VERSION ""

NS_ :

BS_:

BU_: RS01 SODFR SODFL SODRL SODRR SODRC
VAL_TABLE_ RS01_VEHICLE_PLATFORM 14 "RR12" 13 "RR11" 12 "G38_MSP" 11 "G38" 10 "G32_MSP" 9 "G32" 8 "G31_MSP" 7 "G31" 6 "G30_MSP" 5 "G30" 4 "G12_MSP" 3 "G12" 2 "G11_MSP" 1 "G11" 0 "G01" ;
VAL_TABLE_ CAN_TX_SW_VERSION_DSP 71426 "2.23.1" 71170 "2.22.1" 5890 "2.23" ;
VAL_TABLE_ CAN_TX_SW_VERSION_ARM 66827 "1.5.11" 66826 "1.5.10" ;
VAL_TABLE_ AUTO_ALIGN_QUALITY_FACTOR 3 "ALIGN_QUALITY_FACTOR_INACCURATE" 2 "ALIGN_QUALITY_FACTOR_FAULTY" 1 "ALIGN_QUALITY_FACTOR_ACCURATE" 0 "ALIGN_QUALITY_FACTOR_UNKNOWN " ;
VAL_TABLE_ AUTO_ALIGN_MODE 7 "ALIGN_MODE_OVERWRITE" 6 "ALIGN_MODE_STATIONARY_ALIGNMENT" 5 "ALIGN_MODE_RESUME_SPC" 4 "ALIGN_MODE_SERVICE" 3 "ALIGN_MODE_SHORT_TRACK" 2 "ALIGN_MODE_AUTO" 1 "ALIGN_MODE_INIT" 0 "ALIGN_MODE_OFF" ;
VAL_TABLE_ LANE_CALC_METHOD 6 "LANE_CALC_CAMERA_FALLBACK_DEF" 5 "LANE_CALC_CAMERA_FALLBACK_EXT" 4 "LANE_CALC_CAMERA_FALLBACK_BASIC" 3 "LANE_CALC_CAMERA" 2 "LANE_CALC_EXTENDED" 1 "LANE_CALC_BASIC" 0 "LANE_CALC_METHOD_DEFAULT" ;
VAL_TABLE_ Radiation_Control 2 "Radiation Automatic" 1 "Radiation ON" 0 "Radiation OFF" ;
VAL_TABLE_ DRIVING_ENVIRONMENT 2 "RURAL" 1 "CITY" 0 "Unknown" ;
VAL_TABLE_ RS01_FUNCTION_STATUS 3 "ERROR" 2 "DEGRADED" 1 "NORMAL_OPERATION" 0 "STANDBY" ;
VAL_TABLE_ RS01_SYSTEM_STATUS 3 "POWERDOWN" 2 "SYSTEMUP" 1 "STARTUP/ INIT" 0 "OFF" ;
VAL_TABLE_ Quality_Factor_T 3 "Accurate" 2 "Not Accurate" 1 "Temp Undefined" 0 "Undefined" ;
VAL_TABLE_ System_Status_T 6 "Hot" 5 "ShutDown" 4 "Faulty" 3 "Blocked" 2 "Running" 1 "StartUp" 0 "Configuration" ;
VAL_TABLE_ ARM_diagnostic_byte7 7 "Num errors" 6 "Always true" 5 "cal DSP obsolete=62 error" ;
VAL_TABLE_ ARM_diagnostic_byte5 2 "Interrupt enable error" 1 "HIL format error" 0 "MMAP memroy error" ;
VAL_TABLE_ ARM_diagnostic_byte4 7 "Socket write error" 6 "Socket rear error" 5 "Socket init error" 4 "ISR attach error" 3 "DSP load address error" 2 "DSP load read error" 1 "DSP load open error" 0 "DSP init error" ;
VAL_TABLE_ ARM_diagnostic_byte3 7 "IPC DRV trigger error" 6 "IPC DRV sync error" 5 "IPC DRV write error" 4 "IPC DRV read error" 3 "IPC DRV init error" 2 "DSP DRV start error" 1 "DSP DRV load error" 0 "DSP DRV init2 error" ;
VAL_TABLE_ ARM_diagnostic_byte2 7 "DSP DRV init1 error" 6 "DSP DRV init error" 5 "Shared memory write error" 4 "Shared memory read error" 3 "Shared memory config error" 2 "Shared memory init error" 1 "DSP IPC write error" 0 "DSP IPC read error" ;
VAL_TABLE_ ARM_diagnostic_byte1 7 "DSP IPC Init" 6 "SPI FEE error" 5 "SPI comm error" 4 "CAN hardware error" 3 "CAN rcv error" 2 "CAN XMT error" 1 "ARM calibration error" 0 "DSP calibration error" ;
VAL_TABLE_ ARM_diagnostic_byte0 7 "flash filesystem error" 6 "timer create error" 5 "signal send error" 4 "signal wait error" 3 "signal create error" 2 "thread create error" 1 "ram test error" 0 "error none" ;
VAL_TABLE_ DSP_Diagnostics_byte2 7 "Video Port data capture error" 6 "TX temperature fault" 5 "DSP unit cal block fault" 4 "DSP unit cal checksum error" 3 "Vertical misalignment error" 2 "RTN SPI transfer error" 1 "RRN SPI transfer error" 0 "Linearizer SPI transfer error" ;
VAL_TABLE_ DSP_Diagnostics_byte1 7 "ADC SPI transfer error" 6 "transmitter ID error" 5 "DSP loop overrun error" 4 "saturated tuning frquency error" 3 "radar data sync error" 2 "DSP Tuning Sensitivity error" 1 "radar LO power error" 0 "Radar_tx_power_error" ;
VAL_TABLE_ GroupingChanged 1 "GroupingChanged" 0 "GroupingUnchanged" ;
VAL_TABLE_ Oncoming 1 "Oncoming" 0 "NotOncoming" ;
VAL_TABLE_ UPDATED 1 "Updated" 0 "Not_Updated" ;
VAL_TABLE_ FOUND_TARGET 1 "Found" 0 "Not_Found" ;
VAL_TABLE_ FACTORY_ALIGN_STATUS 5 "FAIL_VAR_TOO_LARGE" 4 "FAIL_DEV_TOO_LARGE" 3 "FAIL_NO_TARGET" 2 "SUCCESS" 1 "BUSY" 0 "OFF" ;
VAL_TABLE_ RECOMMEND 1 "Recommend" 0 "Not_Recommend" ;
VAL_TABLE_ SA_TYPE 1 "VOLVO_SHORT_TRACK" 0 "AUTO_OR_DEALER" ;
VAL_TABLE_ ENABLE 1 "Enabled" 0 "Disabled" ;
VAL_TABLE_ CONVERGED 1 "Converged" 0 "Not_Converged" ;
VAL_TABLE_ TURN_SIGNAL_STATUS 3 "Invalid_3" 2 "Right" 1 "Left" 0 "Off" ;
VAL_TABLE_ DISABLE 1 "Disabled" 0 "Enabled" ;
VAL_TABLE_ SYSTEM_POWER_MODE 7 "7invalid" 6 "TEST" 5 "HOST_SHUTDOWN" 4 "DSP_OFF" 3 "DSP_SHUTDOWN" 2 "RADIATE_ON" 1 "RADIATE_OFF" 0 "DSP_INIT" ;
VAL_TABLE_ Water_Spray_Detected 1 "Spray" 0 "No_Spray" ;
VAL_TABLE_ Bridge 1 "Bridge" 0 "Not_Bridge" ;
VAL_TABLE_ MED_RANGE_MODE 3 "Both_MR_LR_Update" 2 "LR_Update_Only" 1 "MR_Update_Only" 0 "No_MR_LR_Update" ;
VAL_TABLE_ Interface_Version 15 "zInvalid0F" 14 "zInvalid0E" 13 "zInvalid0D" 12 "zInvalid0C" 11 "zInvalid0B" 10 "zInvalid0A" 9 "zInvalid09" 8 "zInvalid08" 7 "zInvalid07" 6 "zInvalid06" 5 "zInvalid05" 4 "zInvalid04" 3 "zInvalid03" 2 "zInvalid02" 1 "ADP_DV1" 0 "TDP" ;
VAL_TABLE_ SIM_STATUS 3 "Coasted" 2 "Updated" 1 "New" 0 "Invalid" ;
VAL_TABLE_ SIM_TRACK_ID 2 "Target_2" 1 "Target_1" 0 "No_Target" ;
VAL_TABLE_ SIM_FUNCTION 7 "All_Stat_RI_FCW_CMbB" 6 "All_Moving_ACC_FCW_CMbB" 5 "CMbB_Stat" 4 "CMbB_Move" 3 "FCW_Stat" 2 "FCW_Move" 1 "RI" 0 "ACC" ;
VAL_TABLE_ UPSIDE_DOWN 1 "Upside_Down" 0 "Right_Side_Up" ;
VAL_TABLE_ MR_LR_MODE 3 "Output MR and LR tracks" 2 "Output only LR-range tracks" 1 "Output only MR-range tracks" 0 "Reserved" ;
VAL_TABLE_ GROUP 3 "Group4" 2 "Group3" 1 "Group2" 0 "Group1" ;
VAL_TABLE_ NODETECT_DETECT 1 "Detect" 0 "No_Detect" ;
VAL_TABLE_ TRACK_STATUS 7 "New_Coasted_Target" 6 "Invalid_Coasted_Target" 5 "Merged_Target" 4 "Coasted_Target" 3 "Updated_Target" 2 "New_Updated_Target" 1 "New_Target" 0 "No_Target" ;
VAL_TABLE_ NOTCROSSING_CROSSING 1 "Crossing" 0 "Not_Crossing" ;
VAL_TABLE_ NOTMOVABLE_MOVABLE 1 "Movable" 0 "Not_Movable" ;
VAL_TABLE_ STATIONARY_MOVING 1 "Moving" 0 "Stationary" ;
VAL_TABLE_ NOTOVERTEMP_OVERTEMP 1 "OverTemp" 0 "Not OverTemp" ;
VAL_TABLE_ NOTBLOCKED_BLOCKED 1 "Blocked" 0 "Not Blocked" ;
VAL_TABLE_ NOTFAIL_FAIL 1 "Failed" 0 "Not Failed" ;
VAL_TABLE_ UNGROUPED_GROUPED 3 "Group_Moving_Stationary" 2 "Group_Stationary_Only" 1 "Group_Moving_Only" 0 "No_Grouping" ;
VAL_TABLE_ FILTERED_RAW 1 "Raw" 0 "Filtered" ;
VAL_TABLE_ OFF_ON 1 "On" 0 "Off" ;
VAL_TABLE_ SW_SIGN 1 "Clockwise" 0 "Counterclockwise" ;
VAL_TABLE_ VALIDITY 1 "Valid" 0 "Invalid" ;
VAL_TABLE_ VEHICLE_SPEED_DIRECTION 1 "Reverse" 0 "Forward" ;
VAL_TABLE_ STATUS_PRECRASH_TABLE 4 "Collision unavoidable" 2 "Collision probable" 1 "Collision avoidable" 0 "no relevant Object" ;
VAL_TABLE_ STATUS_RECW_TABLE 1 "Warning active" 0 "No Warning" ;
VAL_TABLE_ TRIGGER_SENSOR 0 "INVALID_TRIGGER" 1 "TRIGGERED_BY_REAR_LEFT" 2 "TRIGGERED_BY_REAR_RIGHT" 3 "TRIGGERED_BY_FRONT_RIGHT" 4 "TRIGGERED_BY_FRONT_LEFT" 5 "TRIGGERED_BY_REAR_CENTER" 6 "TRIGGERED_BY_DSP" ;

BO_ 3221225472 VECTOR__INDEPENDENT_SIG_MSG: 0 Vector__XXX
 SG_ CAN_TX_LOOK_TYPE : 0|1@0+ (1,0) [0|0] "" Vector__XXX
 SG_ CAN_TX_SYSTEM_SYNC_TIME : 0|32@0+ (1,0) [0|0] "" Vector__XXX
 SG_ ITS_DAQ1_data : 0|64@0+ (1,0) [0|0] "" Vector__XXX
 SG_ CAN_RX_MR_LR_MODE : 0|2@0+ (1,0) [0|3] "" Vector__XXX
 SG_ CAN_TX_DELTA_TIME_STAMP : 0|7@0- (1,0) [-64|63] "ms" Vector__XXX
 SG_ CAN_RX_MASTER_CLOCK : 0|16@0+ (1,0) [0|65535] "ms" Vector__XXX
 SG_ CAN_TX_WATER_SPRAY_TARGET_ID : 0|8@0+ (1,0) [0|0] "" Vector__XXX
 SG_ CAN_TX_TRACK_LAT_RATE : 0|6@0- (0.25,0) [-8|7.75] "" Vector__XXX
 SG_ CAN_TX_TRACK_BRIDGE_OBJECT : 0|1@0+ (1,0) [0|0] "" Vector__XXX
 SG_ CAN_TX_TRACK_WIDTH : 0|4@0+ (0.5,0) [0|7.5] "m" Vector__XXX
 SG_ CAN_TX_TRACK_STATUS : 0|3@0+ (1,0) [0|7] "" Vector__XXX
 SG_ CAN_TX_TRACK_RANGE_RATE : 0|14@0- (0.01,0) [-81.92|81.91] "m/s" Vector__XXX
 SG_ CAN_TX_TRACK_RANGE : 0|11@0+ (0.1,0) [0|204.7] "m" Vector__XXX
 SG_ CAN_TX_TRACK_MED_RANGE_MODE : 0|2@0+ (1,0) [0|3] "" Vector__XXX
 SG_ CAN_TX_TRACK_GROUPING_CHANGED : 0|1@0+ (1,0) [0|0] "" Vector__XXX
 SG_ CAN_TX_TRACK_ONCOMING : 0|1@0+ (1,0) [0|0] "" Vector__XXX
 SG_ CTA_Aware : 0|2@0+ (1,0) [0|0] "binary" Vector__XXX
 SG_ CAN_TX_TRACK_ROLLING_COUNT : 0|1@0+ (1,0) [0|1] "" Vector__XXX
 SG_ CAN_TX_TRACK_RANGE_ACCEL : 0|10@0- (0.05,0) [-25.6|25.55] "m/s/s" Vector__XXX
 SG_ CAN_TX_ROLLING_COUNT_3 : 0|2@0+ (1,0) [0|0] "" Vector__XXX
 SG_ CAN_TX_ROLLING_COUNT_3 : 0|2@0+ (1,0) [0|0] "" Vector__XXX
 SG_ CAN_TX_ROLLING_COUNT_1 : 0|2@0+ (1,0) [0|0] "" Vector__XXX
 SG_ DSP_diagnostic_byte2 : 0|8@0+ (1,0) [0|0] "" Vector__XXX
 SG_ DSP_diagnostic_byte1 : 0|8@0+ (1,0) [0|0] "" Vector__XXX
 SG_ DSP_diagnostic_byte2 : 0|8@0+ (1,0) [0|0] "" Vector__XXX
 SG_ DSP_diagnostic_byte1 : 0|8@0+ (1,0) [0|0] "" Vector__XXX
 SG_ New_Signal_1125 : 0|8@1+ (1,0) [0|0] "" Vector__XXX
 SG_ New_Signal_1124 : 0|8@1+ (1,0) [0|0] "" Vector__XXX
 SG_ New_Signal_1123 : 0|8@1+ (1,0) [0|0] "" Vector__XXX
 SG_ CAN_TX_DSP_TIMESTAMP : 0|16@0+ (2,0) [0|131070] "ms" Vector__XXX
 SG_ CAN_TX_DSP_TIMESTAMP : 0|16@0+ (2,0) [0|131070] "ms" Vector__XXX
 SG_ Timer_Create_Error : 0|1@0+ (1,0) [0|0] "" Vector__XXX
 SG_ Thread_Create_Error : 0|1@0+ (1,0) [0|0] "" Vector__XXX
 SG_ ARM_Calibration_Error : 0|1@0+ (1,0) [0|0] "" Vector__XXX
 SG_ SPI_FEE_Error : 0|1@0+ (1,0) [0|0] "" Vector__XXX
 SG_ SPI_Comm_Error : 0|1@0+ (1,0) [0|0] "" Vector__XXX
 SG_ Socket_Write_Error : 0|1@0+ (1,0) [0|0] "" Vector__XXX
 SG_ DSP_Cal_Obsolete_62_Error : 0|1@0+ (1,0) [0|0] "" Vector__XXX
 SG_ Socket_Read_error : 0|1@0+ (1,0) [0|0] "" Vector__XXX
 SG_ Socket_Init_Error : 0|1@0+ (1,0) [0|0] "" Vector__XXX
 SG_ Signal_Wait_Error : 0|1@0+ (1,0) [0|0] "" Vector__XXX
 SG_ Signal_Send_Error : 0|1@0+ (1,0) [0|0] "" Vector__XXX
 SG_ Signal_Create_Error : 0|1@0+ (1,0) [0|0] "" Vector__XXX
 SG_ Shared_Mem_Write_Error : 0|1@0+ (1,0) [0|0] "" Vector__XXX
 SG_ Shared_Mem_Read_Error : 0|1@0+ (1,0) [0|0] "" Vector__XXX
 SG_ Shared_Mem_Config_Error : 0|1@0+ (1,0) [0|0] "" Vector__XXX
 SG_ Share_Mem_Init_Error : 0|1@0+ (1,0) [0|0] "" Vector__XXX
 SG_ RAM_Test_Error : 0|1@0+ (1,0) [0|0] "" Vector__XXX
 SG_ Num_Errors : 0|1@0+ (1,0) [0|0] "" Vector__XXX
 SG_ MMAP_Memory_Error : 0|1@0+ (1,0) [0|0] "" Vector__XXX
 SG_ ISR_Attach_Error : 0|1@0+ (1,0) [0|0] "" Vector__XXX
 SG_ IPC_DRV_Write_Error : 0|1@0+ (1,0) [0|0] "" Vector__XXX
 SG_ IPC_DRV_Trigger_Error : 0|1@0+ (1,0) [0|0] "" Vector__XXX
 SG_ IPC_DRV_Sync_Error : 0|1@0+ (1,0) [0|0] "" Vector__XXX
 SG_ IPC_DRV_Read_Error : 0|1@0+ (1,0) [0|0] "" Vector__XXX
 SG_ IPC_DRV_Init_Error : 0|1@0+ (1,0) [0|0] "" Vector__XXX
 SG_ Interrupt_Enable_Error : 0|1@0+ (1,0) [0|0] "" Vector__XXX
 SG_ HIL_Format_Error : 0|1@0+ (1,0) [0|0] "" Vector__XXX
 SG_ Flash_Filesystem_Error : 0|1@0+ (1,0) [0|0] "" Vector__XXX
 SG_ Error_none : 0|1@0+ (1,0) [0|0] "" Vector__XXX
 SG_ DSP_Load_Read_Error : 0|1@0+ (1,0) [0|0] "" Vector__XXX
 SG_ DSP_Load_Open_Error : 0|1@0+ (1,0) [0|0] "" Vector__XXX
 SG_ DSP_Load_Address_Error : 0|1@0+ (1,0) [0|0] "" Vector__XXX
 SG_ DSP_ISP_Write_Error : 0|1@0+ (1,0) [0|0] "" Vector__XXX
 SG_ DSP_IPC_Read_Error : 0|1@0+ (1,0) [0|0] "" Vector__XXX
 SG_ DSP_IPC_Init : 0|1@0+ (1,0) [0|0] "" Vector__XXX
 SG_ DSP_Init_Error : 0|1@0+ (1,0) [0|0] "" Vector__XXX
 SG_ DSP_DRV_Start_Error : 0|1@0+ (1,0) [0|0] "" Vector__XXX
 SG_ DSP_DRV_Load_Error : 0|1@0+ (1,0) [0|0] "" Vector__XXX
 SG_ DSP_DRV_Init_Error : 0|1@0+ (1,0) [0|0] "" Vector__XXX
 SG_ DSP_DRV_Init2_error : 0|1@0+ (1,0) [0|0] "" Vector__XXX
 SG_ DSP_DRV_Init1_error : 0|1@0+ (1,0) [0|0] "" Vector__XXX
 SG_ DSP_Calibration_Error : 0|1@0+ (1,0) [0|0] "" Vector__XXX
 SG_ CAN_XMT_Error : 0|1@0+ (1,0) [0|0] "" Vector__XXX
 SG_ CAN_RCV_Error : 0|1@0+ (1,0) [0|0] "" Vector__XXX
 SG_ CAN_Hardware_Error : 0|1@0+ (1,0) [0|0] "" Vector__XXX
 SG_ Always_True : 0|1@0+ (1,0) [0|0] "" Vector__XXX
 SG_ Timer_Create_Error : 0|1@0+ (1,0) [0|0] "" Vector__XXX
 SG_ Thread_Create_Error : 0|1@0+ (1,0) [0|0] "" Vector__XXX
 SG_ ARM_Calibration_Error : 0|1@0+ (1,0) [0|0] "" Vector__XXX
 SG_ SPI_FEE_Error : 0|1@0+ (1,0) [0|0] "" Vector__XXX
 SG_ SPI_Comm_Error : 0|1@0+ (1,0) [0|0] "" Vector__XXX
 SG_ Socket_Write_Error : 0|1@0+ (1,0) [0|0] "" Vector__XXX
 SG_ DSP_Cal_Obsolete_62_Error : 0|1@0+ (1,0) [0|0] "" Vector__XXX
 SG_ Socket_Read_error : 0|1@0+ (1,0) [0|0] "" Vector__XXX
 SG_ Socket_Init_Error : 0|1@0+ (1,0) [0|0] "" Vector__XXX
 SG_ Signal_Wait_Error : 0|1@0+ (1,0) [0|0] "" Vector__XXX
 SG_ Signal_Send_Error : 0|1@0+ (1,0) [0|0] "" Vector__XXX
 SG_ Signal_Create_Error : 0|1@0+ (1,0) [0|0] "" Vector__XXX
 SG_ Shared_Mem_Write_Error : 0|1@0+ (1,0) [0|0] "" Vector__XXX
 SG_ Shared_Mem_Read_Error : 0|1@0+ (1,0) [0|0] "" Vector__XXX
 SG_ Shared_Mem_Config_Error : 0|1@0+ (1,0) [0|0] "" Vector__XXX
 SG_ Share_Mem_Init_Error : 0|1@0+ (1,0) [0|0] "" Vector__XXX
 SG_ RAM_Test_Error : 0|1@0+ (1,0) [0|0] "" Vector__XXX
 SG_ Num_Errors : 0|1@0+ (1,0) [0|0] "" Vector__XXX
 SG_ MMAP_Memory_Error : 0|1@0+ (1,0) [0|0] "" Vector__XXX
 SG_ ISR_Attach_Error : 0|1@0+ (1,0) [0|0] "" Vector__XXX
 SG_ IPC_DRV_Write_Error : 0|1@0+ (1,0) [0|0] "" Vector__XXX
 SG_ IPC_DRV_Trigger_Error : 0|1@0+ (1,0) [0|0] "" Vector__XXX
 SG_ IPC_DRV_Sync_Error : 0|1@0+ (1,0) [0|0] "" Vector__XXX
 SG_ IPC_DRV_Read_Error : 0|1@0+ (1,0) [0|0] "" Vector__XXX
 SG_ IPC_DRV_Init_Error : 0|1@0+ (1,0) [0|0] "" Vector__XXX
 SG_ Interrupt_Enable_Error : 0|1@0+ (1,0) [0|0] "" Vector__XXX
 SG_ HIL_Format_Error : 0|1@0+ (1,0) [0|0] "" Vector__XXX
 SG_ Flash_Filesystem_Error : 0|1@0+ (1,0) [0|0] "" Vector__XXX
 SG_ Error_none : 0|1@0+ (1,0) [0|0] "" Vector__XXX
 SG_ DSP_Load_Read_Error : 0|1@0+ (1,0) [0|0] "" Vector__XXX
 SG_ DSP_Load_Open_Error : 0|1@0+ (1,0) [0|0] "" Vector__XXX
 SG_ DSP_Load_Address_Error : 0|1@0+ (1,0) [0|0] "" Vector__XXX
 SG_ DSP_ISP_Write_Error : 0|1@0+ (1,0) [0|0] "" Vector__XXX
 SG_ DSP_IPC_Read_Error : 0|1@0+ (1,0) [0|0] "" Vector__XXX
 SG_ DSP_IPC_Init : 0|1@0+ (1,0) [0|0] "" Vector__XXX
 SG_ DSP_Init_Error : 0|1@0+ (1,0) [0|0] "" Vector__XXX
 SG_ DSP_DRV_Start_Error : 0|1@0+ (1,0) [0|0] "" Vector__XXX
 SG_ DSP_DRV_Load_Error : 0|1@0+ (1,0) [0|0] "" Vector__XXX
 SG_ DSP_DRV_Init_Error : 0|1@0+ (1,0) [0|0] "" Vector__XXX
 SG_ DSP_DRV_Init2_error : 0|1@0+ (1,0) [0|0] "" Vector__XXX
 SG_ DSP_DRV_Init1_error : 0|1@0+ (1,0) [0|0] "" Vector__XXX
 SG_ DSP_Calibration_Error : 0|1@0+ (1,0) [0|0] "" Vector__XXX
 SG_ CAN_XMT_Error : 0|1@0+ (1,0) [0|0] "" Vector__XXX
 SG_ CAN_RCV_Error : 0|1@0+ (1,0) [0|0] "" Vector__XXX
 SG_ CAN_Hardware_Error : 0|1@0+ (1,0) [0|0] "" Vector__XXX
 SG_ Always_True : 0|1@0+ (1,0) [0|0] "" Vector__XXX
 SG_ Timer_Create_Error : 0|1@0+ (1,0) [0|0] "" Vector__XXX
 SG_ Thread_Create_Error : 0|1@0+ (1,0) [0|0] "" Vector__XXX
 SG_ ARM_Calibration_Error : 0|1@0+ (1,0) [0|0] "" Vector__XXX
 SG_ SPI_FEE_Error : 0|1@0+ (1,0) [0|0] "" Vector__XXX
 SG_ SPI_Comm_Error : 0|1@0+ (1,0) [0|0] "" Vector__XXX
 SG_ Socket_Write_Error : 0|1@0+ (1,0) [0|0] "" Vector__XXX
 SG_ DSP_Cal_Obsolete_62_Error : 0|1@0+ (1,0) [0|0] "" Vector__XXX
 SG_ Socket_Read_error : 0|1@0+ (1,0) [0|0] "" Vector__XXX
 SG_ Socket_Init_Error : 0|1@0+ (1,0) [0|0] "" Vector__XXX
 SG_ Signal_Wait_Error : 0|1@0+ (1,0) [0|0] "" Vector__XXX
 SG_ Signal_Send_Error : 0|1@0+ (1,0) [0|0] "" Vector__XXX
 SG_ Signal_Create_Error : 0|1@0+ (1,0) [0|0] "" Vector__XXX
 SG_ Shared_Mem_Write_Error : 0|1@0+ (1,0) [0|0] "" Vector__XXX
 SG_ Shared_Mem_Read_Error : 0|1@0+ (1,0) [0|0] "" Vector__XXX
 SG_ Shared_Mem_Config_Error : 0|1@0+ (1,0) [0|0] "" Vector__XXX
 SG_ Share_Mem_Init_Error : 0|1@0+ (1,0) [0|0] "" Vector__XXX
 SG_ RAM_Test_Error : 0|1@0+ (1,0) [0|0] "" Vector__XXX
 SG_ Num_Errors : 0|1@0+ (1,0) [0|0] "" Vector__XXX
 SG_ MMAP_Memory_Error : 0|1@0+ (1,0) [0|0] "" Vector__XXX
 SG_ ISR_Attach_Error : 0|1@0+ (1,0) [0|0] "" Vector__XXX
 SG_ IPC_DRV_Write_Error : 0|1@0+ (1,0) [0|0] "" Vector__XXX
 SG_ IPC_DRV_Trigger_Error : 0|1@0+ (1,0) [0|0] "" Vector__XXX
 SG_ IPC_DRV_Sync_Error : 0|1@0+ (1,0) [0|0] "" Vector__XXX
 SG_ IPC_DRV_Read_Error : 0|1@0+ (1,0) [0|0] "" Vector__XXX
 SG_ IPC_DRV_Init_Error : 0|1@0+ (1,0) [0|0] "" Vector__XXX
 SG_ Interrupt_Enable_Error : 0|1@0+ (1,0) [0|0] "" Vector__XXX
 SG_ HIL_Format_Error : 0|1@0+ (1,0) [0|0] "" Vector__XXX
 SG_ Flash_Filesystem_Error : 0|1@0+ (1,0) [0|0] "" Vector__XXX
 SG_ Error_none : 0|1@0+ (1,0) [0|0] "" Vector__XXX
 SG_ DSP_Load_Read_Error : 0|1@0+ (1,0) [0|0] "" Vector__XXX
 SG_ DSP_Load_Open_Error : 0|1@0+ (1,0) [0|0] "" Vector__XXX
 SG_ DSP_Load_Address_Error : 0|1@0+ (1,0) [0|0] "" Vector__XXX
 SG_ DSP_ISP_Write_Error : 0|1@0+ (1,0) [0|0] "" Vector__XXX
 SG_ DSP_IPC_Read_Error : 0|1@0+ (1,0) [0|0] "" Vector__XXX
 SG_ DSP_IPC_Init : 0|1@0+ (1,0) [0|0] "" Vector__XXX
 SG_ DSP_Init_Error : 0|1@0+ (1,0) [0|0] "" Vector__XXX
 SG_ DSP_DRV_Start_Error : 0|1@0+ (1,0) [0|0] "" Vector__XXX
 SG_ DSP_DRV_Load_Error : 0|1@0+ (1,0) [0|0] "" Vector__XXX
 SG_ DSP_DRV_Init_Error : 0|1@0+ (1,0) [0|0] "" Vector__XXX
 SG_ DSP_DRV_Init2_error : 0|1@0+ (1,0) [0|0] "" Vector__XXX
 SG_ DSP_DRV_Init1_error : 0|1@0+ (1,0) [0|0] "" Vector__XXX
 SG_ DSP_Calibration_Error : 0|1@0+ (1,0) [0|0] "" Vector__XXX
 SG_ CAN_XMT_Error : 0|1@0+ (1,0) [0|0] "" Vector__XXX
 SG_ CAN_RCV_Error : 0|1@0+ (1,0) [0|0] "" Vector__XXX
 SG_ CAN_Hardware_Error : 0|1@0+ (1,0) [0|0] "" Vector__XXX
 SG_ Always_True : 0|1@0+ (1,0) [0|0] "" Vector__XXX
 SG_ CAN_TX_ALIGN_UPDATES : 0|16@0+ (1,0) [0|0] "" Vector__XXX
 SG_ CAN_TX_ALIGN_UPDATES : 0|16@0+ (1,0) [0|0] "" Vector__XXX
 SG_ Timer_Create_Error : 0|1@0+ (1,0) [0|0] "" Vector__XXX
 SG_ Thread_Create_Error : 0|1@0+ (1,0) [0|0] "" Vector__XXX
 SG_ ARM_Calibration_Error : 0|1@0+ (1,0) [0|0] "" Vector__XXX
 SG_ SPI_FEE_Error : 0|1@0+ (1,0) [0|0] "" Vector__XXX
 SG_ SPI_Comm_Error : 0|1@0+ (1,0) [0|0] "" Vector__XXX
 SG_ Socket_Write_Error : 0|1@0+ (1,0) [0|0] "" Vector__XXX
 SG_ DSP_Cal_Obsolete_62_Error : 0|1@0+ (1,0) [0|0] "" Vector__XXX
 SG_ Socket_Read_error : 0|1@0+ (1,0) [0|0] "" Vector__XXX
 SG_ Socket_Init_Error : 0|1@0+ (1,0) [0|0] "" Vector__XXX
 SG_ Signal_Wait_Error : 0|1@0+ (1,0) [0|0] "" Vector__XXX
 SG_ Signal_Send_Error : 0|1@0+ (1,0) [0|0] "" Vector__XXX
 SG_ Signal_Create_Error : 0|1@0+ (1,0) [0|0] "" Vector__XXX
 SG_ Shared_Mem_Write_Error : 0|1@0+ (1,0) [0|0] "" Vector__XXX
 SG_ Shared_Mem_Read_Error : 0|1@0+ (1,0) [0|0] "" Vector__XXX
 SG_ Shared_Mem_Config_Error : 0|1@0+ (1,0) [0|0] "" Vector__XXX
 SG_ Share_Mem_Init_Error : 0|1@0+ (1,0) [0|0] "" Vector__XXX
 SG_ RAM_Test_Error : 0|1@0+ (1,0) [0|0] "" Vector__XXX
 SG_ Num_Errors : 0|1@0+ (1,0) [0|0] "" Vector__XXX
 SG_ MMAP_Memory_Error : 0|1@0+ (1,0) [0|0] "" Vector__XXX
 SG_ ISR_Attach_Error : 0|1@0+ (1,0) [0|0] "" Vector__XXX
 SG_ IPC_DRV_Write_Error : 0|1@0+ (1,0) [0|0] "" Vector__XXX
 SG_ IPC_DRV_Trigger_Error : 0|1@0+ (1,0) [0|0] "" Vector__XXX
 SG_ IPC_DRV_Sync_Error : 0|1@0+ (1,0) [0|0] "" Vector__XXX
 SG_ IPC_DRV_Read_Error : 0|1@0+ (1,0) [0|0] "" Vector__XXX
 SG_ IPC_DRV_Init_Error : 0|1@0+ (1,0) [0|0] "" Vector__XXX
 SG_ Interrupt_Enable_Error : 0|1@0+ (1,0) [0|0] "" Vector__XXX
 SG_ HIL_Format_Error : 0|1@0+ (1,0) [0|0] "" Vector__XXX
 SG_ Flash_Filesystem_Error : 0|1@0+ (1,0) [0|0] "" Vector__XXX
 SG_ Error_none : 0|1@0+ (1,0) [0|0] "" Vector__XXX
 SG_ DSP_Load_Read_Error : 0|1@0+ (1,0) [0|0] "" Vector__XXX
 SG_ DSP_Load_Open_Error : 0|1@0+ (1,0) [0|0] "" Vector__XXX
 SG_ DSP_Load_Address_Error : 0|1@0+ (1,0) [0|0] "" Vector__XXX
 SG_ DSP_ISP_Write_Error : 0|1@0+ (1,0) [0|0] "" Vector__XXX
 SG_ DSP_IPC_Read_Error : 0|1@0+ (1,0) [0|0] "" Vector__XXX
 SG_ DSP_IPC_Init : 0|1@0+ (1,0) [0|0] "" Vector__XXX
 SG_ DSP_Init_Error : 0|1@0+ (1,0) [0|0] "" Vector__XXX
 SG_ DSP_DRV_Start_Error : 0|1@0+ (1,0) [0|0] "" Vector__XXX
 SG_ DSP_DRV_Load_Error : 0|1@0+ (1,0) [0|0] "" Vector__XXX
 SG_ DSP_DRV_Init_Error : 0|1@0+ (1,0) [0|0] "" Vector__XXX
 SG_ DSP_DRV_Init2_error : 0|1@0+ (1,0) [0|0] "" Vector__XXX
 SG_ DSP_DRV_Init1_error : 0|1@0+ (1,0) [0|0] "" Vector__XXX
 SG_ DSP_Calibration_Error : 0|1@0+ (1,0) [0|0] "" Vector__XXX
 SG_ CAN_XMT_Error : 0|1@0+ (1,0) [0|0] "" Vector__XXX
 SG_ CAN_RCV_Error : 0|1@0+ (1,0) [0|0] "" Vector__XXX
 SG_ CAN_Hardware_Error : 0|1@0+ (1,0) [0|0] "" Vector__XXX
 SG_ Always_True : 0|1@0+ (1,0) [0|0] "" Vector__XXX
 SG_ CAN_TX_YAW_RATE_REF_QF : 0|2@0+ (1,0) [0|0] "" Vector__XXX
 SG_ CAN_TX_YAW_RATE_RAW_QF : 0|2@0+ (1,0) [0|0] "" Vector__XXX
 SG_ CAN_TX_YAW_RATE_REFERENCE : 0|12@0- (0.0625,0) [-128|127.9375] "deg/s" Vector__XXX
 SG_ CAN_TX_YAW_RATE_RAW : 0|12@0- (0.0625,0) [-128|127.9375] "deg/s" Vector__XXX
 SG_ CAN_TX_SYSTEM_STATUS : 0|3@0+ (1,0) [0|0] "" Vector__XXX
 SG_ CAN_TX_OUTSIDE_TEMPERATURE : 0|8@0+ (1,-40) [-40|215] "degC" Vector__XXX
 SG_ CAN_BLOCKAGE_MNR_BLOCKED : 0|1@0+ (1,0) [0|0] "" Vector__XXX
 SG_ CAN_BLOCKAGE_BB_BLOCKED : 0|1@0+ (1,0) [0|0] "" Vector__XXX
 SG_ CAN_BLOCKAGE_RADAR_BLOCKED : 0|1@0+ (1,0) [0|0] "" Vector__XXX
 SG_ CAN_TD_BLOCKED : 0|1@0+ (1,0) [0|0] "" Vector__XXX
 SG_ Radar_TX_Power_Error : 0|1@0+ (1,0) [0|0] "" Vector__XXX
 SG_ Radar_LO_Power_Error : 0|1@0+ (1,0) [0|0] "" Vector__XXX
 SG_ Radar_Data_sync_error : 0|1@0+ (1,0) [0|0] "" Vector__XXX
 SG_ Linearizer_SPI_Transfer_Error : 0|1@0+ (1,0) [0|0] "" Vector__XXX
 SG_ Saturated_Tuning_Freq_Error : 0|1@0+ (1,0) [0|0] "" Vector__XXX
 SG_ RTN_SPI_Transfer_Error : 0|1@0+ (1,0) [0|0] "" Vector__XXX
 SG_ RRN_SPI_Transfer_Error : 0|1@0+ (1,0) [0|0] "" Vector__XXX
 SG_ Video_Port_Capture_Error : 0|1@0+ (1,0) [0|0] "" Vector__XXX
 SG_ Vertical_Misalignment_error : 0|1@0+ (1,0) [0|0] "" Vector__XXX
 SG_ TX_Temperature_Fault : 0|1@0+ (1,0) [0|0] "" Vector__XXX
 SG_ Transmitter_ID_Error : 0|1@0+ (1,0) [0|0] "" Vector__XXX
 SG_ DSP_Unit_Cal_Checksum_Error : 0|1@0+ (1,0) [0|0] "" Vector__XXX
 SG_ DSP_Unit_Cal_Block_Chcksm_Error : 0|1@0+ (1,0) [0|0] "" Vector__XXX
 SG_ DSP_Tuning_Sensitivity_Error : 0|1@0+ (1,0) [0|0] "" Vector__XXX
 SG_ ADC_SPI_Transfer_Error : 0|1@0+ (1,0) [0|0] "" Vector__XXX
 SG_ CAN_TX_YAW_RATE_REF_QF : 0|2@0+ (1,0) [0|0] "" Vector__XXX
 SG_ CAN_TX_YAW_RATE_RAW_QF : 0|2@0+ (1,0) [0|0] "" Vector__XXX
 SG_ CAN_TX_YAW_RATE_REFERENCE : 0|12@0- (0.0625,0) [-128|127.9375] "deg/s" Vector__XXX
 SG_ CAN_TX_YAW_RATE_RAW : 0|12@0- (0.0625,0) [-128|127.9375] "deg/s" Vector__XXX
 SG_ CAN_TX_SYSTEM_STATUS : 0|3@0+ (1,0) [0|0] "" Vector__XXX
 SG_ CAN_TX_OUTSIDE_TEMPERATURE : 0|8@0+ (1,-40) [-40|215] "degC" Vector__XXX
 SG_ CAN_BLOCKAGE_MNR_BLOCKED : 0|1@0+ (1,0) [0|0] "" Vector__XXX
 SG_ CAN_BLOCKAGE_BB_BLOCKED : 0|1@0+ (1,0) [0|0] "" Vector__XXX
 SG_ CAN_BLOCKAGE_RADAR_BLOCKED : 0|1@0+ (1,0) [0|0] "" Vector__XXX
 SG_ CAN_TD_BLOCKED : 0|1@0+ (1,0) [0|0] "" Vector__XXX
 SG_ Video_Port_Capture_Error : 0|1@0+ (1,0) [0|0] "" Vector__XXX
 SG_ DSP_Loop_Overrun_Error : 0|1@0+ (1,0) [0|0] "" Vector__XXX
 SG_ CAN_TX_SW_VERSION_HOST : 0|16@0+ (1,0) [0|0] "" Vector__XXX
 SG_ CAN_TX_PATH_ID_BLIS_IGNORE : 0|8@0+ (1,0) [0|0] "" Vector__XXX
 SG_ CAN_TX_PATH_ID_BLIS : 0|8@0+ (1,0) [0|0] "" Vector__XXX
 SG_ CAN_TX_ANGLE_MISALIGNMENT : 0|16@0- (0.0009765625,0) [-10|10] "" Vector__XXX
 SG_ CAN_TX_AUTO_ALIGN_ANGLE : 0|16@0- (0.0009765625,0) [-7.68|7.62] "" Vector__XXX
 SG_ CAN_TX_ALIGNMENT_STATE : 0|4@0+ (1,0) [0|0] "" Vector__XXX
 SG_ CAN_TX_INTERFACE_VER_MINOR : 0|4@0+ (1,0) [0|0] "" Vector__XXX
 SG_ CAN_TX_SW_VERSION_ARM : 0|24@0+ (1,0) [0|0] "" Vector__XXX
 SG_ CAN_TX_HW_VERSION : 0|4@0+ (1,0) [0|0] "" Vector__XXX
 SG_ CAN_TX_INTERFACE_VERSION : 0|4@0+ (1,0) [0|0] "" Vector__XXX
 SG_ CAN_TX_SERIAL_NUM : 0|24@0+ (1,0) [0|0] "" Vector__XXX
 SG_ CAN_TX_ALIGNMENT_STATUS : 0|2@0+ (1,0) [0|0] "" Vector__XXX
 SG_ CAN_TX_COMM_ERROR : 0|1@0+ (1,0) [0|0] "" Vector__XXX
 SG_ CAN_TX_STEERING_ANGLE_SIGN : 0|1@0+ (1,0) [0|1] "" Vector__XXX
 SG_ CAN_TX_YAW_RATE_BIAS : 0|8@0- (0.125,0) [-16|15.875] "" Vector__XXX
 SG_ CAN_TX_VEH_SPD_COMP_FACTOR : 0|6@0- (0.001953125,1) [0.9375|1.060546875] "" Vector__XXX
 SG_ CAN_TX_SW_VERSION_DSP : 0|16@0+ (1,0) [0|0] "" Vector__XXX
 SG_ CAN_TX_TEMPERATURE : 0|8@0+ (1,-50) [-50|205] "degC" Vector__XXX
 SG_ CAN_TX_RANGE_PERF_ERROR : 0|1@0+ (1,0) [0|0] "" Vector__XXX
 SG_ CAN_TX_OVERHEAT_ERROR : 0|1@0+ (1,0) [0|0] "" Vector__XXX
 SG_ CAN_TX_INTERNAL_ERROR : 0|1@0+ (1,0) [0|0] "" Vector__XXX
 SG_ CAN_TX_XCVR_OPERATIONAL : 0|1@0+ (1,0) [0|0] "" Vector__XXX
 SG_ CAN_TX_STEERING_ANGLE : 0|15@0+ (1,0) [0|32767] "deg" Vector__XXX
 SG_ CAN_TX_ROLLING_COUNT_2 : 0|2@0+ (1,0) [0|0] "" Vector__XXX
 SG_ CAN_TX_LOOK_TYPE : 0|1@0+ (1,0) [0|0] "" Vector__XXX
 SG_ CAN_TX_DSP_TIMESTAMP : 0|16@0+ (2,0) [0|131070] "ms" Vector__XXX
 SG_ CAN_TX_YAW_RATE_CALC : 0|12@0- (0.0625,0) [-128|127.9375] "deg/s" Vector__XXX
 SG_ CAN_TX_VEHICLE_SPEED_CALC : 0|11@0+ (0.0625,0) [0|127.9375] "m/s" Vector__XXX
 SG_ CAN_TX_SCAN_INDEX : 0|16@0+ (1,0) [0|65535] "" Vector__XXX
 SG_ CAN_TX_RADIUS_CURVATURE : 0|8@0- (25,0) [-3200|3200] "m" Vector__XXX
 SG_ CAN_TX_SW_VERSION_HOST : 0|16@0+ (1,0) [0|0] "" Vector__XXX
 SG_ CAN_TX_PATH_ID_BLIS_IGNORE : 0|8@0+ (1,0) [0|0] "" Vector__XXX
 SG_ CAN_TX_PATH_ID_BLIS : 0|8@0+ (1,0) [0|0] "" Vector__XXX
 SG_ CAN_TX_ANGLE_MISALIGNMENT : 0|16@0- (0.0009765625,0) [-10|10] "" Vector__XXX
 SG_ CAN_TX_AUTO_ALIGN_ANGLE : 0|16@0- (0.0009765625,0) [-10|10] "" Vector__XXX
 SG_ CAN_TX_ALIGNMENT_STATE : 0|4@0+ (1,0) [0|0] "" Vector__XXX
 SG_ CAN_TX_INTERFACE_VER_MINOR : 0|4@0+ (1,0) [0|0] "" Vector__XXX
 SG_ CAN_TX_SW_VERSION_ARM : 0|24@0+ (1,0) [0|0] "" Vector__XXX
 SG_ CAN_TX_HW_VERSION : 0|4@0+ (1,0) [0|0] "" Vector__XXX
 SG_ CAN_TX_INTERFACE_VERSION : 0|4@0+ (1,0) [0|0] "" Vector__XXX
 SG_ CAN_TX_SERIAL_NUM : 0|24@0+ (1,0) [0|0] "" Vector__XXX
 SG_ CAN_TX_ALIGNMENT_STATUS : 0|2@0+ (1,0) [0|0] "" Vector__XXX
 SG_ CAN_TX_COMM_ERROR : 0|1@0+ (1,0) [0|0] "" Vector__XXX
 SG_ CAN_TX_STEERING_ANGLE_SIGN : 0|1@0+ (1,0) [0|1] "" Vector__XXX
 SG_ CAN_TX_YAW_RATE_BIAS : 0|8@0- (0.125,0) [-16|15.875] "" Vector__XXX
 SG_ CAN_TX_VEH_SPD_COMP_FACTOR : 0|6@0- (0.001953125,1) [0.9375|1.060546875] "" Vector__XXX
 SG_ CAN_TX_SW_VERSION_DSP : 0|16@0+ (1,0) [0|0] "" Vector__XXX
 SG_ CAN_TX_TEMPERATURE : 0|8@0+ (1,-50) [-50|205] "degC" Vector__XXX
 SG_ CAN_TX_RANGE_PERF_ERROR : 0|1@0+ (1,0) [0|0] "" Vector__XXX
 SG_ CAN_TX_OVERHEAT_ERROR : 0|1@0+ (1,0) [0|0] "" Vector__XXX
 SG_ CAN_TX_INTERNAL_ERROR : 0|1@0+ (1,0) [0|0] "" Vector__XXX
 SG_ CAN_TX_XCVR_OPERATIONAL : 0|1@0+ (1,0) [0|0] "" Vector__XXX
 SG_ CAN_TX_STEERING_ANGLE : 0|15@0+ (1,0) [0|32767] "deg" Vector__XXX
 SG_ CAN_TX_ROLLING_COUNT_2 : 0|2@0+ (1,0) [0|0] "" Vector__XXX
 SG_ CAN_TX_LOOK_TYPE : 0|1@0+ (1,0) [0|0] "" Vector__XXX
 SG_ CAN_TX_DSP_TIMESTAMP : 0|16@0+ (2,0) [0|131070] "ms" Vector__XXX
 SG_ CAN_TX_YAW_RATE_CALC : 0|12@0- (0.0625,0) [-128|127.9375] "deg/s" Vector__XXX
 SG_ CAN_TX_VEHICLE_SPEED_CALC : 0|11@0+ (0.0625,0) [0|127.9375] "m/s" Vector__XXX
 SG_ CAN_TX_SCAN_INDEX : 0|16@0+ (1,0) [0|65535] "" Vector__XXX
 SG_ CAN_TX_RADIUS_CURVATURE : 0|8@0- (25,0) [-3200|3200] "m" Vector__XXX
 SG_ CAN_TX_SCAN_INDEX : 0|16@0+ (1,0) [0|65535] "" Vector__XXX
 SG_ CAN_TX_SCAN_INDEX : 0|16@0+ (1,0) [0|65535] "" Vector__XXX
 SG_ CAN_TX_SCAN_INDEX : 0|16@0+ (1,0) [0|65535] "" Vector__XXX
 SG_ CAN_TX_SCAN_INDEX : 0|16@0+ (1,0) [0|65535] "" Vector__XXX
 SG_ LCMA_sw_version : 0|8@0+ (1,0) [0|0] "" Vector__XXX
 SG_ CTA_sw_version : 0|8@0+ (1,0) [0|0] "" Vector__XXX
 SG_ LCMA_sw_version : 0|8@0+ (1,0) [0|0] "" Vector__XXX
 SG_ CTA_sw_version : 0|8@0+ (1,0) [0|0] "" Vector__XXX
 SG_ CAN_TX_CONVERGED_SENSOR_POSITION : 0|2@0+ (1,0) [0|0] "" Vector__XXX
 SG_ CAN_TX_CONVERGED_SENSOR_POSITION : 0|2@0+ (1,0) [0|0] "" Vector__XXX
 SG_ CAN_TX_CONVERGED_SENSOR_POSITION : 0|2@0+ (1,0) [0|0] "" Vector__XXX
 SG_ CAN_TX_CONVERGED_SENSOR_POSITION : 0|2@0+ (1,0) [0|0] "" Vector__XXX
 SG_ DSP_Cal_Obsolete_62_Error : 0|1@0+ (1,0) [0|0] "" Vector__XXX
 SG_ DSP_Calibration_Error : 0|1@0+ (1,0) [0|0] "" Vector__XXX
 SG_ CAN_TX_LOOK_INDEX : 0|16@0+ (1,0) [0|0] "" Vector__XXX
 SG_ USC_Load_Error : 0|1@0+ (1,0) [0|0] "" Vector__XXX
 SG_ SMC_Load_Error : 0|1@0+ (1,0) [0|0] "" Vector__XXX
 SG_ TX_Temperature_Fault : 0|1@0+ (1,0) [0|0] "" Vector__XXX
 SG_ DSP_Unit_Cal_Block_Chcksm_Error : 0|1@0+ (1,0) [0|0] "" Vector__XXX
 SG_ DSP_Unit_Cal_Checksum_Error : 0|1@0+ (1,0) [0|0] "" Vector__XXX
 SG_ Vertical_Misalignment_error : 0|1@0+ (1,0) [0|0] "" Vector__XXX
 SG_ RTN_SPI_Transfer_Error : 0|1@0+ (1,0) [0|0] "" Vector__XXX
 SG_ RRN_SPI_Transfer_Error : 0|1@0+ (1,0) [0|0] "" Vector__XXX
 SG_ Linearizer_SPI_Transfer_Error : 0|1@0+ (1,0) [0|0] "" Vector__XXX
 SG_ ADC_SPI_Transfer_Error : 0|1@0+ (1,0) [0|0] "" Vector__XXX
 SG_ Transmitter_ID_Error : 0|1@0+ (1,0) [0|0] "" Vector__XXX
 SG_ DSP_Loop_Overrun_Error : 0|1@0+ (1,0) [0|0] "" Vector__XXX
 SG_ Saturated_Tuning_Freq_Error : 0|1@0+ (1,0) [0|0] "" Vector__XXX
 SG_ Radar_Data_sync_error : 0|1@0+ (1,0) [0|0] "" Vector__XXX
 SG_ DSP_Tuning_Sensitivity_Error : 0|1@0+ (1,0) [0|0] "" Vector__XXX
 SG_ Radar_LO_Power_Error : 0|1@0+ (1,0) [0|0] "" Vector__XXX
 SG_ Radar_TX_Power_Error : 0|1@0+ (1,0) [0|0] "" Vector__XXX
 SG_ Timer_Create_Error : 0|1@0+ (1,0) [0|0] "" Vector__XXX
 SG_ Thread_Create_Error : 0|1@0+ (1,0) [0|0] "" Vector__XXX
 SG_ ARM_Calibration_Error : 0|1@0+ (1,0) [0|0] "" Vector__XXX
 SG_ SPI_FEE_Error : 0|1@0+ (1,0) [0|0] "" Vector__XXX
 SG_ SPI_Comm_Error : 0|1@0+ (1,0) [0|0] "" Vector__XXX
 SG_ Socket_Write_Error : 0|1@0+ (1,0) [0|0] "" Vector__XXX
 SG_ Socket_Read_error : 0|1@0+ (1,0) [0|0] "" Vector__XXX
 SG_ Socket_Init_Error : 0|1@0+ (1,0) [0|0] "" Vector__XXX
 SG_ Signal_Wait_Error : 0|1@0+ (1,0) [0|0] "" Vector__XXX
 SG_ Signal_Send_Error : 0|1@0+ (1,0) [0|0] "" Vector__XXX
 SG_ Signal_Create_Error : 0|1@0+ (1,0) [0|0] "" Vector__XXX
 SG_ Shared_Mem_Write_Error : 0|1@0+ (1,0) [0|0] "" Vector__XXX
 SG_ Shared_Mem_Read_Error : 0|1@0+ (1,0) [0|0] "" Vector__XXX
 SG_ Shared_Mem_Config_Error : 0|1@0+ (1,0) [0|0] "" Vector__XXX
 SG_ Share_Mem_Init_Error : 0|1@0+ (1,0) [0|0] "" Vector__XXX
 SG_ RAM_Test_Error : 0|1@0+ (1,0) [0|0] "" Vector__XXX
 SG_ Num_Errors : 0|1@0+ (1,0) [0|0] "" Vector__XXX
 SG_ MMAP_Memory_Error : 0|1@0+ (1,0) [0|0] "" Vector__XXX
 SG_ ISR_Attach_Error : 0|1@0+ (1,0) [0|0] "" Vector__XXX
 SG_ IPC_DRV_Write_Error : 0|1@0+ (1,0) [0|0] "" Vector__XXX
 SG_ IPC_DRV_Trigger_Error : 0|1@0+ (1,0) [0|0] "" Vector__XXX
 SG_ IPC_DRV_Sync_Error : 0|1@0+ (1,0) [0|0] "" Vector__XXX
 SG_ IPC_DRV_Read_Error : 0|1@0+ (1,0) [0|0] "" Vector__XXX
 SG_ IPC_DRV_Init_Error : 0|1@0+ (1,0) [0|0] "" Vector__XXX
 SG_ Interrupt_Enable_Error : 0|1@0+ (1,0) [0|0] "" Vector__XXX
 SG_ HIL_Format_Error : 0|1@0+ (1,0) [0|0] "" Vector__XXX
 SG_ Flash_Filesystem_Error : 0|1@0+ (1,0) [0|0] "" Vector__XXX
 SG_ Error_none : 0|1@0+ (1,0) [0|0] "" Vector__XXX
 SG_ DSP_Load_Read_Error : 0|1@0+ (1,0) [0|0] "" Vector__XXX
 SG_ DSP_Load_Open_Error : 0|1@0+ (1,0) [0|0] "" Vector__XXX
 SG_ DSP_Load_Address_Error : 0|1@0+ (1,0) [0|0] "" Vector__XXX
 SG_ DSP_ISP_Write_Error : 0|1@0+ (1,0) [0|0] "" Vector__XXX
 SG_ DSP_IPC_Read_Error : 0|1@0+ (1,0) [0|0] "" Vector__XXX
 SG_ DSP_IPC_Init : 0|1@0+ (1,0) [0|0] "" Vector__XXX
 SG_ DSP_Init_Error : 0|1@0+ (1,0) [0|0] "" Vector__XXX
 SG_ DSP_DRV_Start_Error : 0|1@0+ (1,0) [0|0] "" Vector__XXX
 SG_ DSP_DRV_Load_Error : 0|1@0+ (1,0) [0|0] "" Vector__XXX
 SG_ DSP_DRV_Init_Error : 0|1@0+ (1,0) [0|0] "" Vector__XXX
 SG_ DSP_DRV_Init2_error : 0|1@0+ (1,0) [0|0] "" Vector__XXX
 SG_ DSP_DRV_Init1_error : 0|1@0+ (1,0) [0|0] "" Vector__XXX
 SG_ CAN_XMT_Error : 0|1@0+ (1,0) [0|0] "" Vector__XXX
 SG_ CAN_RCV_Error : 0|1@0+ (1,0) [0|0] "" Vector__XXX
 SG_ CAN_Hardware_Error : 0|1@0+ (1,0) [0|0] "" Vector__XXX
 SG_ Always_True : 0|1@0+ (1,0) [0|0] "" Vector__XXX
 SG_ USC_Load_Error : 0|1@0+ (1,0) [0|0] "" Vector__XXX
 SG_ SMC_Load_Error : 0|1@0+ (1,0) [0|0] "" Vector__XXX
 SG_ TX_Temperature_Fault : 0|1@0+ (1,0) [0|0] "" Vector__XXX
 SG_ DSP_Unit_Cal_Block_Chcksm_Error : 0|1@0+ (1,0) [0|0] "" Vector__XXX
 SG_ DSP_Unit_Cal_Checksum_Error : 0|1@0+ (1,0) [0|0] "" Vector__XXX
 SG_ Vertical_Misalignment_error : 0|1@0+ (1,0) [0|0] "" Vector__XXX
 SG_ RTN_SPI_Transfer_Error : 0|1@0+ (1,0) [0|0] "" Vector__XXX
 SG_ RRN_SPI_Transfer_Error : 0|1@0+ (1,0) [0|0] "" Vector__XXX
 SG_ Linearizer_SPI_Transfer_Error : 0|1@0+ (1,0) [0|0] "" Vector__XXX
 SG_ ADC_SPI_Transfer_Error : 0|1@0+ (1,0) [0|0] "" Vector__XXX
 SG_ Transmitter_ID_Error : 0|1@0+ (1,0) [0|0] "" Vector__XXX
 SG_ DSP_Loop_Overrun_Error : 0|1@0+ (1,0) [0|0] "" Vector__XXX
 SG_ Saturated_Tuning_Freq_Error : 0|1@0+ (1,0) [0|0] "" Vector__XXX
 SG_ Radar_Data_sync_error : 0|1@0+ (1,0) [0|0] "" Vector__XXX
 SG_ DSP_Tuning_Sensitivity_Error : 0|1@0+ (1,0) [0|0] "" Vector__XXX
 SG_ Radar_LO_Power_Error : 0|1@0+ (1,0) [0|0] "" Vector__XXX
 SG_ Radar_TX_Power_Error : 0|1@0+ (1,0) [0|0] "" Vector__XXX
 SG_ Timer_Create_Error : 0|1@0+ (1,0) [0|0] "" Vector__XXX
 SG_ Thread_Create_Error : 0|1@0+ (1,0) [0|0] "" Vector__XXX
 SG_ ARM_Calibration_Error : 0|1@0+ (1,0) [0|0] "" Vector__XXX
 SG_ SPI_FEE_Error : 0|1@0+ (1,0) [0|0] "" Vector__XXX
 SG_ SPI_Comm_Error : 0|1@0+ (1,0) [0|0] "" Vector__XXX
 SG_ Socket_Write_Error : 0|1@0+ (1,0) [0|0] "" Vector__XXX
 SG_ Socket_Read_error : 0|1@0+ (1,0) [0|0] "" Vector__XXX
 SG_ Socket_Init_Error : 0|1@0+ (1,0) [0|0] "" Vector__XXX
 SG_ Signal_Wait_Error : 0|1@0+ (1,0) [0|0] "" Vector__XXX
 SG_ Signal_Send_Error : 0|1@0+ (1,0) [0|0] "" Vector__XXX
 SG_ Signal_Create_Error : 0|1@0+ (1,0) [0|0] "" Vector__XXX
 SG_ Shared_Mem_Write_Error : 0|1@0+ (1,0) [0|0] "" Vector__XXX
 SG_ Shared_Mem_Read_Error : 0|1@0+ (1,0) [0|0] "" Vector__XXX
 SG_ Shared_Mem_Config_Error : 0|1@0+ (1,0) [0|0] "" Vector__XXX
 SG_ Share_Mem_Init_Error : 0|1@0+ (1,0) [0|0] "" Vector__XXX
 SG_ RAM_Test_Error : 0|1@0+ (1,0) [0|0] "" Vector__XXX
 SG_ Num_Errors : 0|1@0+ (1,0) [0|0] "" Vector__XXX
 SG_ MMAP_Memory_Error : 0|1@0+ (1,0) [0|0] "" Vector__XXX
 SG_ ISR_Attach_Error : 0|1@0+ (1,0) [0|0] "" Vector__XXX
 SG_ IPC_DRV_Write_Error : 0|1@0+ (1,0) [0|0] "" Vector__XXX
 SG_ IPC_DRV_Trigger_Error : 0|1@0+ (1,0) [0|0] "" Vector__XXX
 SG_ IPC_DRV_Sync_Error : 0|1@0+ (1,0) [0|0] "" Vector__XXX
 SG_ IPC_DRV_Read_Error : 0|1@0+ (1,0) [0|0] "" Vector__XXX
 SG_ IPC_DRV_Init_Error : 0|1@0+ (1,0) [0|0] "" Vector__XXX
 SG_ Interrupt_Enable_Error : 0|1@0+ (1,0) [0|0] "" Vector__XXX
 SG_ HIL_Format_Error : 0|1@0+ (1,0) [0|0] "" Vector__XXX
 SG_ Flash_Filesystem_Error : 0|1@0+ (1,0) [0|0] "" Vector__XXX
 SG_ Error_none : 0|1@0+ (1,0) [0|0] "" Vector__XXX
 SG_ DSP_Load_Read_Error : 0|1@0+ (1,0) [0|0] "" Vector__XXX
 SG_ DSP_Load_Open_Error : 0|1@0+ (1,0) [0|0] "" Vector__XXX
 SG_ DSP_Load_Address_Error : 0|1@0+ (1,0) [0|0] "" Vector__XXX
 SG_ DSP_ISP_Write_Error : 0|1@0+ (1,0) [0|0] "" Vector__XXX
 SG_ DSP_IPC_Read_Error : 0|1@0+ (1,0) [0|0] "" Vector__XXX
 SG_ DSP_IPC_Init : 0|1@0+ (1,0) [0|0] "" Vector__XXX
 SG_ DSP_Init_Error : 0|1@0+ (1,0) [0|0] "" Vector__XXX
 SG_ DSP_DRV_Start_Error : 0|1@0+ (1,0) [0|0] "" Vector__XXX
 SG_ DSP_DRV_Load_Error : 0|1@0+ (1,0) [0|0] "" Vector__XXX
 SG_ DSP_DRV_Init_Error : 0|1@0+ (1,0) [0|0] "" Vector__XXX
 SG_ DSP_DRV_Init2_error : 0|1@0+ (1,0) [0|0] "" Vector__XXX
 SG_ DSP_DRV_Init1_error : 0|1@0+ (1,0) [0|0] "" Vector__XXX
 SG_ CAN_XMT_Error : 0|1@0+ (1,0) [0|0] "" Vector__XXX
 SG_ CAN_RCV_Error : 0|1@0+ (1,0) [0|0] "" Vector__XXX
 SG_ CAN_Hardware_Error : 0|1@0+ (1,0) [0|0] "" Vector__XXX
 SG_ Always_True : 0|1@0+ (1,0) [0|0] "" Vector__XXX
 SG_ USC_Load_Error : 0|1@0+ (1,0) [0|0] "" Vector__XXX
 SG_ SMC_Load_Error : 0|1@0+ (1,0) [0|0] "" Vector__XXX
 SG_ TX_Temperature_Fault : 0|1@0+ (1,0) [0|0] "" Vector__XXX
 SG_ DSP_Unit_Cal_Block_Chcksm_Error : 0|1@0+ (1,0) [0|0] "" Vector__XXX
 SG_ DSP_Unit_Cal_Checksum_Error : 0|1@0+ (1,0) [0|0] "" Vector__XXX
 SG_ Vertical_Misalignment_error : 0|1@0+ (1,0) [0|0] "" Vector__XXX
 SG_ RTN_SPI_Transfer_Error : 0|1@0+ (1,0) [0|0] "" Vector__XXX
 SG_ RRN_SPI_Transfer_Error : 0|1@0+ (1,0) [0|0] "" Vector__XXX
 SG_ Linearizer_SPI_Transfer_Error : 0|1@0+ (1,0) [0|0] "" Vector__XXX
 SG_ ADC_SPI_Transfer_Error : 0|1@0+ (1,0) [0|0] "" Vector__XXX
 SG_ Transmitter_ID_Error : 0|1@0+ (1,0) [0|0] "" Vector__XXX
 SG_ DSP_Loop_Overrun_Error : 0|1@0+ (1,0) [0|0] "" Vector__XXX
 SG_ Saturated_Tuning_Freq_Error : 0|1@0+ (1,0) [0|0] "" Vector__XXX
 SG_ Radar_Data_sync_error : 0|1@0+ (1,0) [0|0] "" Vector__XXX
 SG_ DSP_Tuning_Sensitivity_Error : 0|1@0+ (1,0) [0|0] "" Vector__XXX
 SG_ Radar_LO_Power_Error : 0|1@0+ (1,0) [0|0] "" Vector__XXX
 SG_ Radar_TX_Power_Error : 0|1@0+ (1,0) [0|0] "" Vector__XXX
 SG_ Timer_Create_Error : 0|1@0+ (1,0) [0|0] "" Vector__XXX
 SG_ Thread_Create_Error : 0|1@0+ (1,0) [0|0] "" Vector__XXX
 SG_ ARM_Calibration_Error : 0|1@0+ (1,0) [0|0] "" Vector__XXX
 SG_ SPI_FEE_Error : 0|1@0+ (1,0) [0|0] "" Vector__XXX
 SG_ SPI_Comm_Error : 0|1@0+ (1,0) [0|0] "" Vector__XXX
 SG_ Socket_Write_Error : 0|1@0+ (1,0) [0|0] "" Vector__XXX
 SG_ Socket_Read_error : 0|1@0+ (1,0) [0|0] "" Vector__XXX
 SG_ Socket_Init_Error : 0|1@0+ (1,0) [0|0] "" Vector__XXX
 SG_ Signal_Wait_Error : 0|1@0+ (1,0) [0|0] "" Vector__XXX
 SG_ Signal_Send_Error : 0|1@0+ (1,0) [0|0] "" Vector__XXX
 SG_ Signal_Create_Error : 0|1@0+ (1,0) [0|0] "" Vector__XXX
 SG_ Shared_Mem_Write_Error : 0|1@0+ (1,0) [0|0] "" Vector__XXX
 SG_ Shared_Mem_Read_Error : 0|1@0+ (1,0) [0|0] "" Vector__XXX
 SG_ Shared_Mem_Config_Error : 0|1@0+ (1,0) [0|0] "" Vector__XXX
 SG_ Share_Mem_Init_Error : 0|1@0+ (1,0) [0|0] "" Vector__XXX
 SG_ RAM_Test_Error : 0|1@0+ (1,0) [0|0] "" Vector__XXX
 SG_ Num_Errors : 0|1@0+ (1,0) [0|0] "" Vector__XXX
 SG_ MMAP_Memory_Error : 0|1@0+ (1,0) [0|0] "" Vector__XXX
 SG_ ISR_Attach_Error : 0|1@0+ (1,0) [0|0] "" Vector__XXX
 SG_ IPC_DRV_Write_Error : 0|1@0+ (1,0) [0|0] "" Vector__XXX
 SG_ IPC_DRV_Trigger_Error : 0|1@0+ (1,0) [0|0] "" Vector__XXX
 SG_ IPC_DRV_Sync_Error : 0|1@0+ (1,0) [0|0] "" Vector__XXX
 SG_ IPC_DRV_Read_Error : 0|1@0+ (1,0) [0|0] "" Vector__XXX
 SG_ IPC_DRV_Init_Error : 0|1@0+ (1,0) [0|0] "" Vector__XXX
 SG_ Interrupt_Enable_Error : 0|1@0+ (1,0) [0|0] "" Vector__XXX
 SG_ HIL_Format_Error : 0|1@0+ (1,0) [0|0] "" Vector__XXX
 SG_ Flash_Filesystem_Error : 0|1@0+ (1,0) [0|0] "" Vector__XXX
 SG_ Error_none : 0|1@0+ (1,0) [0|0] "" Vector__XXX
 SG_ DSP_Load_Read_Error : 0|1@0+ (1,0) [0|0] "" Vector__XXX
 SG_ DSP_Load_Open_Error : 0|1@0+ (1,0) [0|0] "" Vector__XXX
 SG_ DSP_Load_Address_Error : 0|1@0+ (1,0) [0|0] "" Vector__XXX
 SG_ DSP_ISP_Write_Error : 0|1@0+ (1,0) [0|0] "" Vector__XXX
 SG_ DSP_IPC_Read_Error : 0|1@0+ (1,0) [0|0] "" Vector__XXX
 SG_ DSP_IPC_Init : 0|1@0+ (1,0) [0|0] "" Vector__XXX
 SG_ DSP_Init_Error : 0|1@0+ (1,0) [0|0] "" Vector__XXX
 SG_ DSP_DRV_Start_Error : 0|1@0+ (1,0) [0|0] "" Vector__XXX
 SG_ DSP_DRV_Load_Error : 0|1@0+ (1,0) [0|0] "" Vector__XXX
 SG_ DSP_DRV_Init_Error : 0|1@0+ (1,0) [0|0] "" Vector__XXX
 SG_ DSP_DRV_Init2_error : 0|1@0+ (1,0) [0|0] "" Vector__XXX
 SG_ DSP_DRV_Init1_error : 0|1@0+ (1,0) [0|0] "" Vector__XXX
 SG_ CAN_XMT_Error : 0|1@0+ (1,0) [0|0] "" Vector__XXX
 SG_ CAN_RCV_Error : 0|1@0+ (1,0) [0|0] "" Vector__XXX
 SG_ CAN_Hardware_Error : 0|1@0+ (1,0) [0|0] "" Vector__XXX
 SG_ Always_True : 0|1@0+ (1,0) [0|0] "" Vector__XXX
 SG_ USC_Load_Error : 0|1@0+ (1,0) [0|0] "" Vector__XXX
 SG_ SMC_Load_Error : 0|1@0+ (1,0) [0|0] "" Vector__XXX
 SG_ TX_Temperature_Fault : 0|1@0+ (1,0) [0|0] "" Vector__XXX
 SG_ DSP_Unit_Cal_Block_Chcksm_Error : 0|1@0+ (1,0) [0|0] "" Vector__XXX
 SG_ DSP_Unit_Cal_Checksum_Error : 0|1@0+ (1,0) [0|0] "" Vector__XXX
 SG_ Vertical_Misalignment_error : 0|1@0+ (1,0) [0|0] "" Vector__XXX
 SG_ RTN_SPI_Transfer_Error : 0|1@0+ (1,0) [0|0] "" Vector__XXX
 SG_ RRN_SPI_Transfer_Error : 0|1@0+ (1,0) [0|0] "" Vector__XXX
 SG_ Linearizer_SPI_Transfer_Error : 0|1@0+ (1,0) [0|0] "" Vector__XXX
 SG_ ADC_SPI_Transfer_Error : 0|1@0+ (1,0) [0|0] "" Vector__XXX
 SG_ Transmitter_ID_Error : 0|1@0+ (1,0) [0|0] "" Vector__XXX
 SG_ DSP_Loop_Overrun_Error : 0|1@0+ (1,0) [0|0] "" Vector__XXX
 SG_ Saturated_Tuning_Freq_Error : 0|1@0+ (1,0) [0|0] "" Vector__XXX
 SG_ Radar_Data_sync_error : 0|1@0+ (1,0) [0|0] "" Vector__XXX
 SG_ DSP_Tuning_Sensitivity_Error : 0|1@0+ (1,0) [0|0] "" Vector__XXX
 SG_ Radar_LO_Power_Error : 0|1@0+ (1,0) [0|0] "" Vector__XXX
 SG_ Radar_TX_Power_Error : 0|1@0+ (1,0) [0|0] "" Vector__XXX
 SG_ Timer_Create_Error : 0|1@0+ (1,0) [0|0] "" Vector__XXX
 SG_ Thread_Create_Error : 0|1@0+ (1,0) [0|0] "" Vector__XXX
 SG_ ARM_Calibration_Error : 0|1@0+ (1,0) [0|0] "" Vector__XXX
 SG_ SPI_FEE_Error : 0|1@0+ (1,0) [0|0] "" Vector__XXX
 SG_ SPI_Comm_Error : 0|1@0+ (1,0) [0|0] "" Vector__XXX
 SG_ Socket_Write_Error : 0|1@0+ (1,0) [0|0] "" Vector__XXX
 SG_ Socket_Read_error : 0|1@0+ (1,0) [0|0] "" Vector__XXX
 SG_ Socket_Init_Error : 0|1@0+ (1,0) [0|0] "" Vector__XXX
 SG_ Signal_Wait_Error : 0|1@0+ (1,0) [0|0] "" Vector__XXX
 SG_ Signal_Send_Error : 0|1@0+ (1,0) [0|0] "" Vector__XXX
 SG_ Signal_Create_Error : 0|1@0+ (1,0) [0|0] "" Vector__XXX
 SG_ Shared_Mem_Write_Error : 0|1@0+ (1,0) [0|0] "" Vector__XXX
 SG_ Shared_Mem_Read_Error : 0|1@0+ (1,0) [0|0] "" Vector__XXX
 SG_ Shared_Mem_Config_Error : 0|1@0+ (1,0) [0|0] "" Vector__XXX
 SG_ Share_Mem_Init_Error : 0|1@0+ (1,0) [0|0] "" Vector__XXX
 SG_ RAM_Test_Error : 0|1@0+ (1,0) [0|0] "" Vector__XXX
 SG_ Num_Errors : 0|1@0+ (1,0) [0|0] "" Vector__XXX
 SG_ MMAP_Memory_Error : 0|1@0+ (1,0) [0|0] "" Vector__XXX
 SG_ ISR_Attach_Error : 0|1@0+ (1,0) [0|0] "" Vector__XXX
 SG_ IPC_DRV_Write_Error : 0|1@0+ (1,0) [0|0] "" Vector__XXX
 SG_ IPC_DRV_Trigger_Error : 0|1@0+ (1,0) [0|0] "" Vector__XXX
 SG_ IPC_DRV_Sync_Error : 0|1@0+ (1,0) [0|0] "" Vector__XXX
 SG_ IPC_DRV_Read_Error : 0|1@0+ (1,0) [0|0] "" Vector__XXX
 SG_ IPC_DRV_Init_Error : 0|1@0+ (1,0) [0|0] "" Vector__XXX
 SG_ Interrupt_Enable_Error : 0|1@0+ (1,0) [0|0] "" Vector__XXX
 SG_ HIL_Format_Error : 0|1@0+ (1,0) [0|0] "" Vector__XXX
 SG_ Flash_Filesystem_Error : 0|1@0+ (1,0) [0|0] "" Vector__XXX
 SG_ Error_none : 0|1@0+ (1,0) [0|0] "" Vector__XXX
 SG_ DSP_Load_Read_Error : 0|1@0+ (1,0) [0|0] "" Vector__XXX
 SG_ DSP_Load_Open_Error : 0|1@0+ (1,0) [0|0] "" Vector__XXX
 SG_ DSP_Load_Address_Error : 0|1@0+ (1,0) [0|0] "" Vector__XXX
 SG_ DSP_ISP_Write_Error : 0|1@0+ (1,0) [0|0] "" Vector__XXX
 SG_ DSP_IPC_Read_Error : 0|1@0+ (1,0) [0|0] "" Vector__XXX
 SG_ DSP_IPC_Init : 0|1@0+ (1,0) [0|0] "" Vector__XXX
 SG_ DSP_Init_Error : 0|1@0+ (1,0) [0|0] "" Vector__XXX
 SG_ DSP_DRV_Start_Error : 0|1@0+ (1,0) [0|0] "" Vector__XXX
 SG_ DSP_DRV_Load_Error : 0|1@0+ (1,0) [0|0] "" Vector__XXX
 SG_ DSP_DRV_Init_Error : 0|1@0+ (1,0) [0|0] "" Vector__XXX
 SG_ DSP_DRV_Init2_error : 0|1@0+ (1,0) [0|0] "" Vector__XXX
 SG_ DSP_DRV_Init1_error : 0|1@0+ (1,0) [0|0] "" Vector__XXX
 SG_ CAN_XMT_Error : 0|1@0+ (1,0) [0|0] "" Vector__XXX
 SG_ CAN_RCV_Error : 0|1@0+ (1,0) [0|0] "" Vector__XXX
 SG_ CAN_Hardware_Error : 0|1@0+ (1,0) [0|0] "" Vector__XXX
 SG_ Always_True : 0|1@0+ (1,0) [0|0] "" Vector__XXX
 SG_ USC_Load_Error : 0|1@0+ (1,0) [0|0] "" Vector__XXX
 SG_ SMC_Load_Error : 0|1@0+ (1,0) [0|0] "" Vector__XXX
 SG_ TX_Temperature_Fault : 0|1@0+ (1,0) [0|0] "" Vector__XXX
 SG_ DSP_Unit_Cal_Block_Chcksm_Error : 0|1@0+ (1,0) [0|0] "" Vector__XXX
 SG_ DSP_Unit_Cal_Checksum_Error : 0|1@0+ (1,0) [0|0] "" Vector__XXX
 SG_ Vertical_Misalignment_error : 0|1@0+ (1,0) [0|0] "" Vector__XXX
 SG_ RTN_SPI_Transfer_Error : 0|1@0+ (1,0) [0|0] "" Vector__XXX
 SG_ RRN_SPI_Transfer_Error : 0|1@0+ (1,0) [0|0] "" Vector__XXX
 SG_ Linearizer_SPI_Transfer_Error : 0|1@0+ (1,0) [0|0] "" Vector__XXX
 SG_ ADC_SPI_Transfer_Error : 0|1@0+ (1,0) [0|0] "" Vector__XXX
 SG_ Transmitter_ID_Error : 0|1@0+ (1,0) [0|0] "" Vector__XXX
 SG_ DSP_Loop_Overrun_Error : 0|1@0+ (1,0) [0|0] "" Vector__XXX
 SG_ Saturated_Tuning_Freq_Error : 0|1@0+ (1,0) [0|0] "" Vector__XXX
 SG_ Radar_Data_sync_error : 0|1@0+ (1,0) [0|0] "" Vector__XXX
 SG_ DSP_Tuning_Sensitivity_Error : 0|1@0+ (1,0) [0|0] "" Vector__XXX
 SG_ Radar_LO_Power_Error : 0|1@0+ (1,0) [0|0] "" Vector__XXX
 SG_ Radar_TX_Power_Error : 0|1@0+ (1,0) [0|0] "" Vector__XXX
 SG_ Timer_Create_Error : 0|1@0+ (1,0) [0|0] "" Vector__XXX
 SG_ Thread_Create_Error : 0|1@0+ (1,0) [0|0] "" Vector__XXX
 SG_ ARM_Calibration_Error : 0|1@0+ (1,0) [0|0] "" Vector__XXX
 SG_ SPI_FEE_Error : 0|1@0+ (1,0) [0|0] "" Vector__XXX
 SG_ SPI_Comm_Error : 0|1@0+ (1,0) [0|0] "" Vector__XXX
 SG_ Socket_Write_Error : 0|1@0+ (1,0) [0|0] "" Vector__XXX
 SG_ Socket_Read_error : 0|1@0+ (1,0) [0|0] "" Vector__XXX
 SG_ Socket_Init_Error : 0|1@0+ (1,0) [0|0] "" Vector__XXX
 SG_ Signal_Wait_Error : 0|1@0+ (1,0) [0|0] "" Vector__XXX
 SG_ Signal_Send_Error : 0|1@0+ (1,0) [0|0] "" Vector__XXX
 SG_ Signal_Create_Error : 0|1@0+ (1,0) [0|0] "" Vector__XXX
 SG_ Shared_Mem_Write_Error : 0|1@0+ (1,0) [0|0] "" Vector__XXX
 SG_ Shared_Mem_Read_Error : 0|1@0+ (1,0) [0|0] "" Vector__XXX
 SG_ Shared_Mem_Config_Error : 0|1@0+ (1,0) [0|0] "" Vector__XXX
 SG_ Share_Mem_Init_Error : 0|1@0+ (1,0) [0|0] "" Vector__XXX
 SG_ RAM_Test_Error : 0|1@0+ (1,0) [0|0] "" Vector__XXX
 SG_ Num_Errors : 0|1@0+ (1,0) [0|0] "" Vector__XXX
 SG_ MMAP_Memory_Error : 0|1@0+ (1,0) [0|0] "" Vector__XXX
 SG_ ISR_Attach_Error : 0|1@0+ (1,0) [0|0] "" Vector__XXX
 SG_ IPC_DRV_Write_Error : 0|1@0+ (1,0) [0|0] "" Vector__XXX
 SG_ IPC_DRV_Trigger_Error : 0|1@0+ (1,0) [0|0] "" Vector__XXX
 SG_ IPC_DRV_Sync_Error : 0|1@0+ (1,0) [0|0] "" Vector__XXX
 SG_ IPC_DRV_Read_Error : 0|1@0+ (1,0) [0|0] "" Vector__XXX
 SG_ IPC_DRV_Init_Error : 0|1@0+ (1,0) [0|0] "" Vector__XXX
 SG_ Interrupt_Enable_Error : 0|1@0+ (1,0) [0|0] "" Vector__XXX
 SG_ HIL_Format_Error : 0|1@0+ (1,0) [0|0] "" Vector__XXX
 SG_ Flash_Filesystem_Error : 0|1@0+ (1,0) [0|0] "" Vector__XXX
 SG_ Error_none : 0|1@0+ (1,0) [0|0] "" Vector__XXX
 SG_ DSP_Load_Read_Error : 0|1@0+ (1,0) [0|0] "" Vector__XXX
 SG_ DSP_Load_Open_Error : 0|1@0+ (1,0) [0|0] "" Vector__XXX
 SG_ DSP_Load_Address_Error : 0|1@0+ (1,0) [0|0] "" Vector__XXX
 SG_ DSP_ISP_Write_Error : 0|1@0+ (1,0) [0|0] "" Vector__XXX
 SG_ DSP_IPC_Read_Error : 0|1@0+ (1,0) [0|0] "" Vector__XXX
 SG_ DSP_IPC_Init : 0|1@0+ (1,0) [0|0] "" Vector__XXX
 SG_ DSP_Init_Error : 0|1@0+ (1,0) [0|0] "" Vector__XXX
 SG_ DSP_DRV_Start_Error : 0|1@0+ (1,0) [0|0] "" Vector__XXX
 SG_ DSP_DRV_Load_Error : 0|1@0+ (1,0) [0|0] "" Vector__XXX
 SG_ DSP_DRV_Init_Error : 0|1@0+ (1,0) [0|0] "" Vector__XXX
 SG_ DSP_DRV_Init2_error : 0|1@0+ (1,0) [0|0] "" Vector__XXX
 SG_ DSP_DRV_Init1_error : 0|1@0+ (1,0) [0|0] "" Vector__XXX
 SG_ CAN_XMT_Error : 0|1@0+ (1,0) [0|0] "" Vector__XXX
 SG_ CAN_RCV_Error : 0|1@0+ (1,0) [0|0] "" Vector__XXX
 SG_ CAN_Hardware_Error : 0|1@0+ (1,0) [0|0] "" Vector__XXX
 SG_ Always_True : 0|1@0+ (1,0) [0|0] "" Vector__XXX
 SG_ New_Signal_2609 : 0|8@1+ (1,0) [0|0] "" Vector__XXX
 SG_ New_Signal_2082 : 0|8@1+ (1,0) [0|0] "" Vector__XXX
 SG_ CAN_TX_PRIORITIZATION_TIME : 0|8@0+ (1,0) [0|0] "ms" Vector__XXX
 SG_ CAN_TX_RDD_TIME : 0|8@0+ (1,0) [0|0] "ms" Vector__XXX
 SG_ CAN_TX_BEAMFORM_TIME : 0|8@0+ (1,0) [0|0] "ms" Vector__XXX
 SG_ CAN_TX_LL_TOTAL_TIME : 0|8@0+ (1,0) [0|0] "ms" Vector__XXX
 SG_ CAN_TX_ML_TOTAL_TIME : 0|8@0+ (1,0) [0|0] "ms" Vector__XXX
 SG_ CAN_TX_PRIORITIZATION_TIME : 0|8@0+ (1,0) [0|0] "ms" Vector__XXX
 SG_ CAN_TX_RDD_TIME : 0|8@0+ (1,0) [0|0] "ms" Vector__XXX
 SG_ CAN_TX_BEAMFORM_TIME : 0|8@0+ (1,0) [0|0] "ms" Vector__XXX
 SG_ CAN_TX_LL_TOTAL_TIME : 0|8@0+ (1,0) [0|0] "ms" Vector__XXX
 SG_ CAN_TX_ML_TOTAL_TIME : 0|8@0+ (1,0) [0|0] "ms" Vector__XXX
 SG_ CAN_TX_PRIORITIZATION_TIME : 0|8@0+ (1,0) [0|0] "ms" Vector__XXX
 SG_ CAN_TX_RDD_TIME : 0|8@0+ (1,0) [0|0] "ms" Vector__XXX
 SG_ CAN_TX_BEAMFORM_TIME : 0|8@0+ (1,0) [0|0] "ms" Vector__XXX
 SG_ CAN_TX_LL_TOTAL_TIME : 0|8@0+ (1,0) [0|0] "ms" Vector__XXX
 SG_ CAN_TX_ML_TOTAL_TIME : 0|8@0+ (1,0) [0|0] "ms" Vector__XXX
 SG_ CAN_TX_TRIGGER_SENSOR : 0|3@0+ (1,0) [0|0] "" Vector__XXX
 SG_ CAN_TX_RCWM_TIME : 0|8@0+ (1,0) [0|0] "ms" Vector__XXX
 SG_ CAN_TX_RECW_TIME : 0|8@0+ (1,0) [0|0] "ms" Vector__XXX
 SG_ CAN_TX_FREESPACE_TIME : 0|8@0+ (1,0) [0|0] "ms" Vector__XXX
 SG_ CAN_TX_LCDA_TIME : 0|8@0+ (1,0) [0|0] "ms" Vector__XXX
 SG_ CAN_TX_CTA_TIME : 0|8@0+ (1,0) [0|0] "ms" Vector__XXX
 SG_ CAN_TX_ALIGNMENT_TIME : 0|8@0+ (1,0) [0|0] "ms" Vector__XXX
 SG_ CAN_TX_TRACKER_TIME : 0|8@0+ (1,0) [0|0] "ms" Vector__XXX
 SG_ CAN_TX_TRIGGER_SENSOR : 0|3@0+ (1,0) [0|0] "" Vector__XXX
 SG_ CAN_TX_RCWM_TIME : 0|8@0+ (1,0) [0|0] "ms" Vector__XXX
 SG_ CAN_TX_RECW_TIME : 0|8@0+ (1,0) [0|0] "ms" Vector__XXX
 SG_ CAN_TX_FREESPACE_TIME : 0|8@0+ (1,0) [0|0] "ms" Vector__XXX
 SG_ CAN_TX_LCDA_TIME : 0|8@0+ (1,0) [0|0] "ms" Vector__XXX
 SG_ CAN_TX_CTA_TIME : 0|8@0+ (1,0) [0|0] "ms" Vector__XXX
 SG_ CAN_TX_ALIGNMENT_TIME : 0|8@0+ (1,0) [0|0] "ms" Vector__XXX
 SG_ CAN_TX_TRACKER_TIME : 0|8@0+ (1,0) [0|0] "ms" Vector__XXX
 SG_ CAN_TX_TRIGGER_SENSOR : 0|3@0+ (1,0) [0|0] "" Vector__XXX
 SG_ CAN_TX_RCWM_TIME : 0|8@0+ (1,0) [0|0] "ms" Vector__XXX
 SG_ CAN_TX_RECW_TIME : 0|8@0+ (1,0) [0|0] "ms" Vector__XXX
 SG_ CAN_TX_FREESPACE_TIME : 0|8@0+ (1,0) [0|0] "ms" Vector__XXX
 SG_ CAN_TX_LCDA_TIME : 0|8@0+ (1,0) [0|0] "ms" Vector__XXX
 SG_ CAN_TX_CTA_TIME : 0|8@0+ (1,0) [0|0] "ms" Vector__XXX
 SG_ CAN_TX_ALIGNMENT_TIME : 0|8@0+ (1,0) [0|0] "ms" Vector__XXX
 SG_ CAN_TX_TRACKER_TIME : 0|8@0+ (1,0) [0|0] "ms" Vector__XXX
 SG_ CAN_TX_PRIORITIZATION_TIME : 0|8@0+ (1,0) [0|0] "ms" Vector__XXX
 SG_ CAN_TX_RDD_TIME : 0|8@0+ (1,0) [0|0] "ms" Vector__XXX
 SG_ CAN_TX_BEAMFORM_TIME : 0|8@0+ (1,0) [0|0] "ms" Vector__XXX
 SG_ CAN_TX_LL_TOTAL_TIME : 0|8@0+ (1,0) [0|0] "ms" Vector__XXX
 SG_ CAN_TX_ML_TOTAL_TIME : 0|8@0+ (1,0) [0|0] "ms" Vector__XXX
 SG_ CAN_TX_TRIGGER_SENSOR : 0|3@0+ (1,0) [0|0] "" Vector__XXX
 SG_ CAN_TX_RCWM_TIME : 0|8@0+ (1,0) [0|0] "ms" Vector__XXX
 SG_ CAN_TX_RECW_TIME : 0|8@0+ (1,0) [0|0] "ms" Vector__XXX
 SG_ CAN_TX_FREESPACE_TIME : 0|8@0+ (1,0) [0|0] "ms" Vector__XXX
 SG_ CAN_TX_LCDA_TIME : 0|8@0+ (1,0) [0|0] "ms" Vector__XXX
 SG_ CAN_TX_CTA_TIME : 0|8@0+ (1,0) [0|0] "ms" Vector__XXX
 SG_ CAN_TX_ALIGNMENT_TIME : 0|8@0+ (1,0) [0|0] "ms" Vector__XXX
 SG_ CAN_TX_TRACKER_TIME : 0|8@0+ (1,0) [0|0] "ms" Vector__XXX
 SG_ CAN_TX_LANE_WIDTH : 0|9@0- (1,0) [0|0] "cm" Vector__XXX
 SG_ LCMA_blis_ignored_track_id : 0|8@0+ (1,0) [0|0] "" Vector__XXX
 SG_ LCMA_blis_track_id : 0|8@0+ (1,0) [0|0] "" Vector__XXX
 SG_ LCMA_cvw_TTC : 0|8@0+ (0.1,0) [0|0] "seconds" Vector__XXX
 SG_ CTA_TTC_Alert : 0|1@0+ (1,0) [0|0] "" Vector__XXX
 SG_ CTA_selected_track_ttc : 0|8@0+ (0.1,0) [0|25.5] "seconds" Vector__XXX
 SG_ CTA_selected_track : 0|8@0+ (1,0) [0|256] "" Vector__XXX
 SG_ CTA_Alert : 0|2@0+ (1,0) [0|3] "binary" Vector__XXX
 SG_ CTA_Active : 0|1@0+ (1,0) [0|0] "binary" Vector__XXX
 SG_ LCMA_cvw_cipv : 0|8@0+ (1,0) [0|0] "" Vector__XXX
 SG_ LCMA_cvw_alert_state : 0|2@0+ (1,0) [0|0] "" Vector__XXX
 SG_ LCMA_blis_alert_state : 0|2@0+ (1,0) [0|0] "" Vector__XXX
 SG_ LCMA_Active : 0|1@0+ (1,0) [0|0] "" Vector__XXX
 SG_ LCMA_blis_ignored_track_id : 0|8@0+ (1,0) [0|0] "" Vector__XXX
 SG_ LCMA_blis_track_id : 0|8@0+ (1,0) [0|0] "" Vector__XXX
 SG_ LCMA_cvw_TTC : 0|8@0+ (0.1,0) [0|0] "seconds" Vector__XXX
 SG_ CTA_TTC_Alert : 0|1@0+ (1,0) [0|0] "" Vector__XXX
 SG_ CTA_selected_track_ttc : 0|8@0+ (0.1,0) [0|25.5] "seconds" Vector__XXX
 SG_ CTA_selected_track : 0|8@0+ (1,0) [0|256] "" Vector__XXX
 SG_ CTA_Alert : 0|2@0+ (1,0) [0|3] "binary" Vector__XXX
 SG_ CTA_Active : 0|1@0+ (1,0) [0|0] "binary" Vector__XXX
 SG_ LCMA_cvw_cipv : 0|8@0+ (1,0) [0|0] "" Vector__XXX
 SG_ LCMA_cvw_alert_state : 0|2@0+ (1,0) [0|0] "" Vector__XXX
 SG_ LCMA_blis_alert_state : 0|2@0+ (1,0) [0|0] "" Vector__XXX
 SG_ LCMA_Active : 0|1@0+ (1,0) [0|0] "" Vector__XXX
 SG_ CAN_TX_TARGET_ID : 0|8@0+ (1,0) [0|255] "" Vector__XXX
 SG_ TTC_PRECRASH : 0|8@1+ (20,0) [0|5020] "ms" Vector__XXX
 SG_ STATUS_RECW_WARNING : 0|3@1+ (1,0) [0|0] "" Vector__XXX
 SG_ STATUS_PRECRASH : 0|4@1+ (1,0) [0|0] "" Vector__XXX
 SG_ CV_PRECRASH : 0|8@1+ (1,0) [1|252] "km/h" Vector__XXX
 SG_ CTA_TTC_Alert : 0|1@0+ (1,0) [0|0] "" Vector__XXX
 SG_ CTA_selected_track_ttc : 0|8@0+ (0.1,0) [0|25.5] "seconds" Vector__XXX
 SG_ CTA_selected_track : 0|8@0+ (1,0) [0|256] "" Vector__XXX
 SG_ CTA_Alert : 0|2@0+ (1,0) [0|3] "binary" Vector__XXX
 SG_ CTA_Active : 0|1@0+ (1,0) [0|0] "binary" Vector__XXX
 SG_ CTA_TTC_Alert : 0|1@0+ (1,0) [0|0] "" Vector__XXX
 SG_ CTA_selected_track_ttc : 0|8@0+ (0.1,0) [0|25.5] "seconds" Vector__XXX
 SG_ CTA_selected_track : 0|8@0+ (1,0) [0|256] "" Vector__XXX
 SG_ CTA_Alert : 0|2@0+ (1,0) [0|3] "binary" Vector__XXX
 SG_ CTA_Active : 0|1@0+ (1,0) [0|0] "binary" Vector__XXX
 SG_ CAN_TX_SERIAL_NUM : 0|24@0+ (1,0) [0|0] "" Vector__XXX
 SG_ CAN_TX_SERIAL_NUM : 0|24@0+ (1,0) [0|0] "" Vector__XXX
 SG_ CAN_TX_SERIAL_NUM : 0|24@0+ (1,0) [0|0] "" Vector__XXX
 SG_ CAN_TX_SERIAL_NUM : 0|24@0+ (1,0) [0|0] "" Vector__XXX

BO_ 263 SODRR_Status08: 8 SODRR
 SG_ CAN_TX_DSP_TRIG_DIFF : 39|8@0+ (1,0) [0|255] "" Vector__XXX
 SG_ CAN_TX_OPP_LOOK_TYPE : 31|8@0+ (1,0) [0|255] "" Vector__XXX
 SG_ CAN_TX_OPP_LOOK_ID : 23|8@0+ (1,0) [0|255] "" Vector__XXX
 SG_ CAN_TX_DSP_LOOK_TYPE : 15|8@0+ (1,0) [0|255] "" Vector__XXX
 SG_ CAN_TX_DSP_LOOK_ID : 7|8@0+ (1,0) [0|255] "" Vector__XXX

BO_ 2 RS01_SystemControl: 8 RS01
 SG_ CAN_TX_MUX_VEHICLE_PLATFORM m7 : 15|8@0+ (1,0) [0|0] "" Vector__XXX
 SG_ CAN_TX_MUX_TEMP_EX m6 : 15|8@0+ (0.5,-40) [-40|85] "degC" Vector__XXX
 SG_ CAN_TX_MUX_TRAFFIC_ENVIRONMENT m0 : 55|8@0- (1,0) [0|0] "" Vector__XXX
 SG_ CAN_TX_MUX_LANE_CALC_METHOD m0 : 47|8@0- (1,0) [0|0] "" Vector__XXX
 SG_ CAN_TX_MUX_SODRR_RADIATION_CTRL m1 : 15|8@0- (1,0) [0|0] "" Vector__XXX
 SG_ CAN_TX_MUX_SODRR_FORCED_AA_VALUE m2 : 15|16@0- (0.0009765625,0) [-7.68|7.62] "" Vector__XXX
 SG_ CAN_TX_MUX_SODRL_RADIATION_CTRL m1 : 23|8@0- (1,0) [0|0] "" Vector__XXX
 SG_ CAN_TX_MUX_SODRL_FORCED_AA_VALUE m3 : 15|16@0- (0.0009765625,0) [-7.68|7.62] "" Vector__XXX
 SG_ CAN_TX_MUX_SODFR_RADIATION_CTRL m1 : 31|8@0- (1,0) [0|0] "" Vector__XXX
 SG_ CAN_TX_MUX_SODFR_FORCED_AA_VALUE m4 : 15|16@0- (0.0009765625,0) [-7.68|7.62] "" Vector__XXX
 SG_ CAN_TX_MUX_SODFL_RADIATION_CTRL m1 : 39|8@0- (1,0) [0|0] "" Vector__XXX
 SG_ CAN_TX_MUX_SODFL_FORCED_AA_VALUE m5 : 15|16@0- (0.0009765625,0) [-7.68|7.62] "" Vector__XXX
 SG_ CAN_TX_MUX_LANE_WIDTH m0 : 15|16@0+ (1,0) [0|0] "cm" Vector__XXX
 SG_ CAN_TX_MUX_LANE_CENTER_OFFSET m0 : 31|16@0- (1,0) [0|0] "cm" Vector__XXX
 SG_ CAN_TX_MUX_ID M : 7|8@0+ (1,0) [0|255] "" Vector__XXX

BO_ 755 DIAG_RESP_RSR: 8 Vector__XXX

BO_ 754 DIAG_RESP_RSL: 8 Vector__XXX

BO_ 753 DIAG_RESP_HC2L: 8 Vector__XXX

BO_ 752 DIAG_REQ_HC2R: 8 Vector__XXX

BO_ 869 SODFR_XCP_RESP: 8 Vector__XXX

BO_ 871 SODFL_XCP_RESP: 8 Vector__XXX

BO_ 870 SODRR_XCP_RESP: 8 Vector__XXX

BO_ 868 SODRL_XCP_RESP: 8 Vector__XXX

BO_ 865 SODFR_XCP_REQ: 8 Vector__XXX

BO_ 867 SODFL_XCP_REQ: 8 Vector__XXX

BO_ 866 SODRR_XCP_REQ: 8 Vector__XXX

BO_ 864 SODRL_XCP_REQ: 8 Vector__XXX

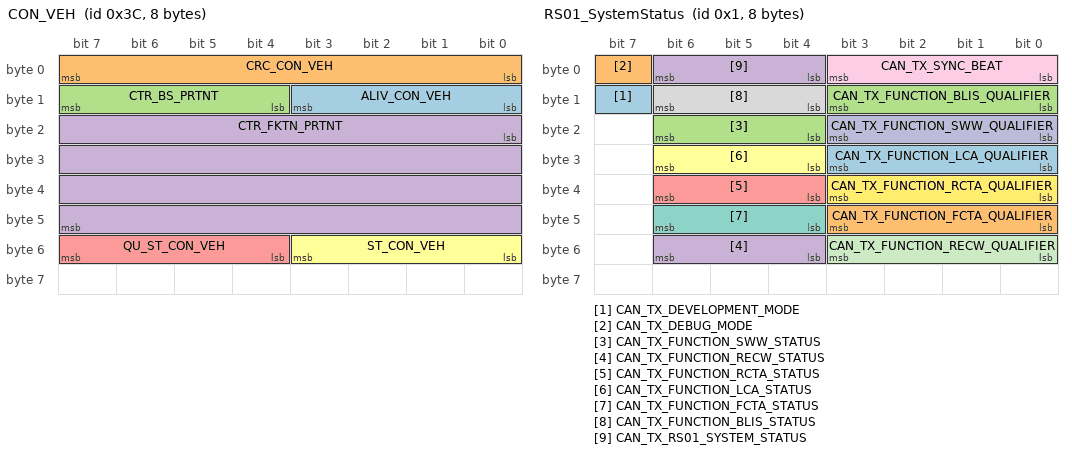
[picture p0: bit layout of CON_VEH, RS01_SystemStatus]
BO_ 60 CON_VEH : 8 Vector__XXX
  SG_ ALIV_CON_VEH : 8|4@1+ (1,0) [0|14] "" AAG,ATM,CAN_SINE,CDM,CPM,CVM,D_CAN_Tester,DCS,DSC_Modul,ELV,emARS_h,emARS_v,EPS,FLA,FLM_L,FLM_R,GHAS,HC2,HKA,HKFM,HSR,HVS,IHKA,Kombi,LMV,PCU500,REF_BAC4_FR,REF_BAC4CAN,SEC1,SLE,SM_BF,SM_BFH,SM_FA,SM_FAH,SPnM_HL,SPnM_HR,SPnM_VL,SPnM_VR,USS,VDP,VSG,ZBE,ZBE_FOND
  SG_ CRC_CON_VEH : 0|8@1+ (1,0) [0|255] "" AAG,ATM,CAN_SINE,CDM,CPM,CVM,D_CAN_Tester,DCS,DSC_Modul,ELV,emARS_h,emARS_v,EPS,FLA,FLM_L,FLM_R,GHAS,HC2,HKA,HKFM,HSR,HVS,IHKA,Kombi,LMV,PCU500,REF_BAC4_FR,REF_BAC4CAN,SEC1,SLE,SM_BF,SM_BFH,SM_FA,SM_FAH,SPnM_HL,SPnM_HR,SPnM_VL,SPnM_VR,USS,VDP,VSG,ZBE,ZBE_FOND
  SG_ CTR_BS_PRTNT : 12|4@1+ (1,0) [0|0] "" AAG,ATM,CAN_SINE,CDM,CPM,CVM,D_CAN_Tester,DCS,DSC_Modul,ELV,emARS_h,emARS_v,EPS,FLA,FLM_L,FLM_R,GHAS,HC2,HKA,HKFM,HSR,HVS,IHKA,Kombi,NBTevo_EntryNav,PCU500,REF_BAC4_FR,REF_BAC4CAN,SEC1,SLE,SM_BF,SM_BFH,SM_FA,SM_FAH,SPnM_HL,SPnM_HR,SPnM_VL,SPnM_VR,USS,VDP,VSG,ZBE,ZBE_FOND
  SG_ CTR_FKTN_PRTNT : 16|32@1+ (1,0) [0|0] "" AAG,ATM,CAN_SINE,CDM,CPM,CVM,D_CAN_Tester,DCS,DSC_Modul,ELV,emARS_h,emARS_v,EPS,FLA,FLM_L,FLM_R,GHAS,HC2,HKA,HKFM,HSR,HVS,IHKA,Kombi,NBTevo_EntryNav,PCU500,REF_BAC4_FR,REF_BAC4CAN,SEC1,SLE,SM_BF,SM_BFH,SM_FA,SM_FAH,SPnM_HL,SPnM_HR,SPnM_VL,SPnM_VR,USS,VDP,VSG,ZBE,ZBE_FOND
  SG_ QU_ST_CON_VEH : 52|4@1+ (1,0) [0|0] "" CDM,D_CAN_Tester,DSC_Modul,ELV,FLM_L,FLM_R,GHAS,HKFM
  SG_ ST_CON_VEH : 48|4@1+ (1,0) [0|0] "" AAG,ATM,CAN_SINE,CDM,CPM,CVM,D_CAN_Tester,DCS,DSC_Modul,ELV,emARS_h,emARS_v,EPS,FLA,FLM_L,FLM_R,GHAS,HC2,HKA,HKFM,HSR,HVS,IHKA,Kombi,LEM01,LMV,NBTevo_EntryNav,PCU500,REF_BAC4_FR,REF_BAC4CAN,SCR,SEC1,SLE,SM_BF,SM_BFH,SM_FA,SM_FAH,SPnM_HL,SPnM_HR,SPnM_VL,SPnM_VR,USS,VDP,VSG,ZBE,ZBE_FOND

BO_ 1 RS01_SystemStatus: 8 RS01
 SG_ CAN_TX_DEVELOPMENT_MODE : 15|1@0+ (1,0) [0|0] "" Vector__XXX
 SG_ CAN_TX_DEBUG_MODE : 7|1@0+ (1,0) [0|0] "" Vector__XXX
 SG_ CAN_TX_FUNCTION_SWW_STATUS : 22|3@0+ (1,0) [0|0] "" Vector__XXX
 SG_ CAN_TX_FUNCTION_RECW_STATUS : 54|3@0+ (1,0) [0|0] "" Vector__XXX
 SG_ CAN_TX_FUNCTION_RCTA_STATUS : 38|3@0+ (1,0) [0|0] "" Vector__XXX
 SG_ CAN_TX_FUNCTION_LCA_STATUS : 30|3@0+ (1,0) [0|0] "" Vector__XXX
 SG_ CAN_TX_FUNCTION_FCTA_STATUS : 46|3@0+ (1,0) [0|0] "" Vector__XXX
 SG_ CAN_TX_FUNCTION_BLIS_STATUS : 14|3@0+ (1,0) [0|0] "" Vector__XXX
 SG_ CAN_TX_SYNC_BEAT : 3|4@0+ (1,0) [0|0] "" Vector__XXX
 SG_ CAN_TX_FUNCTION_SWW_QUALIFIER : 19|4@0+ (1,0) [0|0] "" Vector__XXX
 SG_ CAN_TX_FUNCTION_RECW_QUALIFIER : 51|4@0+ (1,0) [0|0] "" Vector__XXX
 SG_ CAN_TX_FUNCTION_RCTA_QUALIFIER : 35|4@0+ (1,0) [0|0] "" Vector__XXX
 SG_ CAN_TX_FUNCTION_LCA_QUALIFIER : 27|4@0+ (1,0) [0|0] "" Vector__XXX
 SG_ CAN_TX_FUNCTION_FCTA_QUALIFIER : 43|4@0+ (1,0) [0|0] "" Vector__XXX
 SG_ CAN_TX_FUNCTION_BLIS_QUALIFIER : 11|4@0+ (1,0) [0|0] "" Vector__XXX
 SG_ CAN_TX_RS01_SYSTEM_STATUS : 6|3@0+ (1,0) [0|0] "" Vector__XXX

BO_ 262 SODRR_Status07: 8 SODRR
 SG_ CAN_TX_MUX_SVK_CAL_DATA_5 m128 : 63|8@0+ (1,0) [0|0] "" Vector__XXX
 SG_ CAN_TX_MUX_SVK_CAL_DATA_4 m128 : 55|8@0+ (1,0) [0|0] "" Vector__XXX
 SG_ CAN_TX_MUX_SVK_CAL_DATA_3 m128 : 47|8@0+ (1,0) [0|0] "" Vector__XXX
 SG_ CAN_TX_MUX_SVK_CAL_DATA_2 m128 : 39|8@0+ (1,0) [0|0] "" Vector__XXX
 SG_ CAN_TX_MUX_SVK_CAL_DATA_1 m128 : 31|8@0+ (1,0) [0|0] "" Vector__XXX
 SG_ CAN_TX_MUX_SVK_CAL_DATA_0 m128 : 23|8@0+ (1,0) [0|0] "" Vector__XXX
 SG_ CAN_TX_MUX_SVK_CAL_MSG_CNT m128 : 15|8@0+ (1,0) [0|0] "" Vector__XXX
 SG_ CAN_TX_MUX_RCWM_CAL_MSG_CNT m29 : 15|8@0+ (1,0) [0|0] "" Vector__XXX
 SG_ CAN_TX_MUX_RCWM_CAL_DATA_0 m29 : 23|8@0+ (1,0) [0|0] "" Vector__XXX
 SG_ CAN_TX_MUX_RCWM_CAL_DATA_1 m29 : 31|8@0+ (1,0) [0|0] "" Vector__XXX
 SG_ CAN_TX_MUX_RCWM_CAL_DATA_2 m29 : 39|8@0+ (1,0) [0|0] "" Vector__XXX
 SG_ CAN_TX_MUX_RCWM_CAL_DATA_3 m29 : 47|8@0+ (1,0) [0|0] "" Vector__XXX
 SG_ CAN_TX_MUX_RCWM_CAL_DATA_4 m29 : 55|8@0+ (1,0) [0|0] "" Vector__XXX
 SG_ CAN_TX_MUX_RCWM_CAL_DATA_5 m29 : 63|8@0+ (1,0) [0|0] "" Vector__XXX
 SG_ CAN_TX_MUX_RECW_CAL_MSG_CNT m28 : 15|8@0+ (1,0) [0|0] "" Vector__XXX
 SG_ CAN_TX_MUX_RECW_CAL_DATA_0 m28 : 23|8@0+ (1,0) [0|0] "" Vector__XXX
 SG_ CAN_TX_MUX_RECW_CAL_DATA_1 m28 : 31|8@0+ (1,0) [0|0] "" Vector__XXX
 SG_ CAN_TX_MUX_RECW_CAL_DATA_2 m28 : 39|8@0+ (1,0) [0|0] "" Vector__XXX
 SG_ CAN_TX_MUX_RECW_CAL_DATA_3 m28 : 47|8@0+ (1,0) [0|0] "" Vector__XXX
 SG_ CAN_TX_MUX_RECW_CAL_DATA_4 m28 : 55|8@0+ (1,0) [0|0] "" Vector__XXX
 SG_ CAN_TX_MUX_RECW_CAL_DATA_5 m28 : 63|8@0+ (1,0) [0|0] "" Vector__XXX
 SG_ CAN_TX_MUX_FREESPACE_CAL_MSG_CNT m27 : 15|8@0+ (1,0) [0|0] "" Vector__XXX
 SG_ CAN_TX_MUX_FREESPACE_CAL_DATA_0 m27 : 23|8@0+ (1,0) [0|0] "" Vector__XXX
 SG_ CAN_TX_MUX_FREESPACE_CAL_DATA_1 m27 : 31|8@0+ (1,0) [0|0] "" Vector__XXX
 SG_ CAN_TX_MUX_FREESPACE_CAL_DATA_2 m27 : 39|8@0+ (1,0) [0|0] "" Vector__XXX
 SG_ CAN_TX_MUX_FREESPACE_CAL_DATA_3 m27 : 47|8@0+ (1,0) [0|0] "" Vector__XXX
 SG_ CAN_TX_MUX_FREESPACE_CAL_DATA_4 m27 : 55|8@0+ (1,0) [0|0] "" Vector__XXX
 SG_ CAN_TX_MUX_FREESPACE_CAL_DATA_5 m27 : 63|8@0+ (1,0) [0|0] "" Vector__XXX
 SG_ CAN_TX_MUX_LCDA_CAL_MSG_CNT m26 : 15|8@0+ (1,0) [0|0] "" Vector__XXX
 SG_ CAN_TX_MUX_LCDA_CAL_DATA_0 m26 : 23|8@0+ (1,0) [0|0] "" Vector__XXX
 SG_ CAN_TX_MUX_LCDA_CAL_DATA_1 m26 : 31|8@0+ (1,0) [0|0] "" Vector__XXX
 SG_ CAN_TX_MUX_LCDA_CAL_DATA_2 m26 : 39|8@0+ (1,0) [0|0] "" Vector__XXX
 SG_ CAN_TX_MUX_LCDA_CAL_DATA_3 m26 : 47|8@0+ (1,0) [0|0] "" Vector__XXX
 SG_ CAN_TX_MUX_LCDA_CAL_DATA_4 m26 : 55|8@0+ (1,0) [0|0] "" Vector__XXX
 SG_ CAN_TX_MUX_LCDA_CAL_DATA_5 m26 : 63|8@0+ (1,0) [0|0] "" Vector__XXX
 SG_ CAN_TX_MUX_CTA_CAL_MSG_CNT m25 : 15|8@0+ (1,0) [0|0] "" Vector__XXX
 SG_ CAN_TX_MUX_CTA_CAL_DATA_0 m25 : 23|8@0+ (1,0) [0|0] "" Vector__XXX
 SG_ CAN_TX_MUX_CTA_CAL_DATA_1 m25 : 31|8@0+ (1,0) [0|0] "" Vector__XXX
 SG_ CAN_TX_MUX_CTA_CAL_DATA_2 m25 : 39|8@0+ (1,0) [0|0] "" Vector__XXX
 SG_ CAN_TX_MUX_CTA_CAL_DATA_3 m25 : 47|8@0+ (1,0) [0|0] "" Vector__XXX
 SG_ CAN_TX_MUX_CTA_CAL_DATA_4 m25 : 55|8@0+ (1,0) [0|0] "" Vector__XXX
 SG_ CAN_TX_MUX_CTA_CAL_DATA_5 m25 : 63|8@0+ (1,0) [0|0] "" Vector__XXX
 SG_ CAN_TX_MUX_LOOKID_CAL_MSG_CNT m24 : 15|8@0+ (1,0) [0|0] "" Vector__XXX
 SG_ CAN_TX_MUX_LOOKID_CAL_DATA_0 m24 : 23|8@0+ (1,0) [0|0] "" Vector__XXX
 SG_ CAN_TX_MUX_LOOKID_CAL_DATA_1 m24 : 31|8@0+ (1,0) [0|0] "" Vector__XXX
 SG_ CAN_TX_MUX_LOOKID_CAL_DATA_2 m24 : 39|8@0+ (1,0) [0|0] "" Vector__XXX
 SG_ CAN_TX_MUX_LOOKID_CAL_DATA_3 m24 : 47|8@0+ (1,0) [0|0] "" Vector__XXX
 SG_ CAN_TX_MUX_LOOKID_CAL_DATA_4 m24 : 55|8@0+ (1,0) [0|0] "" Vector__XXX
 SG_ CAN_TX_MUX_LOOKID_CAL_DATA_5 m24 : 63|8@0+ (1,0) [0|0] "" Vector__XXX
 SG_ CAN_TX_MUX_ALIGNMENT_CAL_MSG_CNT m23 : 15|8@0+ (1,0) [0|0] "" Vector__XXX
 SG_ CAN_TX_MUX_ALIGNMENT_CAL_DATA_0 m23 : 23|8@0+ (1,0) [0|0] "" Vector__XXX
 SG_ CAN_TX_MUX_ALIGNMENT_CAL_DATA_1 m23 : 31|8@0+ (1,0) [0|0] "" Vector__XXX
 SG_ CAN_TX_MUX_ALIGNMENT_CAL_DATA_2 m23 : 39|8@0+ (1,0) [0|0] "" Vector__XXX
 SG_ CAN_TX_MUX_ALIGNMENT_CAL_DATA_3 m23 : 47|8@0+ (1,0) [0|0] "" Vector__XXX
 SG_ CAN_TX_MUX_ALIGNMENT_CAL_DATA_4 m23 : 55|8@0+ (1,0) [0|0] "" Vector__XXX
 SG_ CAN_TX_MUX_ALIGNMENT_CAL_DATA_5 m23 : 63|8@0+ (1,0) [0|0] "" Vector__XXX
 SG_ CAN_TX_MUX_TRACKER_CAL_MSG_CNT m22 : 15|8@0+ (1,0) [0|0] "" Vector__XXX
 SG_ CAN_TX_MUX_TRACKER_CAL_DATA_0 m22 : 23|8@0+ (1,0) [0|0] "" Vector__XXX
 SG_ CAN_TX_MUX_TRACKER_CAL_DATA_1 m22 : 31|8@0+ (1,0) [0|0] "" Vector__XXX
 SG_ CAN_TX_MUX_TRACKER_CAL_DATA_2 m22 : 39|8@0+ (1,0) [0|0] "" Vector__XXX
 SG_ CAN_TX_MUX_TRACKER_CAL_DATA_3 m22 : 47|8@0+ (1,0) [0|0] "" Vector__XXX
 SG_ CAN_TX_MUX_TRACKER_CAL_DATA_4 m22 : 55|8@0+ (1,0) [0|0] "" Vector__XXX
 SG_ CAN_TX_MUX_TRACKER_CAL_DATA_5 m22 : 63|8@0+ (1,0) [0|0] "" Vector__XXX
 SG_ CAN_TX_MUX_SMC_CAL_MSG_CNT m21 : 15|8@0+ (1,0) [0|0] "" Vector__XXX
 SG_ CAN_TX_MUX_SMC_CAL_DATA_0 m21 : 23|8@0+ (1,0) [0|0] "" Vector__XXX
 SG_ CAN_TX_MUX_SMC_CAL_DATA_1 m21 : 31|8@0+ (1,0) [0|0] "" Vector__XXX
 SG_ CAN_TX_MUX_SMC_CAL_DATA_2 m21 : 39|8@0+ (1,0) [0|0] "" Vector__XXX
 SG_ CAN_TX_MUX_SMC_CAL_DATA_3 m21 : 47|8@0+ (1,0) [0|0] "" Vector__XXX
 SG_ CAN_TX_MUX_SMC_CAL_DATA_4 m21 : 55|8@0+ (1,0) [0|0] "" Vector__XXX
 SG_ CAN_TX_MUX_SMC_CAL_DATA_5 m21 : 63|8@0+ (1,0) [0|0] "" Vector__XXX
 SG_ CAN_TX_MUX_USC_CAL_MSG_CNT m20 : 15|8@0+ (1,0) [0|0] "" Vector__XXX
 SG_ CAN_TX_MUX_USC_CAL_DATA_0 m20 : 23|8@0+ (1,0) [0|0] "" Vector__XXX
 SG_ CAN_TX_MUX_USC_CAL_DATA_1 m20 : 31|8@0+ (1,0) [0|0] "" Vector__XXX
 SG_ CAN_TX_MUX_USC_CAL_DATA_2 m20 : 39|8@0+ (1,0) [0|0] "" Vector__XXX
 SG_ CAN_TX_MUX_USC_CAL_DATA_3 m20 : 47|8@0+ (1,0) [0|0] "" Vector__XXX
 SG_ CAN_TX_MUX_USC_CAL_DATA_4 m20 : 55|8@0+ (1,0) [0|0] "" Vector__XXX
 SG_ CAN_TX_MUX_USC_CAL_DATA_5 m20 : 63|8@0+ (1,0) [0|0] "" Vector__XXX
 SG_ CAN_TX_MUX_ALIGNMENT_CAL_VER_MIN m18 : 15|16@0+ (1,0) [0|0] "" Vector__XXX
 SG_ CAN_TX_MUX_ALIGNMENT_CAL_VER_MAJ m18 : 31|16@0+ (1,0) [0|0] "" Vector__XXX
 SG_ CAN_TX_MUX_ALIGNMENT_SW_VER_MINO m19 : 15|16@0+ (1,0) [0|0] "" Vector__XXX
 SG_ CAN_TX_MUX_ALIGNMENT_SW_VER_MAJO m19 : 31|16@0+ (1,0) [0|0] "" Vector__XXX
 SG_ CAN_TX_MUX_USC_CAL_VER_MAJOR m2 : 15|32@0+ (1,0) [0|0] "" Vector__XXX
 SG_ CAN_TX_MUX_TRACKER_CAL_VER_MINOR m4 : 15|16@0+ (1,0) [0|0] "" Vector__XXX
 SG_ CAN_TX_MUX_TRACKER_CAL_VER_MAJOR m4 : 31|16@0+ (1,0) [0|0] "" Vector__XXX
 SG_ CAN_TX_MUX_TRACKER_SW_VER_MINOR m11 : 15|16@0+ (1,0) [0|0] "" Vector__XXX
 SG_ CAN_TX_MUX_TRACKER_SW_VER_MAJOR m11 : 31|16@0+ (1,0) [0|0] "" Vector__XXX
 SG_ CAN_TX_MUX_SMC_CAL_VER_MINOR m3 : 15|16@0+ (1,0) [0|0] "" Vector__XXX
 SG_ CAN_TX_MUX_SMC_CAL_VER_MAJOR m3 : 31|16@0+ (1,0) [0|0] "" Vector__XXX
 SG_ CAN_TX_MUX_RECW_CAL_VER_MINOR m8 : 15|16@0+ (1,0) [0|0] "" Vector__XXX
 SG_ CAN_TX_MUX_RECW_CAL_VER_MAJOR m8 : 31|16@0+ (1,0) [0|0] "" Vector__XXX
 SG_ CAN_TX_MUX_RECW_SW_VER_MINOR m12 : 15|16@0+ (1,0) [0|0] "" Vector__XXX
 SG_ CAN_TX_MUX_RECW_SW_VER_MAJOR m12 : 31|16@0+ (1,0) [0|0] "" Vector__XXX
 SG_ CAN_TX_MUX_RCWM_CAL_VER_MINOR m9 : 15|16@0+ (1,0) [0|0] "" Vector__XXX
 SG_ CAN_TX_MUX_RCWM_CAL_VER_MAJOR m9 : 31|16@0+ (1,0) [0|0] "" Vector__XXX
 SG_ CAN_TX_MUX_RCWM_SW_VER_MINOR m13 : 15|16@0+ (1,0) [0|0] "" Vector__XXX
 SG_ CAN_TX_MUX_RCWM_SW_VER_MAJOR m13 : 31|16@0+ (1,0) [0|0] "" Vector__XXX
 SG_ CAN_TX_MUX_RCTA_CAL_VER_MINOR m6 : 15|16@0+ (1,0) [0|0] "" Vector__XXX
 SG_ CAN_TX_MUX_RCTA_CAL_VER_MAJOR m6 : 31|16@0+ (1,0) [0|0] "" Vector__XXX
 SG_ CAN_TX_MUX_RCTA_SW_VER_MINOR m14 : 15|16@0+ (1,0) [0|0] "" Vector__XXX
 SG_ CAN_TX_MUX_RCTA_SW_VER_MAJOR m14 : 31|16@0+ (1,0) [0|0] "" Vector__XXX
 SG_ CAN_TX_MUX_LCDA_CAL_VER_MINOR m5 : 15|16@0+ (1,0) [0|0] "" Vector__XXX
 SG_ CAN_TX_MUX_LCDA_CAL_VER_MAJOR m5 : 31|16@0+ (1,0) [0|0] "" Vector__XXX
 SG_ CAN_TX_MUX_LCDA_SW_VER_MINOR m15 : 15|16@0+ (1,0) [0|0] "" Vector__XXX
 SG_ CAN_TX_MUX_LCDA_SW_VER_MAJOR m15 : 31|16@0+ (1,0) [0|0] "" Vector__XXX
 SG_ CAN_TX_MUX_FREESP_CAL_VER_MINOR m10 : 15|16@0+ (1,0) [0|0] "" Vector__XXX
 SG_ CAN_TX_MUX_FREESP_CAL_VER_MAJOR m10 : 31|16@0+ (1,0) [0|0] "" Vector__XXX
 SG_ CAN_TX_MUX_FREESP_SW_VER_MINOR m16 : 15|16@0+ (1,0) [0|0] "" Vector__XXX
 SG_ CAN_TX_MUX_FREESP_SW_VER_MAJOR m16 : 31|16@0+ (1,0) [0|0] "" Vector__XXX
 SG_ CAN_TX_MUX_FCTA_CAL_VER_MINOR m7 : 15|16@0+ (1,0) [0|0] "" Vector__XXX
 SG_ CAN_TX_MUX_FCTA_CAL_VER_MAJOR m7 : 31|16@0+ (1,0) [0|0] "" Vector__XXX
 SG_ CAN_TX_MUX_FCTA_SW_VER_MINOR m17 : 15|16@0+ (1,0) [0|0] "" Vector__XXX
 SG_ CAN_TX_MUX_FCTA_SW_VER_MAJOR m17 : 31|16@0+ (1,0) [0|0] "" Vector__XXX
 SG_ CAN_TX_MUX_VCS_OFFSET_LONG m1 : 31|16@0- (1,0) [0|0] "cm" Vector__XXX
 SG_ CAN_TX_MUX_VCS_OFFSET_LAT m1 : 15|16@0- (1,0) [0|0] "cm" Vector__XXX
 SG_ CAN_TX_MUX_CORE_VERSION m0 : 63|8@0+ (1,0) [0|0] "" Vector__XXX
 SG_ CAN_TX_MUX_SENSOR_POLARITY m0 : 47|1@0+ (1,0) [0|1] "" Vector__XXX
 SG_ CAN_TX_MUX_SENSOR_LAT_OFFSET m0 : 46|15@0+ (0.01,-200) [-200|200] "" Vector__XXX
 SG_ CAN_TX_MUX_SENSOR_LONG_OFFSET m0 : 31|16@0+ (0.01,0) [0|655.35] "cm" Vector__XXX
 SG_ CAN_TX_MUX_SENSOR_ANGLE_OFFSET m0 : 15|16@0+ (0.01,-200) [-200|200] "deg" Vector__XXX
 SG_ CAN_TX_MUX_KINK_ANGLE_VER_MINOR m30 : 15|16@0+ (1,0) [0|0] "" Vector__XXX
 SG_ CAN_TX_MUX_KINK_ANGLE_VER_MAJOR m30 : 31|16@0+ (1,0) [0|0] "" Vector__XXX
 SG_ CAN_TX_MUX_ID M : 7|8@0+ (1,0) [0|255] "" Vector__XXX

BO_ 1600 SODRR_TrackStatus: 8 SODRR
 SG_ CAN_TX_LOOK_INDEX_8 : 31|8@0+ (1,0) [0|0] "" Vector__XXX
 SG_ CAN_TX_SCAN_INDEX_TRACKER_OWN : 23|8@0+ (1,0) [0|0] "" Vector__XXX
 SG_ CAN_TX_SCAN_INDEX_TRACKER_FUSED : 7|8@0+ (1,0) [0|0] "" Vector__XXX
 SG_ CAN_TX_LOOK_TYPE : 15|1@0+ (1,0) [0|0] "" Vector__XXX
 SG_ CAN_TX_LOOK_ID : 14|7@0+ (1,0) [0|0] "" Vector__XXX
 SG_ CAN_TX_SYSTEM_TIME_STAMP : 39|32@0+ (1,0) [0|0] "" Vector__XXX

BO_ 261 SODRR_Status06: 8 SODRR
 SG_ USC_Load_Error : 59|1@0+ (1,0) [0|0] "" Vector__XXX
 SG_ SMC_Load_Error : 58|1@0+ (1,0) [0|0] "" Vector__XXX
 SG_ TX_Temperature_Fault : 57|1@0+ (1,0) [0|0] "" Vector__XXX
 SG_ DSP_Unit_Cal_Block_Chcksm_Error : 56|1@0+ (1,0) [0|0] "" Vector__XXX
 SG_ DSP_Unit_Cal_Checksum_Error : 55|1@0+ (1,0) [0|0] "" Vector__XXX
 SG_ Vertical_Misalignment_error : 54|1@0+ (1,0) [0|0] "" Vector__XXX
 SG_ RTN_SPI_Transfer_Error : 53|1@0+ (1,0) [0|0] "" Vector__XXX
 SG_ RRN_SPI_Transfer_Error : 52|1@0+ (1,0) [0|0] "" Vector__XXX
 SG_ Linearizer_SPI_Transfer_Error : 51|1@0+ (1,0) [0|0] "" Vector__XXX
 SG_ ADC_SPI_Transfer_Error : 50|1@0+ (1,0) [0|0] "" Vector__XXX
 SG_ Transmitter_ID_Error : 49|1@0+ (1,0) [0|0] "" Vector__XXX
 SG_ DSP_Loop_Overrun_Error : 48|1@0+ (1,0) [0|0] "" Vector__XXX
 SG_ Saturated_Tuning_Freq_Error : 47|1@0+ (1,0) [0|0] "" Vector__XXX
 SG_ Radar_Data_sync_error : 46|1@0+ (1,0) [0|0] "" Vector__XXX
 SG_ DSP_Tuning_Sensitivity_Error : 45|1@0+ (1,0) [0|0] "" Vector__XXX
 SG_ Radar_LO_Power_Error : 44|1@0+ (1,0) [0|0] "" Vector__XXX
 SG_ Radar_TX_Power_Error : 43|1@0+ (1,0) [0|0] "" Vector__XXX
 SG_ Timer_Create_Error : 6|1@0+ (1,0) [0|0] "" Vector__XXX
 SG_ Thread_Create_Error : 2|1@0+ (1,0) [0|0] "" Vector__XXX
 SG_ ARM_Calibration_Error : 9|1@0+ (1,0) [0|0] "" Vector__XXX
 SG_ SPI_FEE_Error : 14|1@0+ (1,0) [0|0] "" Vector__XXX
 SG_ SPI_Comm_Error : 13|1@0+ (1,0) [0|0] "" Vector__XXX
 SG_ Socket_Write_Error : 39|1@0+ (1,0) [0|0] "" Vector__XXX
 SG_ Socket_Read_error : 38|1@0+ (1,0) [0|0] "" Vector__XXX
 SG_ Socket_Init_Error : 37|1@0+ (1,0) [0|0] "" Vector__XXX
 SG_ Signal_Wait_Error : 4|1@0+ (1,0) [0|0] "" Vector__XXX
 SG_ Signal_Send_Error : 5|1@0+ (1,0) [0|0] "" Vector__XXX
 SG_ Signal_Create_Error : 3|1@0+ (1,0) [0|0] "" Vector__XXX
 SG_ Shared_Mem_Write_Error : 21|1@0+ (1,0) [0|0] "" Vector__XXX
 SG_ Shared_Mem_Read_Error : 20|1@0+ (1,0) [0|0] "" Vector__XXX
 SG_ Shared_Mem_Config_Error : 19|1@0+ (1,0) [0|0] "" Vector__XXX
 SG_ Share_Mem_Init_Error : 18|1@0+ (1,0) [0|0] "" Vector__XXX
 SG_ RAM_Test_Error : 1|1@0+ (1,0) [0|0] "" Vector__XXX
 SG_ Num_Errors : 63|1@0+ (1,0) [0|0] "" Vector__XXX
 SG_ MMAP_Memory_Error : 40|1@0+ (1,0) [0|0] "" Vector__XXX
 SG_ ISR_Attach_Error : 36|1@0+ (1,0) [0|0] "" Vector__XXX
 SG_ IPC_DRV_Write_Error : 29|1@0+ (1,0) [0|0] "" Vector__XXX
 SG_ IPC_DRV_Trigger_Error : 31|1@0+ (1,0) [0|0] "" Vector__XXX
 SG_ IPC_DRV_Sync_Error : 30|1@0+ (1,0) [0|0] "" Vector__XXX
 SG_ IPC_DRV_Read_Error : 28|1@0+ (1,0) [0|0] "" Vector__XXX
 SG_ IPC_DRV_Init_Error : 27|1@0+ (1,0) [0|0] "" Vector__XXX
 SG_ Interrupt_Enable_Error : 42|1@0+ (1,0) [0|0] "" Vector__XXX
 SG_ HIL_Format_Error : 41|1@0+ (1,0) [0|0] "" Vector__XXX
 SG_ Flash_Filesystem_Error : 7|1@0+ (1,0) [0|0] "" Vector__XXX
 SG_ Error_none : 0|1@0+ (1,0) [0|0] "" Vector__XXX
 SG_ DSP_Load_Read_Error : 34|1@0+ (1,0) [0|0] "" Vector__XXX
 SG_ DSP_Load_Open_Error : 33|1@0+ (1,0) [0|0] "" Vector__XXX
 SG_ DSP_Load_Address_Error : 35|1@0+ (1,0) [0|0] "" Vector__XXX
 SG_ DSP_ISP_Write_Error : 17|1@0+ (1,0) [0|0] "" Vector__XXX
 SG_ DSP_IPC_Read_Error : 16|1@0+ (1,0) [0|0] "" Vector__XXX
 SG_ DSP_IPC_Init : 15|1@0+ (1,0) [0|0] "" Vector__XXX
 SG_ DSP_Init_Error : 32|1@0+ (1,0) [0|0] "" Vector__XXX
 SG_ DSP_DRV_Start_Error : 26|1@0+ (1,0) [0|0] "" Vector__XXX
 SG_ DSP_DRV_Load_Error : 25|1@0+ (1,0) [0|0] "" Vector__XXX
 SG_ DSP_DRV_Init_Error : 22|1@0+ (1,0) [0|0] "" Vector__XXX
 SG_ DSP_DRV_Init2_error : 24|1@0+ (1,0) [0|0] "" Vector__XXX
 SG_ DSP_DRV_Init1_error : 23|1@0+ (1,0) [0|0] "" Vector__XXX
 SG_ CAN_XMT_Error : 10|1@0+ (1,0) [0|0] "" Vector__XXX
 SG_ CAN_RCV_Error : 11|1@0+ (1,0) [0|0] "" Vector__XXX
 SG_ CAN_Hardware_Error : 12|1@0+ (1,0) [0|0] "" Vector__XXX
 SG_ Always_True : 62|1@0+ (1,0) [0|0] "" Vector__XXX

BO_ 260 SODRR_Status05: 8 SODRR
 SG_ Software_Incompatible_Fault : 61|1@0+ (1,0) [0|0] "" Vector__XXX
 SG_ Host_Spi_Checksum_Fault : 60|1@0+ (1,0) [0|0] "" Vector__XXX
 SG_ Loss_Of_Comm_With_Dsp_Fault : 59|1@0+ (1,0) [0|0] "" Vector__XXX
 SG_ No_Communication_With_Arm_Fault : 58|1@0+ (1,0) [0|0] "" Vector__XXX
 SG_ Communication_With_Host_Fault : 57|1@0+ (1,0) [0|0] "" Vector__XXX
 SG_ Communication_With_Arm_Fault : 56|1@0+ (1,0) [0|0] "" Vector__XXX
 SG_ Dsp_Loop_Overrun_Fault_Dsp : 51|1@0+ (1,0) [0|0] "" Vector__XXX
 SG_ Tuning_Sensitivity_Fault : 50|1@0+ (1,0) [0|0] "" Vector__XXX
 SG_ Saturated_Tuning_Frequency_Fault : 49|1@0+ (1,0) [0|0] "" Vector__XXX
 SG_ Local_Oscillator_Power_Fault : 48|1@0+ (1,0) [0|0] "" Vector__XXX
 SG_ Transmitter_Power_Fault : 47|1@0+ (1,0) [0|0] "" Vector__XXX
 SG_ Radar_Data_Sync_Fault : 46|1@0+ (1,0) [0|0] "" Vector__XXX
 SG_ Dsp_Spi_Hardware_Fault : 45|1@0+ (1,0) [0|0] "" Vector__XXX
 SG_ Transmitter_Device_Spi_Fault : 44|1@0+ (1,0) [0|0] "" Vector__XXX
 SG_ Receiver_Device_Spi_Fault : 43|1@0+ (1,0) [0|0] "" Vector__XXX
 SG_ Freq_Synthesizer_Devce_Spi_Fault : 42|1@0+ (1,0) [0|0] "" Vector__XXX
 SG_ Analog_Convrtor_Device_Spi_Fault : 41|1@0+ (1,0) [0|0] "" Vector__XXX
 SG_ Transmitter_Id_Fault : 40|1@0+ (1,0) [0|0] "" Vector__XXX
 SG_ Ecu_Temperature_High_Fault : 39|1@0+ (1,0) [0|0] "" Vector__XXX
 SG_ Transmitter_Tempratre_High_Fault : 38|1@0+ (1,0) [0|0] "" Vector__XXX
 SG_ Alignment_Routine_Failed_Fault : 37|1@0+ (1,0) [0|0] "" Vector__XXX
 SG_ Unreasonable_Radar_Data : 36|1@0+ (1,0) [0|0] "" Vector__XXX
 SG_ Sensor_Blocked_Fault : 35|1@0+ (1,0) [0|0] "" Vector__XXX
 SG_ Vertical_Alignment_Out_Of_Range : 34|1@0+ (1,0) [0|0] "" Vector__XXX
 SG_ Horizontal_Align_Out_Of_Range : 33|1@0+ (1,0) [0|0] "" Vector__XXX
 SG_ Factory_Alignment_Mode : 32|1@0+ (1,0) [0|0] "" Vector__XXX
 SG_ Battery_Low_Fault : 30|1@0+ (1,0) [0|0] "" Vector__XXX
 SG_ Battery_High_Fault : 29|1@0+ (1,0) [0|0] "" Vector__XXX
 SG_ Ecu_Position_Configuration_Fault : 28|1@0+ (1,0) [0|0] "" Vector__XXX
 SG_ Supply_1_1v_Out_Of_Range_Fault : 27|1@0+ (1,0) [0|0] "" Vector__XXX
 SG_ Supply_1_8v_Out_Of_Range_Fault : 26|1@0+ (1,0) [0|0] "" Vector__XXX
 SG_ Thermistor_Out_Of_Range_Fault : 25|1@0+ (1,0) [0|0] "" Vector__XXX
 SG_ Supply_5v_Out_Of_Range_Fault : 24|1@0+ (1,0) [0|0] "" Vector__XXX
 SG_ Pcan_Init_Missing_Message_Fault : 22|1@0+ (1,0) [0|0] "" Vector__XXX
 SG_ Pcan_Trk_Data_Unreasonable_Fault : 21|1@0+ (1,0) [0|0] "" Vector__XXX
 SG_ Pcan_Data_Range_Check_Fault : 20|1@0+ (1,0) [0|0] "" Vector__XXX
 SG_ Pcan_Missing_Message_Fault : 19|1@0+ (1,0) [0|0] "" Vector__XXX
 SG_ Pcan_Hw_Rx_Buffer_Fault : 18|1@0+ (1,0) [0|0] "" Vector__XXX
 SG_ Pcan_Sw_Buffer_Fault : 17|1@0+ (1,0) [0|0] "" Vector__XXX
 SG_ Pcan_Bus_Off : 16|1@0+ (1,0) [0|0] "" Vector__XXX
 SG_ Host_Instruction_Set_Check_Fault : 15|1@0+ (1,0) [0|0] "" Vector__XXX
 SG_ Host_Stack_Overflow_Fault : 14|1@0+ (1,0) [0|0] "" Vector__XXX
 SG_ Sensor_Watchdog_Fault : 13|1@0+ (1,0) [0|0] "" Vector__XXX
 SG_ Sensor_Pll_Lock_Fault : 12|1@0+ (1,0) [0|0] "" Vector__XXX
 SG_ Host_Pll_Lock_Fault : 11|1@0+ (1,0) [0|0] "" Vector__XXX
 SG_ Sensor_Ram_Memory_Test_Fault : 8|1@0+ (1,0) [0|0] "" Vector__XXX
 SG_ Host_Ram_Memory_Test_Fault : 7|1@0+ (1,0) [0|0] "" Vector__XXX
 SG_ Sensor_Custmr_Cal_Flash_Checksum : 6|1@0+ (1,0) [0|0] "" Vector__XXX
 SG_ Dsp_Usc_Validation_Fault : 5|1@0+ (1,0) [0|0] "" Vector__XXX
 SG_ Sensor_Pgrm_Cal_Flash_Checksum : 4|1@0+ (1,0) [0|0] "" Vector__XXX
 SG_ Sensor_App_Flash_Checksum_Fault : 3|1@0+ (1,0) [0|0] "" Vector__XXX
 SG_ Host_Keep_Alv_Flash_Chcksm_Fault : 2|1@0+ (1,0) [0|0] "" Vector__XXX
 SG_ Host_Pgm_Cal_Flash_Chcksum_Fault : 1|1@0+ (1,0) [0|0] "" Vector__XXX
 SG_ Host_App_Flash_Checksum_Fault : 0|1@0+ (1,0) [0|0] "" Vector__XXX

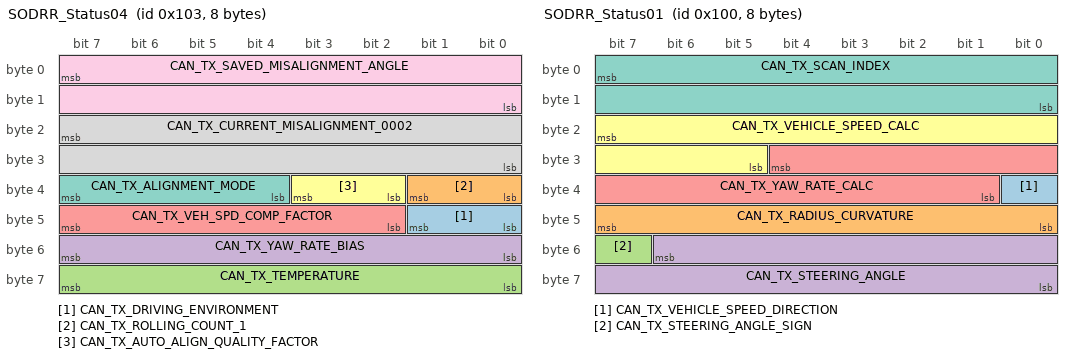
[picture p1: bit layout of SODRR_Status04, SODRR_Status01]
BO_ 259 SODRR_Status04: 8 SODRR
 SG_ CAN_TX_DRIVING_ENVIRONMENT : 41|2@0+ (1,0) [0|0] "" Vector__XXX
 SG_ CAN_TX_ROLLING_COUNT_1 : 33|2@0+ (1,0) [0|0] "" Vector__XXX
 SG_ CAN_TX_TEMPERATURE : 63|8@0+ (1,-50) [-50|205] "degC" Vector__XXX
 SG_ CAN_TX_YAW_RATE_BIAS : 55|8@0- (0.125,0) [-16|15.875] "" Vector__XXX
 SG_ CAN_TX_VEH_SPD_COMP_FACTOR : 47|6@0- (0.001953125,1) [0.9375|1.060546875] "" Vector__XXX
 SG_ CAN_TX_AUTO_ALIGN_QUALITY_FACTOR : 35|2@0+ (1,0) [0|0] "" Vector__XXX
 SG_ CAN_TX_ALIGNMENT_MODE : 39|4@0+ (1,0) [0|0] "" Vector__XXX
 SG_ CAN_TX_CURRENT_MISALIGNMENT_0002 : 23|16@0- (0.0009765625,0) [-10|10] "Deg" Vector__XXX
 SG_ CAN_TX_SAVED_MISALIGNMENT_ANGLE : 7|16@0- (0.0009765625,0) [-10|10] "Deg" Vector__XXX

BO_ 256 SODRR_Status01: 8 SODRR
 SG_ CAN_TX_VEHICLE_SPEED_DIRECTION : 32|1@0+ (1,0) [0|0] "" Vector__XXX
 SG_ CAN_TX_RADIUS_CURVATURE : 47|8@0- (25,0) [-3200|3200] "m" Vector__XXX
 SG_ CAN_TX_STEERING_ANGLE_SIGN : 55|1@0+ (1,0) [0|1] "" Vector__XXX
 SG_ CAN_TX_STEERING_ANGLE : 54|15@0+ (1,0) [0|32767] "deg" Vector__XXX
 SG_ CAN_TX_YAW_RATE_CALC : 28|12@0- (0.0625,0) [-128|127.9375] "deg/s" Vector__XXX
 SG_ CAN_TX_VEHICLE_SPEED_CALC : 23|11@0+ (0.0625,0) [0|127.9375] "m/s" Vector__XXX
 SG_ CAN_TX_SCAN_INDEX : 7|16@0+ (1,0) [0|65535] "" Vector__XXX

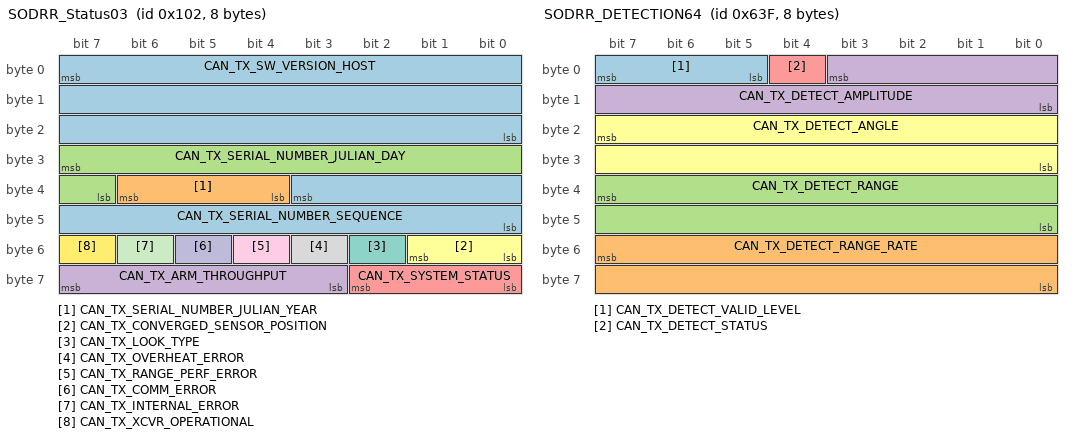
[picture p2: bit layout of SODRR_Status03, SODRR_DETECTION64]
BO_ 258 SODRR_Status03: 8 SODRR
 SG_ CAN_TX_SERIAL_NUMBER_SEQUENCE : 35|12@0+ (1,0) [0|0] "" Vector__XXX
 SG_ CAN_TX_SERIAL_NUMBER_JULIAN_YEAR : 38|3@0+ (1,2014) [0|0] "" Vector__XXX
 SG_ CAN_TX_SERIAL_NUMBER_JULIAN_DAY : 31|9@0+ (1,0) [0|0] "" Vector__XXX
 SG_ CAN_TX_ARM_THROUGHPUT : 59|5@1+ (3.2258,0) [0|0] "" Vector__XXX
 SG_ CAN_TX_SYSTEM_STATUS : 58|3@0+ (1,0) [0|0] "" Vector__XXX
 SG_ CAN_TX_CONVERGED_SENSOR_POSITION : 49|2@0+ (1,0) [0|0] "" Vector__XXX
 SG_ CAN_TX_LOOK_TYPE : 50|1@0+ (1,0) [0|0] "" Vector__XXX
 SG_ CAN_TX_OVERHEAT_ERROR : 51|1@0+ (1,0) [0|0] "" Vector__XXX
 SG_ CAN_TX_RANGE_PERF_ERROR : 52|1@0+ (1,0) [0|0] "" Vector__XXX
 SG_ CAN_TX_COMM_ERROR : 53|1@0+ (1,0) [0|0] "" Vector__XXX
 SG_ CAN_TX_INTERNAL_ERROR : 54|1@0+ (1,0) [0|0] "" Vector__XXX
 SG_ CAN_TX_XCVR_OPERATIONAL : 55|1@0+ (1,0) [0|0] "" Vector__XXX
 SG_ CAN_TX_SW_VERSION_HOST : 7|24@0+ (1,0) [0|0] "" Vector__XXX

BO_ 257 SODRR_Status02: 8 SODRR
 SG_ CAN_TX_SW_VERSION_DSP : 47|24@0+ (1,0) [0|0] "" Vector__XXX
 SG_ CAN_TX_PCAN_PROTOCOL_MINOR : 15|8@0+ (1,0) [0|255] "" Vector__XXX
 SG_ CAN_TX_PCAN_PROTOCOL_MAJOR : 3|4@0+ (1,0) [0|15] "" Vector__XXX
 SG_ CAN_TX_SW_VERSION_ARM : 23|24@0+ (1,0) [0|0] "" Vector__XXX
 SG_ CAN_TX_HW_VERSION : 7|4@0+ (1,0) [0|0] "" Vector__XXX

BO_ 1599 SODRR_DETECTION64: 8 SODRR
 SG_ CAN_TX_DETECT_VALID_LEVEL : 7|3@0+ (1,0) [0|0] "" Vector__XXX
 SG_ CAN_TX_DETECT_RANGE_RATE : 55|16@0- (0.0078125,0) [-81.92|81.91] "m/s" Vector__XXX
 SG_ CAN_TX_DETECT_RANGE : 39|16@0- (0.0078125,0) [0|204.7] "m" Vector__XXX
 SG_ CAN_TX_DETECT_AMPLITUDE : 3|12@0- (0.125,0) [-24|40] "dBsm" Vector__XXX
 SG_ CAN_TX_DETECT_STATUS : 4|1@0+ (1,0) [0|1] "" Vector__XXX
 SG_ CAN_TX_DETECT_ANGLE : 23|16@0- (0.0078125,0) [-102.4|102.2] "deg" Vector__XXX

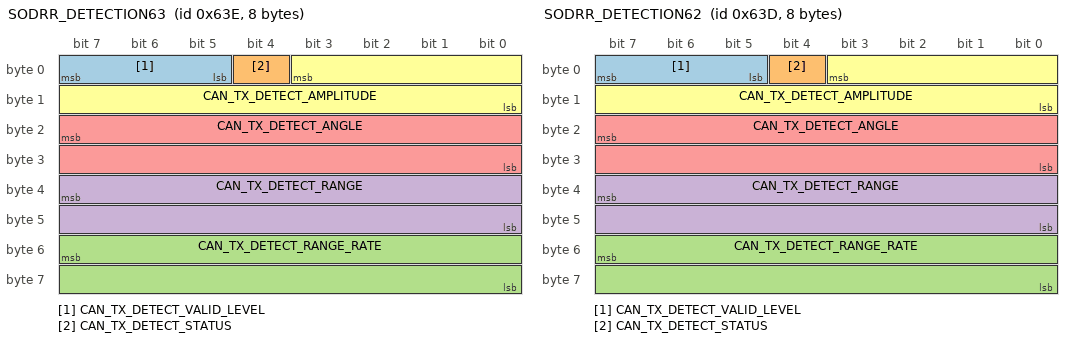
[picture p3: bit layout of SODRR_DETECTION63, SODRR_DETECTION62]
BO_ 1598 SODRR_DETECTION63: 8 SODRR
 SG_ CAN_TX_DETECT_VALID_LEVEL : 7|3@0+ (1,0) [0|0] "" Vector__XXX
 SG_ CAN_TX_DETECT_STATUS : 4|1@0+ (1,0) [0|1] "" Vector__XXX
 SG_ CAN_TX_DETECT_RANGE_RATE : 55|16@0- (0.0078125,0) [-81.92|81.91] "m/s" Vector__XXX
 SG_ CAN_TX_DETECT_RANGE : 39|16@0- (0.0078125,0) [0|204.7] "m" Vector__XXX
 SG_ CAN_TX_DETECT_ANGLE : 23|16@0- (0.0078125,0) [-102.4|102.2] "deg" Vector__XXX
 SG_ CAN_TX_DETECT_AMPLITUDE : 3|12@0- (0.125,0) [-24|40] "dBsm" Vector__XXX

BO_ 1597 SODRR_DETECTION62: 8 SODRR
 SG_ CAN_TX_DETECT_VALID_LEVEL : 7|3@0+ (1,0) [0|0] "" Vector__XXX
 SG_ CAN_TX_DETECT_STATUS : 4|1@0+ (1,0) [0|1] "" Vector__XXX
 SG_ CAN_TX_DETECT_RANGE_RATE : 55|16@0- (0.0078125,0) [-81.92|81.91] "m/s" Vector__XXX
 SG_ CAN_TX_DETECT_RANGE : 39|16@0- (0.0078125,0) [0|204.7] "m" Vector__XXX
 SG_ CAN_TX_DETECT_ANGLE : 23|16@0- (0.0078125,0) [-102.4|102.2] "deg" Vector__XXX
 SG_ CAN_TX_DETECT_AMPLITUDE : 3|12@0- (0.125,0) [-24|40] "dBsm" Vector__XXX

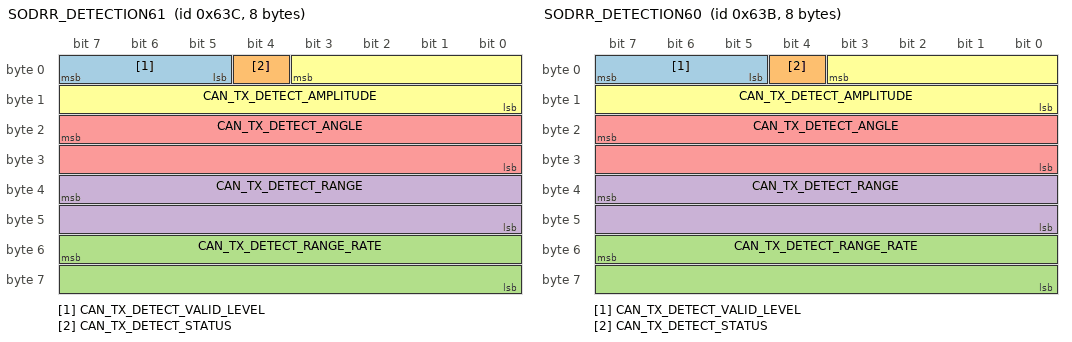
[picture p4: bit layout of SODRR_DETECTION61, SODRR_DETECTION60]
BO_ 1596 SODRR_DETECTION61: 8 SODRR
 SG_ CAN_TX_DETECT_VALID_LEVEL : 7|3@0+ (1,0) [0|0] "" Vector__XXX
 SG_ CAN_TX_DETECT_STATUS : 4|1@0+ (1,0) [0|1] "" Vector__XXX
 SG_ CAN_TX_DETECT_RANGE_RATE : 55|16@0- (0.0078125,0) [-81.92|81.91] "m/s" Vector__XXX
 SG_ CAN_TX_DETECT_RANGE : 39|16@0- (0.0078125,0) [0|204.7] "m" Vector__XXX
 SG_ CAN_TX_DETECT_ANGLE : 23|16@0- (0.0078125,0) [-102.4|102.2] "deg" Vector__XXX
 SG_ CAN_TX_DETECT_AMPLITUDE : 3|12@0- (0.125,0) [-24|40] "dBsm" Vector__XXX

BO_ 1595 SODRR_DETECTION60: 8 SODRR
 SG_ CAN_TX_DETECT_VALID_LEVEL : 7|3@0+ (1,0) [0|0] "" Vector__XXX
 SG_ CAN_TX_DETECT_STATUS : 4|1@0+ (1,0) [0|1] "" Vector__XXX
 SG_ CAN_TX_DETECT_RANGE_RATE : 55|16@0- (0.0078125,0) [-81.92|81.91] "m/s" Vector__XXX
 SG_ CAN_TX_DETECT_RANGE : 39|16@0- (0.0078125,0) [0|204.7] "m" Vector__XXX
 SG_ CAN_TX_DETECT_ANGLE : 23|16@0- (0.0078125,0) [-102.4|102.2] "deg" Vector__XXX
 SG_ CAN_TX_DETECT_AMPLITUDE : 3|12@0- (0.125,0) [-24|40] "dBsm" Vector__XXX

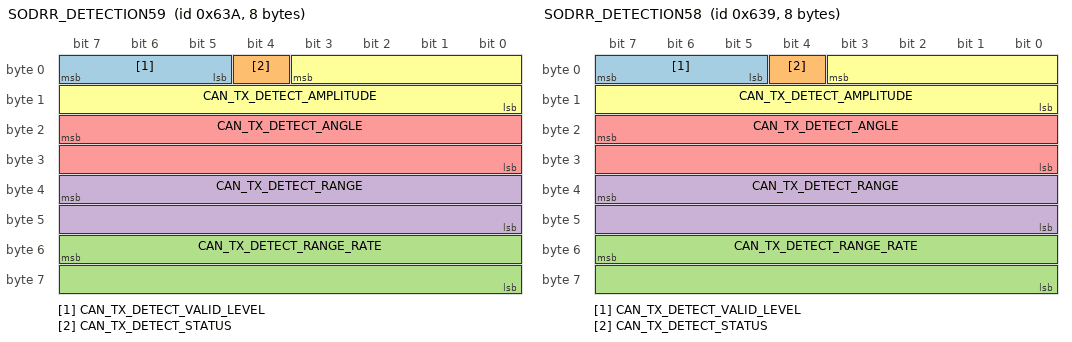
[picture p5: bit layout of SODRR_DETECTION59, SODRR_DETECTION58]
BO_ 1594 SODRR_DETECTION59: 8 SODRR
 SG_ CAN_TX_DETECT_VALID_LEVEL : 7|3@0+ (1,0) [0|0] "" Vector__XXX
 SG_ CAN_TX_DETECT_STATUS : 4|1@0+ (1,0) [0|1] "" Vector__XXX
 SG_ CAN_TX_DETECT_RANGE_RATE : 55|16@0- (0.0078125,0) [-81.92|81.91] "m/s" Vector__XXX
 SG_ CAN_TX_DETECT_RANGE : 39|16@0- (0.0078125,0) [0|204.7] "m" Vector__XXX
 SG_ CAN_TX_DETECT_ANGLE : 23|16@0- (0.0078125,0) [-102.4|102.2] "deg" Vector__XXX
 SG_ CAN_TX_DETECT_AMPLITUDE : 3|12@0- (0.125,0) [-24|40] "dBsm" Vector__XXX

BO_ 1593 SODRR_DETECTION58: 8 SODRR
 SG_ CAN_TX_DETECT_VALID_LEVEL : 7|3@0+ (1,0) [0|0] "" Vector__XXX
 SG_ CAN_TX_DETECT_STATUS : 4|1@0+ (1,0) [0|1] "" Vector__XXX
 SG_ CAN_TX_DETECT_RANGE_RATE : 55|16@0- (0.0078125,0) [-81.92|81.91] "m/s" Vector__XXX
 SG_ CAN_TX_DETECT_RANGE : 39|16@0- (0.0078125,0) [0|204.7] "m" Vector__XXX
 SG_ CAN_TX_DETECT_ANGLE : 23|16@0- (0.0078125,0) [-102.4|102.2] "deg" Vector__XXX
 SG_ CAN_TX_DETECT_AMPLITUDE : 3|12@0- (0.125,0) [-24|40] "dBsm" Vector__XXX

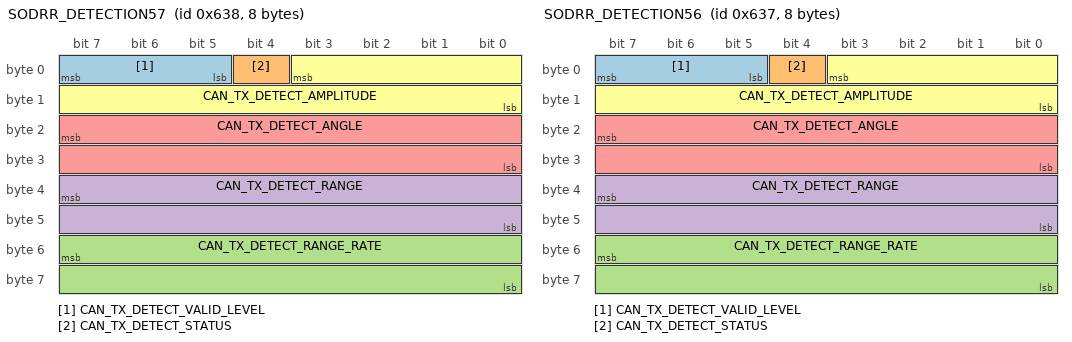
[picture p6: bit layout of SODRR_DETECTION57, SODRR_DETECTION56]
BO_ 1592 SODRR_DETECTION57: 8 SODRR
 SG_ CAN_TX_DETECT_VALID_LEVEL : 7|3@0+ (1,0) [0|0] "" Vector__XXX
 SG_ CAN_TX_DETECT_STATUS : 4|1@0+ (1,0) [0|1] "" Vector__XXX
 SG_ CAN_TX_DETECT_RANGE_RATE : 55|16@0- (0.0078125,0) [-81.92|81.91] "m/s" Vector__XXX
 SG_ CAN_TX_DETECT_RANGE : 39|16@0- (0.0078125,0) [0|204.7] "m" Vector__XXX
 SG_ CAN_TX_DETECT_ANGLE : 23|16@0- (0.0078125,0) [-102.4|102.2] "deg" Vector__XXX
 SG_ CAN_TX_DETECT_AMPLITUDE : 3|12@0- (0.125,0) [-24|40] "dBsm" Vector__XXX

BO_ 1591 SODRR_DETECTION56: 8 SODRR
 SG_ CAN_TX_DETECT_VALID_LEVEL : 7|3@0+ (1,0) [0|0] "" Vector__XXX
 SG_ CAN_TX_DETECT_STATUS : 4|1@0+ (1,0) [0|1] "" Vector__XXX
 SG_ CAN_TX_DETECT_RANGE_RATE : 55|16@0- (0.0078125,0) [-81.92|81.91] "m/s" Vector__XXX
 SG_ CAN_TX_DETECT_RANGE : 39|16@0- (0.0078125,0) [0|204.7] "m" Vector__XXX
 SG_ CAN_TX_DETECT_ANGLE : 23|16@0- (0.0078125,0) [-102.4|102.2] "deg" Vector__XXX
 SG_ CAN_TX_DETECT_AMPLITUDE : 3|12@0- (0.125,0) [-24|40] "dBsm" Vector__XXX

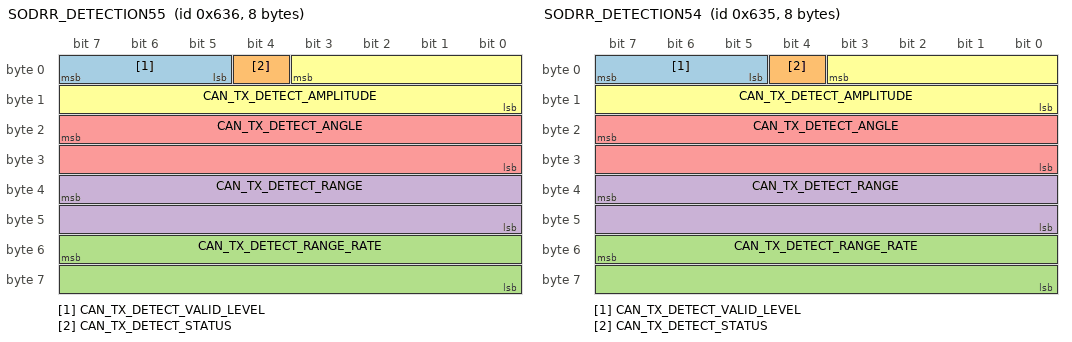
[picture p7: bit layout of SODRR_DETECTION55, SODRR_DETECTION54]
BO_ 1590 SODRR_DETECTION55: 8 SODRR
 SG_ CAN_TX_DETECT_VALID_LEVEL : 7|3@0+ (1,0) [0|0] "" Vector__XXX
 SG_ CAN_TX_DETECT_STATUS : 4|1@0+ (1,0) [0|1] "" Vector__XXX
 SG_ CAN_TX_DETECT_RANGE_RATE : 55|16@0- (0.0078125,0) [-81.92|81.91] "m/s" Vector__XXX
 SG_ CAN_TX_DETECT_RANGE : 39|16@0- (0.0078125,0) [0|204.7] "m" Vector__XXX
 SG_ CAN_TX_DETECT_ANGLE : 23|16@0- (0.0078125,0) [-102.4|102.2] "deg" Vector__XXX
 SG_ CAN_TX_DETECT_AMPLITUDE : 3|12@0- (0.125,0) [-24|40] "dBsm" Vector__XXX

BO_ 1589 SODRR_DETECTION54: 8 SODRR
 SG_ CAN_TX_DETECT_VALID_LEVEL : 7|3@0+ (1,0) [0|0] "" Vector__XXX
 SG_ CAN_TX_DETECT_STATUS : 4|1@0+ (1,0) [0|1] "" Vector__XXX
 SG_ CAN_TX_DETECT_RANGE_RATE : 55|16@0- (0.0078125,0) [-81.92|81.91] "m/s" Vector__XXX
 SG_ CAN_TX_DETECT_RANGE : 39|16@0- (0.0078125,0) [0|204.7] "m" Vector__XXX
 SG_ CAN_TX_DETECT_ANGLE : 23|16@0- (0.0078125,0) [-102.4|102.2] "deg" Vector__XXX
 SG_ CAN_TX_DETECT_AMPLITUDE : 3|12@0- (0.125,0) [-24|40] "dBsm" Vector__XXX

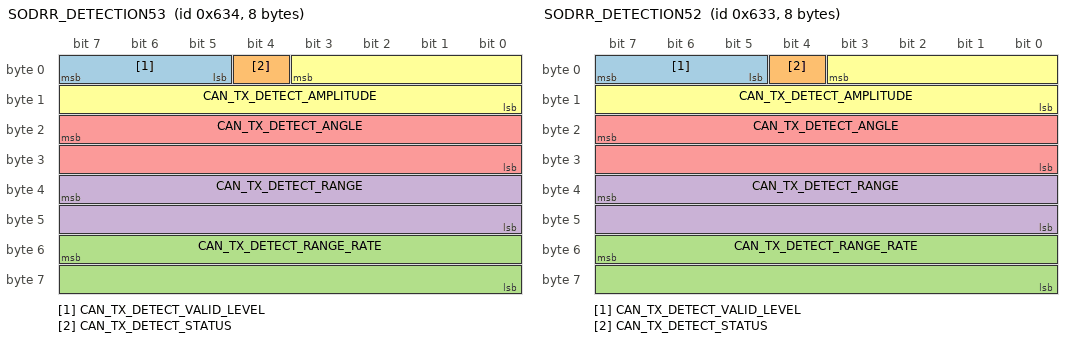
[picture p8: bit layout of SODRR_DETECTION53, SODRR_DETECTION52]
BO_ 1588 SODRR_DETECTION53: 8 SODRR
 SG_ CAN_TX_DETECT_VALID_LEVEL : 7|3@0+ (1,0) [0|0] "" Vector__XXX
 SG_ CAN_TX_DETECT_STATUS : 4|1@0+ (1,0) [0|1] "" Vector__XXX
 SG_ CAN_TX_DETECT_RANGE_RATE : 55|16@0- (0.0078125,0) [-81.92|81.91] "m/s" Vector__XXX
 SG_ CAN_TX_DETECT_RANGE : 39|16@0- (0.0078125,0) [0|204.7] "m" Vector__XXX
 SG_ CAN_TX_DETECT_ANGLE : 23|16@0- (0.0078125,0) [-102.4|102.2] "deg" Vector__XXX
 SG_ CAN_TX_DETECT_AMPLITUDE : 3|12@0- (0.125,0) [-24|40] "dBsm" Vector__XXX

BO_ 1587 SODRR_DETECTION52: 8 SODRR
 SG_ CAN_TX_DETECT_VALID_LEVEL : 7|3@0+ (1,0) [0|0] "" Vector__XXX
 SG_ CAN_TX_DETECT_STATUS : 4|1@0+ (1,0) [0|1] "" Vector__XXX
 SG_ CAN_TX_DETECT_RANGE_RATE : 55|16@0- (0.0078125,0) [-81.92|81.91] "m/s" Vector__XXX
 SG_ CAN_TX_DETECT_RANGE : 39|16@0- (0.0078125,0) [0|204.7] "m" Vector__XXX
 SG_ CAN_TX_DETECT_ANGLE : 23|16@0- (0.0078125,0) [-102.4|102.2] "deg" Vector__XXX
 SG_ CAN_TX_DETECT_AMPLITUDE : 3|12@0- (0.125,0) [-24|40] "dBsm" Vector__XXX

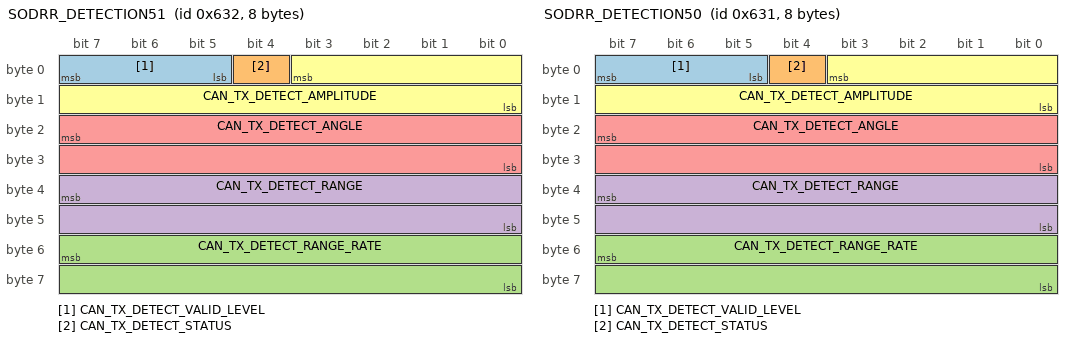
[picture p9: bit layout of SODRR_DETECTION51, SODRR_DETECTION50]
BO_ 1586 SODRR_DETECTION51: 8 SODRR
 SG_ CAN_TX_DETECT_VALID_LEVEL : 7|3@0+ (1,0) [0|0] "" Vector__XXX
 SG_ CAN_TX_DETECT_STATUS : 4|1@0+ (1,0) [0|1] "" Vector__XXX
 SG_ CAN_TX_DETECT_RANGE_RATE : 55|16@0- (0.0078125,0) [-81.92|81.91] "m/s" Vector__XXX
 SG_ CAN_TX_DETECT_RANGE : 39|16@0- (0.0078125,0) [0|204.7] "m" Vector__XXX
 SG_ CAN_TX_DETECT_ANGLE : 23|16@0- (0.0078125,0) [-102.4|102.2] "deg" Vector__XXX
 SG_ CAN_TX_DETECT_AMPLITUDE : 3|12@0- (0.125,0) [-24|40] "dBsm" Vector__XXX

BO_ 1585 SODRR_DETECTION50: 8 SODRR
 SG_ CAN_TX_DETECT_VALID_LEVEL : 7|3@0+ (1,0) [0|0] "" Vector__XXX
 SG_ CAN_TX_DETECT_STATUS : 4|1@0+ (1,0) [0|1] "" Vector__XXX
 SG_ CAN_TX_DETECT_RANGE_RATE : 55|16@0- (0.0078125,0) [-81.92|81.91] "m/s" Vector__XXX
 SG_ CAN_TX_DETECT_RANGE : 39|16@0- (0.0078125,0) [0|204.7] "m" Vector__XXX
 SG_ CAN_TX_DETECT_ANGLE : 23|16@0- (0.0078125,0) [-102.4|102.2] "deg" Vector__XXX
 SG_ CAN_TX_DETECT_AMPLITUDE : 3|12@0- (0.125,0) [-24|40] "dBsm" Vector__XXX

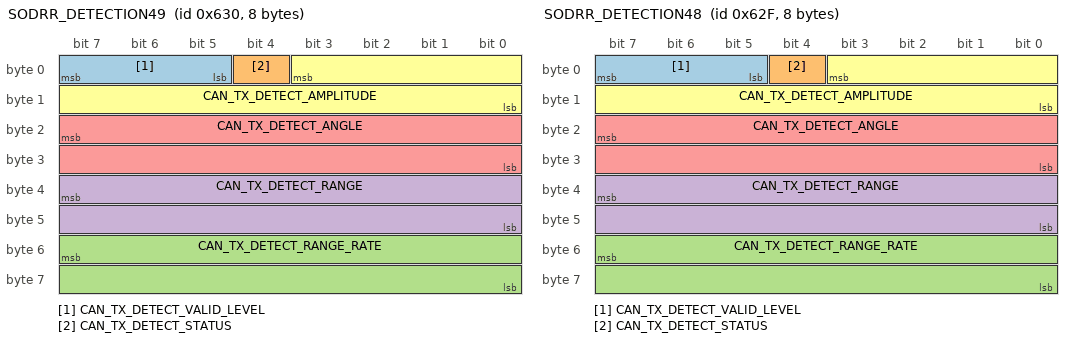
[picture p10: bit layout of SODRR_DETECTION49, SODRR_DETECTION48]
BO_ 1584 SODRR_DETECTION49: 8 SODRR
 SG_ CAN_TX_DETECT_VALID_LEVEL : 7|3@0+ (1,0) [0|0] "" Vector__XXX
 SG_ CAN_TX_DETECT_STATUS : 4|1@0+ (1,0) [0|1] "" Vector__XXX
 SG_ CAN_TX_DETECT_RANGE_RATE : 55|16@0- (0.0078125,0) [-81.92|81.91] "m/s" Vector__XXX
 SG_ CAN_TX_DETECT_RANGE : 39|16@0- (0.0078125,0) [0|204.7] "m" Vector__XXX
 SG_ CAN_TX_DETECT_ANGLE : 23|16@0- (0.0078125,0) [-102.4|102.2] "deg" Vector__XXX
 SG_ CAN_TX_DETECT_AMPLITUDE : 3|12@0- (0.125,0) [-24|40] "dBsm" Vector__XXX

BO_ 1583 SODRR_DETECTION48: 8 SODRR
 SG_ CAN_TX_DETECT_VALID_LEVEL : 7|3@0+ (1,0) [0|0] "" Vector__XXX
 SG_ CAN_TX_DETECT_STATUS : 4|1@0+ (1,0) [0|1] "" Vector__XXX
 SG_ CAN_TX_DETECT_RANGE_RATE : 55|16@0- (0.0078125,0) [-81.92|81.91] "m/s" Vector__XXX
 SG_ CAN_TX_DETECT_RANGE : 39|16@0- (0.0078125,0) [0|204.7] "m" Vector__XXX
 SG_ CAN_TX_DETECT_ANGLE : 23|16@0- (0.0078125,0) [-102.4|102.2] "deg" Vector__XXX
 SG_ CAN_TX_DETECT_AMPLITUDE : 3|12@0- (0.125,0) [-24|40] "dBsm" Vector__XXX

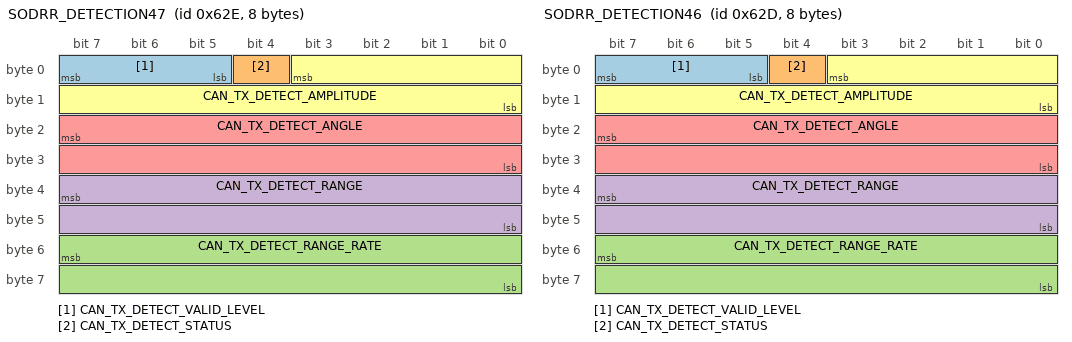
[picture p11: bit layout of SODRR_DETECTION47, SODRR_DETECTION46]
BO_ 1582 SODRR_DETECTION47: 8 SODRR
 SG_ CAN_TX_DETECT_VALID_LEVEL : 7|3@0+ (1,0) [0|0] "" Vector__XXX
 SG_ CAN_TX_DETECT_STATUS : 4|1@0+ (1,0) [0|1] "" Vector__XXX
 SG_ CAN_TX_DETECT_RANGE_RATE : 55|16@0- (0.0078125,0) [-81.92|81.91] "m/s" Vector__XXX
 SG_ CAN_TX_DETECT_RANGE : 39|16@0- (0.0078125,0) [0|204.7] "m" Vector__XXX
 SG_ CAN_TX_DETECT_ANGLE : 23|16@0- (0.0078125,0) [-102.4|102.2] "deg" Vector__XXX
 SG_ CAN_TX_DETECT_AMPLITUDE : 3|12@0- (0.125,0) [-24|40] "dBsm" Vector__XXX

BO_ 1581 SODRR_DETECTION46: 8 SODRR
 SG_ CAN_TX_DETECT_VALID_LEVEL : 7|3@0+ (1,0) [0|0] "" Vector__XXX
 SG_ CAN_TX_DETECT_STATUS : 4|1@0+ (1,0) [0|1] "" Vector__XXX
 SG_ CAN_TX_DETECT_RANGE_RATE : 55|16@0- (0.0078125,0) [-81.92|81.91] "m/s" Vector__XXX
 SG_ CAN_TX_DETECT_RANGE : 39|16@0- (0.0078125,0) [0|204.7] "m" Vector__XXX
 SG_ CAN_TX_DETECT_ANGLE : 23|16@0- (0.0078125,0) [-102.4|102.2] "deg" Vector__XXX
 SG_ CAN_TX_DETECT_AMPLITUDE : 3|12@0- (0.125,0) [-24|40] "dBsm" Vector__XXX

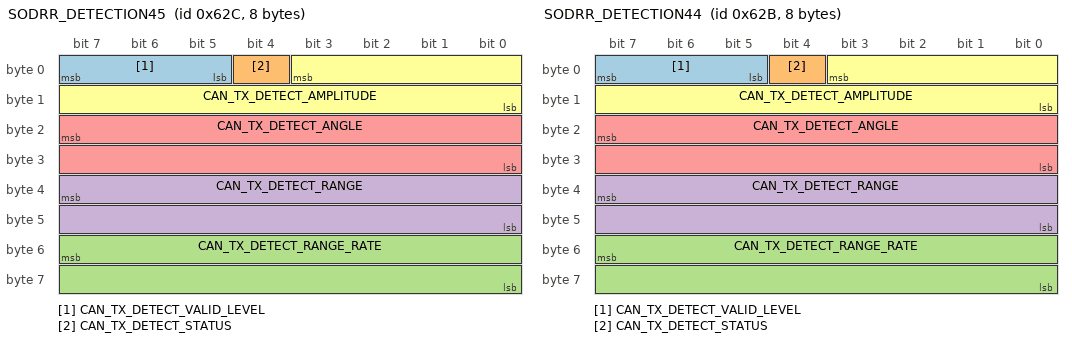
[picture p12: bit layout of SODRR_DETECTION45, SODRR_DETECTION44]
BO_ 1580 SODRR_DETECTION45: 8 SODRR
 SG_ CAN_TX_DETECT_VALID_LEVEL : 7|3@0+ (1,0) [0|0] "" Vector__XXX
 SG_ CAN_TX_DETECT_STATUS : 4|1@0+ (1,0) [0|1] "" Vector__XXX
 SG_ CAN_TX_DETECT_RANGE_RATE : 55|16@0- (0.0078125,0) [-81.92|81.91] "m/s" Vector__XXX
 SG_ CAN_TX_DETECT_RANGE : 39|16@0- (0.0078125,0) [0|204.7] "m" Vector__XXX
 SG_ CAN_TX_DETECT_ANGLE : 23|16@0- (0.0078125,0) [-102.4|102.2] "deg" Vector__XXX
 SG_ CAN_TX_DETECT_AMPLITUDE : 3|12@0- (0.125,0) [-24|40] "dBsm" Vector__XXX

BO_ 1579 SODRR_DETECTION44: 8 SODRR
 SG_ CAN_TX_DETECT_VALID_LEVEL : 7|3@0+ (1,0) [0|0] "" Vector__XXX
 SG_ CAN_TX_DETECT_STATUS : 4|1@0+ (1,0) [0|1] "" Vector__XXX
 SG_ CAN_TX_DETECT_RANGE_RATE : 55|16@0- (0.0078125,0) [-81.92|81.91] "m/s" Vector__XXX
 SG_ CAN_TX_DETECT_RANGE : 39|16@0- (0.0078125,0) [0|204.7] "m" Vector__XXX
 SG_ CAN_TX_DETECT_ANGLE : 23|16@0- (0.0078125,0) [-102.4|102.2] "deg" Vector__XXX
 SG_ CAN_TX_DETECT_AMPLITUDE : 3|12@0- (0.125,0) [-24|40] "dBsm" Vector__XXX

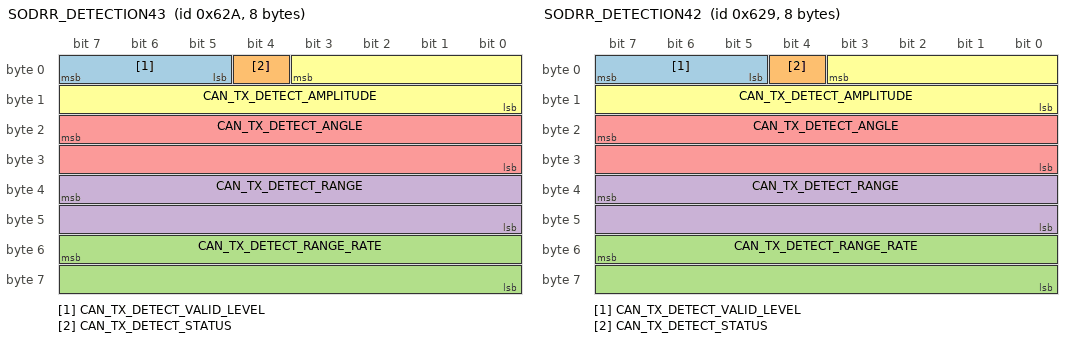
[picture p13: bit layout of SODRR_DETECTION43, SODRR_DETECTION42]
BO_ 1578 SODRR_DETECTION43: 8 SODRR
 SG_ CAN_TX_DETECT_VALID_LEVEL : 7|3@0+ (1,0) [0|0] "" Vector__XXX
 SG_ CAN_TX_DETECT_STATUS : 4|1@0+ (1,0) [0|1] "" Vector__XXX
 SG_ CAN_TX_DETECT_RANGE_RATE : 55|16@0- (0.0078125,0) [-81.92|81.91] "m/s" Vector__XXX
 SG_ CAN_TX_DETECT_RANGE : 39|16@0- (0.0078125,0) [0|204.7] "m" Vector__XXX
 SG_ CAN_TX_DETECT_ANGLE : 23|16@0- (0.0078125,0) [-102.4|102.2] "deg" Vector__XXX
 SG_ CAN_TX_DETECT_AMPLITUDE : 3|12@0- (0.125,0) [-24|40] "dBsm" Vector__XXX

BO_ 1577 SODRR_DETECTION42: 8 SODRR
 SG_ CAN_TX_DETECT_VALID_LEVEL : 7|3@0+ (1,0) [0|0] "" Vector__XXX
 SG_ CAN_TX_DETECT_STATUS : 4|1@0+ (1,0) [0|1] "" Vector__XXX
 SG_ CAN_TX_DETECT_RANGE_RATE : 55|16@0- (0.0078125,0) [-81.92|81.91] "m/s" Vector__XXX
 SG_ CAN_TX_DETECT_RANGE : 39|16@0- (0.0078125,0) [0|204.7] "m" Vector__XXX
 SG_ CAN_TX_DETECT_ANGLE : 23|16@0- (0.0078125,0) [-102.4|102.2] "deg" Vector__XXX
 SG_ CAN_TX_DETECT_AMPLITUDE : 3|12@0- (0.125,0) [-24|40] "dBsm" Vector__XXX

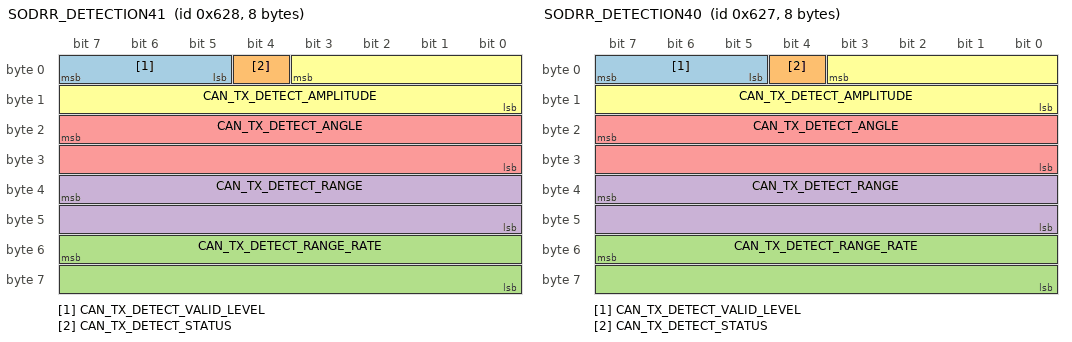
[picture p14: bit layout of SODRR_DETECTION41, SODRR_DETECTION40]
BO_ 1576 SODRR_DETECTION41: 8 SODRR
 SG_ CAN_TX_DETECT_VALID_LEVEL : 7|3@0+ (1,0) [0|0] "" Vector__XXX
 SG_ CAN_TX_DETECT_STATUS : 4|1@0+ (1,0) [0|1] "" Vector__XXX
 SG_ CAN_TX_DETECT_RANGE_RATE : 55|16@0- (0.0078125,0) [-81.92|81.91] "m/s" Vector__XXX
 SG_ CAN_TX_DETECT_RANGE : 39|16@0- (0.0078125,0) [0|204.7] "m" Vector__XXX
 SG_ CAN_TX_DETECT_ANGLE : 23|16@0- (0.0078125,0) [-102.4|102.2] "deg" Vector__XXX
 SG_ CAN_TX_DETECT_AMPLITUDE : 3|12@0- (0.125,0) [-24|40] "dBsm" Vector__XXX

BO_ 1575 SODRR_DETECTION40: 8 SODRR
 SG_ CAN_TX_DETECT_VALID_LEVEL : 7|3@0+ (1,0) [0|0] "" Vector__XXX
 SG_ CAN_TX_DETECT_STATUS : 4|1@0+ (1,0) [0|1] "" Vector__XXX
 SG_ CAN_TX_DETECT_RANGE_RATE : 55|16@0- (0.0078125,0) [-81.92|81.91] "m/s" Vector__XXX
 SG_ CAN_TX_DETECT_RANGE : 39|16@0- (0.0078125,0) [0|204.7] "m" Vector__XXX
 SG_ CAN_TX_DETECT_ANGLE : 23|16@0- (0.0078125,0) [-102.4|102.2] "deg" Vector__XXX
 SG_ CAN_TX_DETECT_AMPLITUDE : 3|12@0- (0.125,0) [-24|40] "dBsm" Vector__XXX

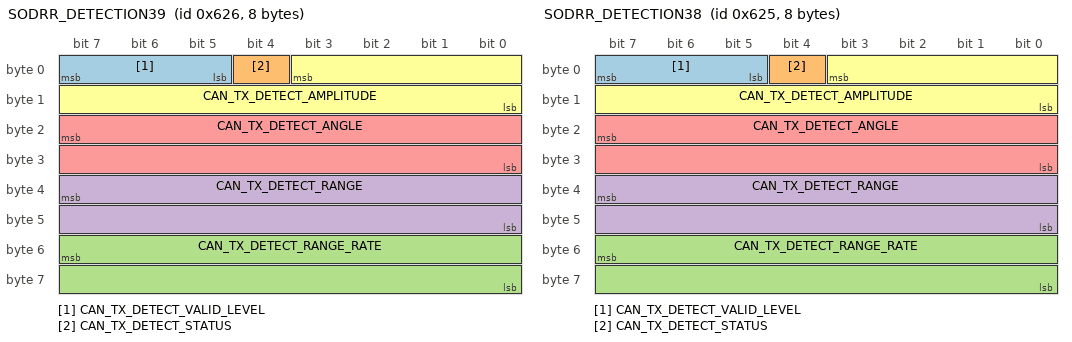
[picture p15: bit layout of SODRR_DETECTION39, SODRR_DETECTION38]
BO_ 1574 SODRR_DETECTION39: 8 SODRR
 SG_ CAN_TX_DETECT_VALID_LEVEL : 7|3@0+ (1,0) [0|0] "" Vector__XXX
 SG_ CAN_TX_DETECT_STATUS : 4|1@0+ (1,0) [0|1] "" Vector__XXX
 SG_ CAN_TX_DETECT_RANGE_RATE : 55|16@0- (0.0078125,0) [-81.92|81.91] "m/s" Vector__XXX
 SG_ CAN_TX_DETECT_RANGE : 39|16@0- (0.0078125,0) [0|204.7] "m" Vector__XXX
 SG_ CAN_TX_DETECT_ANGLE : 23|16@0- (0.0078125,0) [-102.4|102.2] "deg" Vector__XXX
 SG_ CAN_TX_DETECT_AMPLITUDE : 3|12@0- (0.125,0) [-24|40] "dBsm" Vector__XXX

BO_ 1573 SODRR_DETECTION38: 8 SODRR
 SG_ CAN_TX_DETECT_VALID_LEVEL : 7|3@0+ (1,0) [0|0] "" Vector__XXX
 SG_ CAN_TX_DETECT_STATUS : 4|1@0+ (1,0) [0|1] "" Vector__XXX
 SG_ CAN_TX_DETECT_RANGE_RATE : 55|16@0- (0.0078125,0) [-81.92|81.91] "m/s" Vector__XXX
 SG_ CAN_TX_DETECT_RANGE : 39|16@0- (0.0078125,0) [0|204.7] "m" Vector__XXX
 SG_ CAN_TX_DETECT_ANGLE : 23|16@0- (0.0078125,0) [-102.4|102.2] "deg" Vector__XXX
 SG_ CAN_TX_DETECT_AMPLITUDE : 3|12@0- (0.125,0) [-24|40] "dBsm" Vector__XXX

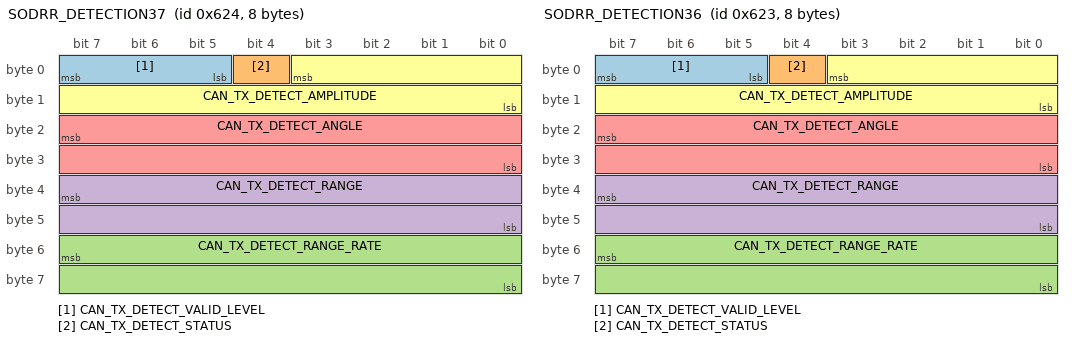
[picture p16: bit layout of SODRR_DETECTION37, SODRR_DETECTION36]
BO_ 1572 SODRR_DETECTION37: 8 SODRR
 SG_ CAN_TX_DETECT_VALID_LEVEL : 7|3@0+ (1,0) [0|0] "" Vector__XXX
 SG_ CAN_TX_DETECT_STATUS : 4|1@0+ (1,0) [0|1] "" Vector__XXX
 SG_ CAN_TX_DETECT_RANGE_RATE : 55|16@0- (0.0078125,0) [-81.92|81.91] "m/s" Vector__XXX
 SG_ CAN_TX_DETECT_RANGE : 39|16@0- (0.0078125,0) [0|204.7] "m" Vector__XXX
 SG_ CAN_TX_DETECT_ANGLE : 23|16@0- (0.0078125,0) [-102.4|102.2] "deg" Vector__XXX
 SG_ CAN_TX_DETECT_AMPLITUDE : 3|12@0- (0.125,0) [-24|40] "dBsm" Vector__XXX

BO_ 1571 SODRR_DETECTION36: 8 SODRR
 SG_ CAN_TX_DETECT_VALID_LEVEL : 7|3@0+ (1,0) [0|0] "" Vector__XXX
 SG_ CAN_TX_DETECT_STATUS : 4|1@0+ (1,0) [0|1] "" Vector__XXX
 SG_ CAN_TX_DETECT_RANGE_RATE : 55|16@0- (0.0078125,0) [-81.92|81.91] "m/s" Vector__XXX
 SG_ CAN_TX_DETECT_RANGE : 39|16@0- (0.0078125,0) [0|204.7] "m" Vector__XXX
 SG_ CAN_TX_DETECT_ANGLE : 23|16@0- (0.0078125,0) [-102.4|102.2] "deg" Vector__XXX
 SG_ CAN_TX_DETECT_AMPLITUDE : 3|12@0- (0.125,0) [-24|40] "dBsm" Vector__XXX

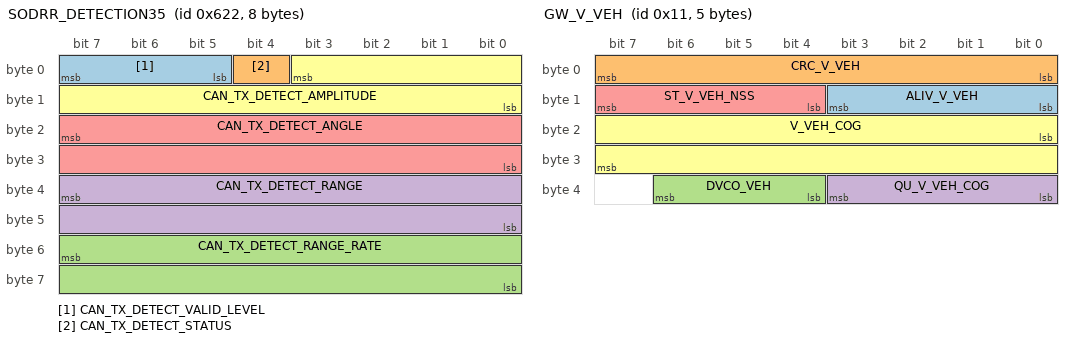
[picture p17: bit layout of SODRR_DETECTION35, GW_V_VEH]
BO_ 1570 SODRR_DETECTION35: 8 SODRR
 SG_ CAN_TX_DETECT_VALID_LEVEL : 7|3@0+ (1,0) [0|0] "" Vector__XXX
 SG_ CAN_TX_DETECT_STATUS : 4|1@0+ (1,0) [0|1] "" Vector__XXX
 SG_ CAN_TX_DETECT_RANGE_RATE : 55|16@0- (0.0078125,0) [-81.92|81.91] "m/s" Vector__XXX
 SG_ CAN_TX_DETECT_RANGE : 39|16@0- (0.0078125,0) [0|204.7] "m" Vector__XXX
 SG_ CAN_TX_DETECT_ANGLE : 23|16@0- (0.0078125,0) [-102.4|102.2] "deg" Vector__XXX
 SG_ CAN_TX_DETECT_AMPLITUDE : 3|12@0- (0.125,0) [-24|40] "dBsm" Vector__XXX

BO_ 1569 SODRR_DETECTION34: 8 SODRR
 SG_ CAN_TX_DETECT_VALID_LEVEL : 7|3@0+ (1,0) [0|0] "" Vector__XXX
 SG_ CAN_TX_DETECT_STATUS : 4|1@0+ (1,0) [0|1] "" Vector__XXX
 SG_ CAN_TX_DETECT_RANGE_RATE : 55|16@0- (0.0078125,0) [-81.92|81.91] "m/s" Vector__XXX
 SG_ CAN_TX_DETECT_RANGE : 39|16@0- (0.0078125,0) [0|204.7] "m" Vector__XXX
 SG_ CAN_TX_DETECT_ANGLE : 23|16@0- (0.0078125,0) [-102.4|102.2] "deg" Vector__XXX
 SG_ CAN_TX_DETECT_AMPLITUDE : 3|12@0- (0.125,0) [-24|40] "dBsm" Vector__XXX

BO_ 1568 SODRR_DETECTION33: 8 SODRR
 SG_ CAN_TX_DETECT_VALID_LEVEL : 7|3@0+ (1,0) [0|0] "" Vector__XXX
 SG_ CAN_TX_DETECT_STATUS : 4|1@0+ (1,0) [0|1] "" Vector__XXX
 SG_ CAN_TX_DETECT_RANGE_RATE : 55|16@0- (0.0078125,0) [-81.92|81.91] "m/s" Vector__XXX
 SG_ CAN_TX_DETECT_RANGE : 39|16@0- (0.0078125,0) [0|204.7] "m" Vector__XXX
 SG_ CAN_TX_DETECT_ANGLE : 23|16@0- (0.0078125,0) [-102.4|102.2] "deg" Vector__XXX
 SG_ CAN_TX_DETECT_AMPLITUDE : 3|12@0- (0.125,0) [-24|40] "dBsm" Vector__XXX

BO_ 1567 SODRR_DETECTION32: 8 SODRR
 SG_ CAN_TX_DETECT_VALID_LEVEL : 7|3@0+ (1,0) [0|0] "" Vector__XXX
 SG_ CAN_TX_DETECT_STATUS : 4|1@0+ (1,0) [0|1] "" Vector__XXX
 SG_ CAN_TX_DETECT_RANGE_RATE : 55|16@0- (0.0078125,0) [-81.92|81.91] "m/s" Vector__XXX
 SG_ CAN_TX_DETECT_RANGE : 39|16@0- (0.0078125,0) [0|204.7] "m" Vector__XXX
 SG_ CAN_TX_DETECT_ANGLE : 23|16@0- (0.0078125,0) [-102.4|102.2] "deg" Vector__XXX
 SG_ CAN_TX_DETECT_AMPLITUDE : 3|12@0- (0.125,0) [-24|40] "dBsm" Vector__XXX

BO_ 1566 SODRR_DETECTION31: 8 SODRR
 SG_ CAN_TX_DETECT_STATUS : 4|1@0+ (1,0) [0|1] "" Vector__XXX
 SG_ CAN_TX_DETECT_RANGE_RATE : 55|16@0- (0.0078125,0) [-81.92|81.91] "m/s" Vector__XXX
 SG_ CAN_TX_DETECT_RANGE : 39|16@0- (0.0078125,0) [0|204.7] "m" Vector__XXX
 SG_ CAN_TX_DETECT_ANGLE : 23|16@0- (0.0078125,0) [-102.4|102.2] "deg" Vector__XXX
 SG_ CAN_TX_DETECT_AMPLITUDE : 3|12@0- (0.125,0) [-24|40] "dBsm" Vector__XXX
 SG_ CAN_TX_DETECT_VALID_LEVEL : 7|3@0+ (1,0) [0|0] "" Vector__XXX

BO_ 1565 SODRR_DETECTION30: 8 SODRR
 SG_ CAN_TX_DETECT_VALID_LEVEL : 7|3@0+ (1,0) [0|0] "" Vector__XXX
 SG_ CAN_TX_DETECT_STATUS : 4|1@0+ (1,0) [0|1] "" Vector__XXX
 SG_ CAN_TX_DETECT_RANGE_RATE : 55|16@0- (0.0078125,0) [-81.92|81.91] "m/s" Vector__XXX
 SG_ CAN_TX_DETECT_RANGE : 39|16@0- (0.0078125,0) [0|204.7] "m" Vector__XXX
 SG_ CAN_TX_DETECT_ANGLE : 23|16@0- (0.0078125,0) [-102.4|102.2] "deg" Vector__XXX
 SG_ CAN_TX_DETECT_AMPLITUDE : 3|12@0- (0.125,0) [-24|40] "dBsm" Vector__XXX

BO_ 1564 SODRR_DETECTION29: 8 SODRR
 SG_ CAN_TX_DETECT_VALID_LEVEL : 7|3@0+ (1,0) [0|0] "" Vector__XXX
 SG_ CAN_TX_DETECT_STATUS : 4|1@0+ (1,0) [0|1] "" Vector__XXX
 SG_ CAN_TX_DETECT_RANGE_RATE : 55|16@0- (0.0078125,0) [-81.92|81.91] "m/s" Vector__XXX
 SG_ CAN_TX_DETECT_RANGE : 39|16@0- (0.0078125,0) [0|204.7] "m" Vector__XXX
 SG_ CAN_TX_DETECT_ANGLE : 23|16@0- (0.0078125,0) [-102.4|102.2] "deg" Vector__XXX
 SG_ CAN_TX_DETECT_AMPLITUDE : 3|12@0- (0.125,0) [-24|40] "dBsm" Vector__XXX

BO_ 1563 SODRR_DETECTION28: 8 SODRR
 SG_ CAN_TX_DETECT_VALID_LEVEL : 7|3@0+ (1,0) [0|0] "" Vector__XXX
 SG_ CAN_TX_DETECT_STATUS : 4|1@0+ (1,0) [0|1] "" Vector__XXX
 SG_ CAN_TX_DETECT_RANGE_RATE : 55|16@0- (0.0078125,0) [-81.92|81.91] "m/s" Vector__XXX
 SG_ CAN_TX_DETECT_RANGE : 39|16@0- (0.0078125,0) [0|204.7] "m" Vector__XXX
 SG_ CAN_TX_DETECT_ANGLE : 23|16@0- (0.0078125,0) [-102.4|102.2] "deg" Vector__XXX
 SG_ CAN_TX_DETECT_AMPLITUDE : 3|12@0- (0.125,0) [-24|40] "dBsm" Vector__XXX

BO_ 1562 SODRR_DETECTION27: 8 SODRR
 SG_ CAN_TX_DETECT_VALID_LEVEL : 7|3@0+ (1,0) [0|0] "" Vector__XXX
 SG_ CAN_TX_DETECT_STATUS : 4|1@0+ (1,0) [0|1] "" Vector__XXX
 SG_ CAN_TX_DETECT_RANGE_RATE : 55|16@0- (0.0078125,0) [-81.92|81.91] "m/s" Vector__XXX
 SG_ CAN_TX_DETECT_RANGE : 39|16@0- (0.0078125,0) [0|204.7] "m" Vector__XXX
 SG_ CAN_TX_DETECT_ANGLE : 23|16@0- (0.0078125,0) [-102.4|102.2] "deg" Vector__XXX
 SG_ CAN_TX_DETECT_AMPLITUDE : 3|12@0- (0.125,0) [-24|40] "dBsm" Vector__XXX

BO_ 1561 SODRR_DETECTION26: 8 SODRR
 SG_ CAN_TX_DETECT_VALID_LEVEL : 7|3@0+ (1,0) [0|0] "" Vector__XXX
 SG_ CAN_TX_DETECT_STATUS : 4|1@0+ (1,0) [0|1] "" Vector__XXX
 SG_ CAN_TX_DETECT_RANGE_RATE : 55|16@0- (0.0078125,0) [-81.92|81.91] "m/s" Vector__XXX
 SG_ CAN_TX_DETECT_RANGE : 39|16@0- (0.0078125,0) [0|204.7] "m" Vector__XXX
 SG_ CAN_TX_DETECT_ANGLE : 23|16@0- (0.0078125,0) [-102.4|102.2] "deg" Vector__XXX
 SG_ CAN_TX_DETECT_AMPLITUDE : 3|12@0- (0.125,0) [-24|40] "dBsm" Vector__XXX

BO_ 1560 SODRR_DETECTION25: 8 SODRR
 SG_ CAN_TX_DETECT_VALID_LEVEL : 7|3@0+ (1,0) [0|0] "" Vector__XXX
 SG_ CAN_TX_DETECT_STATUS : 4|1@0+ (1,0) [0|1] "" Vector__XXX
 SG_ CAN_TX_DETECT_RANGE_RATE : 55|16@0- (0.0078125,0) [-81.92|81.91] "m/s" Vector__XXX
 SG_ CAN_TX_DETECT_RANGE : 39|16@0- (0.0078125,0) [0|204.7] "m" Vector__XXX
 SG_ CAN_TX_DETECT_ANGLE : 23|16@0- (0.0078125,0) [-102.4|102.2] "deg" Vector__XXX
 SG_ CAN_TX_DETECT_AMPLITUDE : 3|12@0- (0.125,0) [-24|40] "dBsm" Vector__XXX

BO_ 1559 SODRR_DETECTION24: 8 SODRR
 SG_ CAN_TX_DETECT_VALID_LEVEL : 7|3@0+ (1,0) [0|0] "" Vector__XXX
 SG_ CAN_TX_DETECT_STATUS : 4|1@0+ (1,0) [0|1] "" Vector__XXX
 SG_ CAN_TX_DETECT_RANGE_RATE : 55|16@0- (0.0078125,0) [-81.92|81.91] "m/s" Vector__XXX
 SG_ CAN_TX_DETECT_RANGE : 39|16@0- (0.0078125,0) [0|204.7] "m" Vector__XXX
 SG_ CAN_TX_DETECT_ANGLE : 23|16@0- (0.0078125,0) [-102.4|102.2] "deg" Vector__XXX
 SG_ CAN_TX_DETECT_AMPLITUDE : 3|12@0- (0.125,0) [-24|40] "dBsm" Vector__XXX

BO_ 1558 SODRR_DETECTION23: 8 SODRR
 SG_ CAN_TX_DETECT_VALID_LEVEL : 7|3@0+ (1,0) [0|0] "" Vector__XXX
 SG_ CAN_TX_DETECT_STATUS : 4|1@0+ (1,0) [0|1] "" Vector__XXX
 SG_ CAN_TX_DETECT_RANGE_RATE : 55|16@0- (0.0078125,0) [-81.92|81.91] "m/s" Vector__XXX
 SG_ CAN_TX_DETECT_RANGE : 39|16@0- (0.0078125,0) [0|204.7] "m" Vector__XXX
 SG_ CAN_TX_DETECT_ANGLE : 23|16@0- (0.0078125,0) [-102.4|102.2] "deg" Vector__XXX
 SG_ CAN_TX_DETECT_AMPLITUDE : 3|12@0- (0.125,0) [-24|40] "dBsm" Vector__XXX

BO_ 1557 SODRR_DETECTION22: 8 SODRR
 SG_ CAN_TX_DETECT_VALID_LEVEL : 7|3@0+ (1,0) [0|0] "" Vector__XXX
 SG_ CAN_TX_DETECT_STATUS : 4|1@0+ (1,0) [0|1] "" Vector__XXX
 SG_ CAN_TX_DETECT_RANGE_RATE : 55|16@0- (0.0078125,0) [-81.92|81.91] "m/s" Vector__XXX
 SG_ CAN_TX_DETECT_RANGE : 39|16@0- (0.0078125,0) [0|204.7] "m" Vector__XXX
 SG_ CAN_TX_DETECT_ANGLE : 23|16@0- (0.0078125,0) [-102.4|102.2] "deg" Vector__XXX
 SG_ CAN_TX_DETECT_AMPLITUDE : 3|12@0- (0.125,0) [-24|40] "dBsm" Vector__XXX

BO_ 1556 SODRR_DETECTION21: 8 SODRR
 SG_ CAN_TX_DETECT_VALID_LEVEL : 7|3@0+ (1,0) [0|0] "" Vector__XXX
 SG_ CAN_TX_DETECT_STATUS : 4|1@0+ (1,0) [0|1] "" Vector__XXX
 SG_ CAN_TX_DETECT_RANGE_RATE : 55|16@0- (0.0078125,0) [-81.92|81.91] "m/s" Vector__XXX
 SG_ CAN_TX_DETECT_RANGE : 39|16@0- (0.0078125,0) [0|204.7] "m" Vector__XXX
 SG_ CAN_TX_DETECT_ANGLE : 23|16@0- (0.0078125,0) [-102.4|102.2] "deg" Vector__XXX
 SG_ CAN_TX_DETECT_AMPLITUDE : 3|12@0- (0.125,0) [-24|40] "dBsm" Vector__XXX

BO_ 1555 SODRR_DETECTION20: 8 SODRR
 SG_ CAN_TX_DETECT_VALID_LEVEL : 7|3@0+ (1,0) [0|0] "" Vector__XXX
 SG_ CAN_TX_DETECT_STATUS : 4|1@0+ (1,0) [0|1] "" Vector__XXX
 SG_ CAN_TX_DETECT_RANGE_RATE : 55|16@0- (0.0078125,0) [-81.92|81.91] "m/s" Vector__XXX
 SG_ CAN_TX_DETECT_RANGE : 39|16@0- (0.0078125,0) [0|204.7] "m" Vector__XXX
 SG_ CAN_TX_DETECT_ANGLE : 23|16@0- (0.0078125,0) [-102.4|102.2] "deg" Vector__XXX
 SG_ CAN_TX_DETECT_AMPLITUDE : 3|12@0- (0.125,0) [-24|40] "dBsm" Vector__XXX

BO_ 1554 SODRR_DETECTION19: 8 SODRR
 SG_ CAN_TX_DETECT_VALID_LEVEL : 7|3@0+ (1,0) [0|0] "" Vector__XXX
 SG_ CAN_TX_DETECT_STATUS : 4|1@0+ (1,0) [0|1] "" Vector__XXX
 SG_ CAN_TX_DETECT_RANGE_RATE : 55|16@0- (0.0078125,0) [-81.92|81.91] "m/s" Vector__XXX
 SG_ CAN_TX_DETECT_RANGE : 39|16@0- (0.0078125,0) [0|204.7] "m" Vector__XXX
 SG_ CAN_TX_DETECT_ANGLE : 23|16@0- (0.0078125,0) [-102.4|102.2] "deg" Vector__XXX
 SG_ CAN_TX_DETECT_AMPLITUDE : 3|12@0- (0.125,0) [-24|40] "dBsm" Vector__XXX

BO_ 1553 SODRR_DETECTION18: 8 SODRR
 SG_ CAN_TX_DETECT_VALID_LEVEL : 7|3@0+ (1,0) [0|0] "" Vector__XXX
 SG_ CAN_TX_DETECT_STATUS : 4|1@0+ (1,0) [0|1] "" Vector__XXX
 SG_ CAN_TX_DETECT_RANGE_RATE : 55|16@0- (0.0078125,0) [-81.92|81.91] "m/s" Vector__XXX
 SG_ CAN_TX_DETECT_RANGE : 39|16@0- (0.0078125,0) [0|204.7] "m" Vector__XXX
 SG_ CAN_TX_DETECT_ANGLE : 23|16@0- (0.0078125,0) [-102.4|102.2] "deg" Vector__XXX
 SG_ CAN_TX_DETECT_AMPLITUDE : 3|12@0- (0.125,0) [-24|40] "dBsm" Vector__XXX

BO_ 1552 SODRR_DETECTION17: 8 SODRR
 SG_ CAN_TX_DETECT_VALID_LEVEL : 7|3@0+ (1,0) [0|0] "" Vector__XXX
 SG_ CAN_TX_DETECT_STATUS : 4|1@0+ (1,0) [0|1] "" Vector__XXX
 SG_ CAN_TX_DETECT_RANGE_RATE : 55|16@0- (0.0078125,0) [-81.92|81.91] "m/s" Vector__XXX
 SG_ CAN_TX_DETECT_RANGE : 39|16@0- (0.0078125,0) [0|204.7] "m" Vector__XXX
 SG_ CAN_TX_DETECT_ANGLE : 23|16@0- (0.0078125,0) [-102.4|102.2] "deg" Vector__XXX
 SG_ CAN_TX_DETECT_AMPLITUDE : 3|12@0- (0.125,0) [-24|40] "dBsm" Vector__XXX

BO_ 1551 SODRR_DETECTION16: 8 SODRR
 SG_ CAN_TX_DETECT_VALID_LEVEL : 7|3@0+ (1,0) [0|0] "" Vector__XXX
 SG_ CAN_TX_DETECT_STATUS : 4|1@0+ (1,0) [0|1] "" Vector__XXX
 SG_ CAN_TX_DETECT_RANGE_RATE : 55|16@0- (0.0078125,0) [-81.92|81.91] "m/s" Vector__XXX
 SG_ CAN_TX_DETECT_RANGE : 39|16@0- (0.0078125,0) [0|204.7] "m" Vector__XXX
 SG_ CAN_TX_DETECT_ANGLE : 23|16@0- (0.0078125,0) [-102.4|102.2] "deg" Vector__XXX
 SG_ CAN_TX_DETECT_AMPLITUDE : 3|12@0- (0.125,0) [-24|40] "dBsm" Vector__XXX

BO_ 1550 SODRR_DETECTION15: 8 SODRR
 SG_ CAN_TX_DETECT_VALID_LEVEL : 7|3@0+ (1,0) [0|0] "" Vector__XXX
 SG_ CAN_TX_DETECT_STATUS : 4|1@0+ (1,0) [0|1] "" Vector__XXX
 SG_ CAN_TX_DETECT_RANGE_RATE : 55|16@0- (0.0078125,0) [-81.92|81.91] "m/s" Vector__XXX
 SG_ CAN_TX_DETECT_RANGE : 39|16@0- (0.0078125,0) [0|204.7] "m" Vector__XXX
 SG_ CAN_TX_DETECT_ANGLE : 23|16@0- (0.0078125,0) [-102.4|102.2] "deg" Vector__XXX
 SG_ CAN_TX_DETECT_AMPLITUDE : 3|12@0- (0.125,0) [-24|40] "dBsm" Vector__XXX

BO_ 1549 SODRR_DETECTION14: 8 SODRR
 SG_ CAN_TX_DETECT_VALID_LEVEL : 7|3@0+ (1,0) [0|0] "" Vector__XXX
 SG_ CAN_TX_DETECT_STATUS : 4|1@0+ (1,0) [0|1] "" Vector__XXX
 SG_ CAN_TX_DETECT_RANGE_RATE : 55|16@0- (0.0078125,0) [-81.92|81.91] "m/s" Vector__XXX
 SG_ CAN_TX_DETECT_RANGE : 39|16@0- (0.0078125,0) [0|204.7] "m" Vector__XXX
 SG_ CAN_TX_DETECT_ANGLE : 23|16@0- (0.0078125,0) [-102.4|102.2] "deg" Vector__XXX
 SG_ CAN_TX_DETECT_AMPLITUDE : 3|12@0- (0.125,0) [-24|40] "dBsm" Vector__XXX

BO_ 1548 SODRR_DETECTION13: 8 SODRR
 SG_ CAN_TX_DETECT_VALID_LEVEL : 7|3@0+ (1,0) [0|0] "" Vector__XXX
 SG_ CAN_TX_DETECT_STATUS : 4|1@0+ (1,0) [0|1] "" Vector__XXX
 SG_ CAN_TX_DETECT_RANGE_RATE : 55|16@0- (0.0078125,0) [-81.92|81.91] "m/s" Vector__XXX
 SG_ CAN_TX_DETECT_RANGE : 39|16@0- (0.0078125,0) [0|204.7] "m" Vector__XXX
 SG_ CAN_TX_DETECT_ANGLE : 23|16@0- (0.0078125,0) [-102.4|102.2] "deg" Vector__XXX
 SG_ CAN_TX_DETECT_AMPLITUDE : 3|12@0- (0.125,0) [-24|40] "dBsm" Vector__XXX

BO_ 1547 SODRR_DETECTION12: 8 SODRR
 SG_ CAN_TX_DETECT_VALID_LEVEL : 7|3@0+ (1,0) [0|0] "" Vector__XXX
 SG_ CAN_TX_DETECT_STATUS : 4|1@0+ (1,0) [0|1] "" Vector__XXX
 SG_ CAN_TX_DETECT_RANGE_RATE : 55|16@0- (0.0078125,0) [-81.92|81.91] "m/s" Vector__XXX
 SG_ CAN_TX_DETECT_RANGE : 39|16@0- (0.0078125,0) [0|204.7] "m" Vector__XXX
 SG_ CAN_TX_DETECT_ANGLE : 23|16@0- (0.0078125,0) [-102.4|102.2] "deg" Vector__XXX
 SG_ CAN_TX_DETECT_AMPLITUDE : 3|12@0- (0.125,0) [-24|40] "dBsm" Vector__XXX

BO_ 1546 SODRR_DETECTION11: 8 SODRR
 SG_ CAN_TX_DETECT_VALID_LEVEL : 7|3@0+ (1,0) [0|0] "" Vector__XXX
 SG_ CAN_TX_DETECT_STATUS : 4|1@0+ (1,0) [0|1] "" Vector__XXX
 SG_ CAN_TX_DETECT_RANGE_RATE : 55|16@0- (0.0078125,0) [-81.92|81.91] "m/s" Vector__XXX
 SG_ CAN_TX_DETECT_RANGE : 39|16@0- (0.0078125,0) [0|204.7] "m" Vector__XXX
 SG_ CAN_TX_DETECT_ANGLE : 23|16@0- (0.0078125,0) [-102.4|102.2] "deg" Vector__XXX
 SG_ CAN_TX_DETECT_AMPLITUDE : 3|12@0- (0.125,0) [-24|40] "dBsm" Vector__XXX

BO_ 1545 SODRR_DETECTION10: 8 SODRR
 SG_ CAN_TX_DETECT_VALID_LEVEL : 7|3@0+ (1,0) [0|0] "" Vector__XXX
 SG_ CAN_TX_DETECT_STATUS : 4|1@0+ (1,0) [0|1] "" Vector__XXX
 SG_ CAN_TX_DETECT_RANGE_RATE : 55|16@0- (0.0078125,0) [-81.92|81.91] "m/s" Vector__XXX
 SG_ CAN_TX_DETECT_RANGE : 39|16@0- (0.0078125,0) [0|204.7] "m" Vector__XXX
 SG_ CAN_TX_DETECT_ANGLE : 23|16@0- (0.0078125,0) [-102.4|102.2] "deg" Vector__XXX
 SG_ CAN_TX_DETECT_AMPLITUDE : 3|12@0- (0.125,0) [-24|40] "dBsm" Vector__XXX

BO_ 1544 SODRR_DETECTION09: 8 SODRR
 SG_ CAN_TX_DETECT_VALID_LEVEL : 7|3@0+ (1,0) [0|0] "" Vector__XXX
 SG_ CAN_TX_DETECT_STATUS : 4|1@0+ (1,0) [0|1] "" Vector__XXX
 SG_ CAN_TX_DETECT_RANGE_RATE : 55|16@0- (0.0078125,0) [-81.92|81.91] "m/s" Vector__XXX
 SG_ CAN_TX_DETECT_RANGE : 39|16@0- (0.0078125,0) [0|204.7] "m" Vector__XXX
 SG_ CAN_TX_DETECT_ANGLE : 23|16@0- (0.0078125,0) [-102.4|102.2] "deg" Vector__XXX
 SG_ CAN_TX_DETECT_AMPLITUDE : 3|12@0- (0.125,0) [-24|40] "dBsm" Vector__XXX

BO_ 1543 SODRR_DETECTION08: 8 SODRR
 SG_ CAN_TX_DETECT_VALID_LEVEL : 7|3@0+ (1,0) [0|0] "" Vector__XXX
 SG_ CAN_TX_DETECT_STATUS : 4|1@0+ (1,0) [0|1] "" Vector__XXX
 SG_ CAN_TX_DETECT_RANGE_RATE : 55|16@0- (0.0078125,0) [-81.92|81.91] "m/s" Vector__XXX
 SG_ CAN_TX_DETECT_RANGE : 39|16@0- (0.0078125,0) [0|204.7] "m" Vector__XXX
 SG_ CAN_TX_DETECT_ANGLE : 23|16@0- (0.0078125,0) [-102.4|102.2] "deg" Vector__XXX
 SG_ CAN_TX_DETECT_AMPLITUDE : 3|12@0- (0.125,0) [-24|40] "dBsm" Vector__XXX

BO_ 1542 SODRR_DETECTION07: 8 SODRR
 SG_ CAN_TX_DETECT_VALID_LEVEL : 7|3@0+ (1,0) [0|0] "" Vector__XXX
 SG_ CAN_TX_DETECT_STATUS : 4|1@0+ (1,0) [0|1] "" Vector__XXX
 SG_ CAN_TX_DETECT_RANGE_RATE : 55|16@0- (0.0078125,0) [-81.92|81.91] "m/s" Vector__XXX
 SG_ CAN_TX_DETECT_RANGE : 39|16@0- (0.0078125,0) [0|204.7] "m" Vector__XXX
 SG_ CAN_TX_DETECT_ANGLE : 23|16@0- (0.0078125,0) [-102.4|102.2] "deg" Vector__XXX
 SG_ CAN_TX_DETECT_AMPLITUDE : 3|12@0- (0.125,0) [-24|40] "dBsm" Vector__XXX

BO_ 1541 SODRR_DETECTION06: 8 SODRR
 SG_ CAN_TX_DETECT_VALID_LEVEL : 7|3@0+ (1,0) [0|0] "" Vector__XXX
 SG_ CAN_TX_DETECT_STATUS : 4|1@0+ (1,0) [0|1] "" Vector__XXX
 SG_ CAN_TX_DETECT_RANGE_RATE : 55|16@0- (0.0078125,0) [-81.92|81.91] "m/s" Vector__XXX
 SG_ CAN_TX_DETECT_RANGE : 39|16@0- (0.0078125,0) [0|204.7] "m" Vector__XXX
 SG_ CAN_TX_DETECT_ANGLE : 23|16@0- (0.0078125,0) [-102.4|102.2] "deg" Vector__XXX
 SG_ CAN_TX_DETECT_AMPLITUDE : 3|12@0- (0.125,0) [-24|40] "dBsm" Vector__XXX

BO_ 1540 SODRR_DETECTION05: 8 SODRR
 SG_ CAN_TX_DETECT_RANGE_RATE : 55|16@0- (0.0078125,0) [-81.92|81.91] "m/s" Vector__XXX
 SG_ CAN_TX_DETECT_RANGE : 39|16@0- (0.0078125,0) [0|204.7] "m" Vector__XXX
 SG_ CAN_TX_DETECT_ANGLE : 23|16@0- (0.0078125,0) [-102.4|102.2] "deg" Vector__XXX
 SG_ CAN_TX_DETECT_AMPLITUDE : 3|12@0- (0.125,0) [-24|40] "dBsm" Vector__XXX
 SG_ CAN_TX_DETECT_VALID_LEVEL : 7|3@0+ (1,0) [0|0] "" Vector__XXX
 SG_ CAN_TX_DETECT_STATUS : 4|1@0+ (1,0) [0|1] "" Vector__XXX

BO_ 1539 SODRR_DETECTION04: 8 SODRR
 SG_ CAN_TX_DETECT_VALID_LEVEL : 7|3@0+ (1,0) [0|0] "" Vector__XXX
 SG_ CAN_TX_DETECT_STATUS : 4|1@0+ (1,0) [0|1] "" Vector__XXX
 SG_ CAN_TX_DETECT_RANGE_RATE : 55|16@0- (0.0078125,0) [-81.92|81.91] "m/s" Vector__XXX
 SG_ CAN_TX_DETECT_RANGE : 39|16@0- (0.0078125,0) [0|204.7] "m" Vector__XXX
 SG_ CAN_TX_DETECT_ANGLE : 23|16@0- (0.0078125,0) [-102.4|102.2] "deg" Vector__XXX
 SG_ CAN_TX_DETECT_AMPLITUDE : 3|12@0- (0.125,0) [-24|40] "dBsm" Vector__XXX

BO_ 1538 SODRR_DETECTION03: 8 SODRR
 SG_ CAN_TX_DETECT_VALID_LEVEL : 7|3@0+ (1,0) [0|0] "" Vector__XXX
 SG_ CAN_TX_DETECT_STATUS : 4|1@0+ (1,0) [0|1] "" Vector__XXX
 SG_ CAN_TX_DETECT_RANGE_RATE : 55|16@0- (0.0078125,0) [-81.92|81.91] "m/s" Vector__XXX
 SG_ CAN_TX_DETECT_RANGE : 39|16@0- (0.0078125,0) [0|204.7] "m" Vector__XXX
 SG_ CAN_TX_DETECT_ANGLE : 23|16@0- (0.0078125,0) [-102.4|102.2] "deg" Vector__XXX
 SG_ CAN_TX_DETECT_AMPLITUDE : 3|12@0- (0.125,0) [-24|40] "dBsm" Vector__XXX

BO_ 1537 SODRR_DETECTION02: 8 SODRR
 SG_ CAN_TX_DETECT_VALID_LEVEL : 7|3@0+ (1,0) [0|0] "" Vector__XXX
 SG_ CAN_TX_DETECT_STATUS : 4|1@0+ (1,0) [0|1] "" Vector__XXX
 SG_ CAN_TX_DETECT_RANGE_RATE : 55|16@0- (0.0078125,0) [-81.92|81.91] "m/s" Vector__XXX
 SG_ CAN_TX_DETECT_RANGE : 39|16@0- (0.0078125,0) [0|204.7] "m" Vector__XXX
 SG_ CAN_TX_DETECT_ANGLE : 23|16@0- (0.0078125,0) [-102.4|102.2] "deg" Vector__XXX
 SG_ CAN_TX_DETECT_AMPLITUDE : 3|12@0- (0.125,0) [-24|40] "dBsm" Vector__XXX

BO_ 1536 SODRR_DETECTION01: 8 SODRR
 SG_ CAN_TX_DETECT_VALID_LEVEL : 7|3@0+ (1,0) [0|0] "" Vector__XXX
 SG_ CAN_TX_DETECT_STATUS : 4|1@0+ (1,0) [0|1] "" Vector__XXX
 SG_ CAN_TX_DETECT_RANGE_RATE : 55|16@0- (0.0078125,0) [-81.92|81.91] "m/s" Vector__XXX
 SG_ CAN_TX_DETECT_RANGE : 39|16@0- (0.0078125,0) [0|204.7] "m" Vector__XXX
 SG_ CAN_TX_DETECT_ANGLE : 23|16@0- (0.0078125,0) [-102.4|102.2] "deg" Vector__XXX
 SG_ CAN_TX_DETECT_AMPLITUDE : 3|12@0- (0.125,0) [-24|40] "dBsm" Vector__XXX

BO_ 17 GW_V_VEH: 5 RS01
 SG_ ALIV_V_VEH : 8|4@1+ (1,0) [0|0] "" Vector__XXX
 SG_ CRC_V_VEH : 0|8@1+ (1,0) [0|255] "" Vector__XXX
 SG_ DVCO_VEH : 36|3@1+ (1,0) [0|0] "" Vector__XXX
 SG_ QU_V_VEH_COG : 32|4@1+ (1,0) [0|0] "" Vector__XXX
 SG_ ST_V_VEH_NSS : 12|4@1+ (1,0) [0|0] "" Vector__XXX
 SG_ V_VEH_COG : 16|16@1+ (0.015625,0) [0|350] "km/h" Vector__XXX

BO_ 19 GW_V_VEH_2: 8 RS01
 SG_ ALIV_V_VEH_2 : 52|4@1+ (1,0) [0|14] "" Vector__XXX
 SG_ CRC_V_VEH_2 : 56|8@1+ (1,0) [0|255] "" Vector__XXX
 SG_ DRVDIR_VEH_CFD : 0|4@1+ (1,0) [0|0] "" Vector__XXX
 SG_ DRVDIR_VEH_UCNFR : 16|4@1+ (1,0) [0|0] "" Vector__XXX
 SG_ ST_DYNOMOD : 4|4@1+ (1,0) [0|0] "" Vector__XXX

BO_ 16 GW_VYAW_VEH: 6 RS01
 SG_ ALIV_VYAW_VEH : 8|4@1+ (1,0) [0|0] "" Vector__XXX
 SG_ CRC_VYAW_VEH : 0|8@1+ (1,0) [0|255] "" Vector__XXX
 SG_ QU_VYAW_VEH : 44|4@1+ (1,0) [0|0] "" Vector__XXX
 SG_ VYAW_VEH : 16|16@1+ (0.005,-163.84) [-163.84|163.83] "°/s" Vector__XXX
 SG_ VYAW_VEH_ERR_AMP : 32|12@1+ (0.0125,0) [0|50] "°/s" Vector__XXX

BO_ 18 GW_STEA_FTAX_EFFV: 7 RS01
 SG_ ALIV_STEA_FTAX_EFFV : 8|4@1+ (1,0) [0|0] "" Vector__XXX
 SG_ CRC_STEA_FTAX_EFFV : 0|8@1+ (1,0) [0|255] "" Vector__XXX
 SG_ QU_STEA_FTAX_EFFV : 32|4@1+ (1,0) [0|0] "" Vector__XXX
 SG_ STEA_FTAX_EFFV : 16|16@1+ (0.002747,-90) [-90|90] "°" Vector__XXX
 SG_ STEA_FTAX_EFFV_ERR_AMP : 40|16@1+ (0.002747,0) [0|90] "°" Vector__XXX

BO_ 20 GW_BLINKEN: 2 RS01
 SG_ ST_IDC_TYP : 12|2@1+ (1,0) [0|0] "" Vector__XXX
 SG_ ST_IDC_STOP : 8|2@1+ (1,0) [0|0] "" Vector__XXX
 SG_ ST_IDC_KI : 10|2@1+ (1,0) [0|0] "" Vector__XXX
 SG_ ST_IDC : 4|3@1+ (1,0) [0|0] "" Vector__XXX
 SG_ CCLK_IDC : 0|4@1+ (1,0) [0|0] "" Vector__XXX

BO_ 6 GW_CCLK_COU_SYNCN_FLLUP: 8 RS01
 SG_ CCLK_COU_SYNCN_IDENT : 8|16@1+ (1,0) [0|65532] "" Vector__XXX
 SG_ CCLK_COU_SYNCN_OVFL : 56|2@1+ (1,0) [0|0] "" Vector__XXX
 SG_ CCLK_COU_SYNCN_TYP : 0|8@1+ (1,0) [0|0] "" Vector__XXX
 SG_ CCLK_COU_SYNCN_VL : 24|32@1+ (1,0) [0|3999999999] "" Vector__XXX

BO_ 5 GW_CCLK_COU_SYNCN_CAN: 3 RS01
 SG_ CCLK_COU_SYNCN_CAN_IDENT : 8|16@1+ (1,0) [0|65532] "" Vector__XXX
 SG_ CCLK_COU_SYNCN_CAN_SEC : 24|32@1+ (1,0) [0|4294967292] "" Vector__XXX
 SG_ CCLK_COU_SYNCN_CAN_TYP : 0|8@1+ (1,0) [0|0] "" Vector__XXX

BO_ 2000 SODRR_DSP_Timing: 8 SODRR
 SG_ CAN_TX_PRIORITIZATION_TIME : 39|8@0+ (1,0) [0|0] "ms" Vector__XXX
 SG_ CAN_TX_RDD_TIME : 31|8@0+ (1,0) [0|0] "ms" Vector__XXX
 SG_ CAN_TX_BEAMFORM_TIME : 23|8@0+ (1,0) [0|0] "ms" Vector__XXX
 SG_ CAN_TX_LL_TOTAL_TIME : 15|8@0+ (1,0) [0|0] "ms" Vector__XXX
 SG_ CAN_TX_ML_TOTAL_TIME : 7|8@0+ (1,0) [0|0] "ms" Vector__XXX

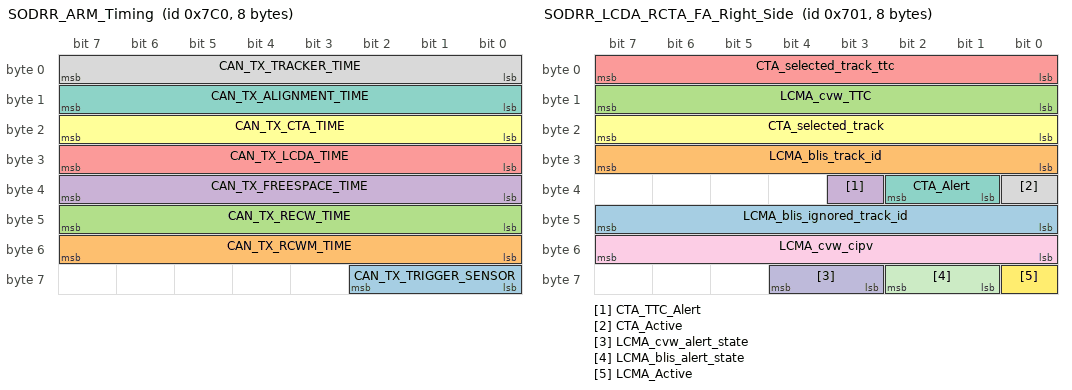
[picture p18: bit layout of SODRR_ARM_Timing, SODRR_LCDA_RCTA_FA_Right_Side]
BO_ 1984 SODRR_ARM_Timing: 8 SODRR
 SG_ CAN_TX_TRIGGER_SENSOR : 58|3@0+ (1,0) [0|0] "" Vector__XXX
 SG_ CAN_TX_RCWM_TIME : 55|8@0+ (1,0) [0|0] "ms" Vector__XXX
 SG_ CAN_TX_RECW_TIME : 47|8@0+ (1,0) [0|0] "ms" Vector__XXX
 SG_ CAN_TX_FREESPACE_TIME : 39|8@0+ (1,0) [0|0] "ms" Vector__XXX
 SG_ CAN_TX_LCDA_TIME : 31|8@0+ (1,0) [0|0] "ms" Vector__XXX
 SG_ CAN_TX_CTA_TIME : 23|8@0+ (1,0) [0|0] "ms" Vector__XXX
 SG_ CAN_TX_ALIGNMENT_TIME : 15|8@0+ (1,0) [0|0] "ms" Vector__XXX
 SG_ CAN_TX_TRACKER_TIME : 7|8@0+ (1,0) [0|0] "ms" Vector__XXX

BO_ 1793 SODRR_LCDA_RCTA_FA_Right_Side: 8 SODRR
 SG_ LCMA_blis_ignored_track_id : 47|8@0+ (1,0) [0|0] "" Vector__XXX
 SG_ LCMA_blis_track_id : 31|8@0+ (1,0) [0|0] "" Vector__XXX
 SG_ LCMA_cvw_TTC : 15|8@0+ (0.1,0) [0|0] "seconds" Vector__XXX
 SG_ CTA_TTC_Alert : 35|1@0+ (1,0) [0|0] "" Vector__XXX
 SG_ CTA_selected_track_ttc : 7|8@0+ (0.1,0) [0|25.5] "seconds" Vector__XXX
 SG_ CTA_selected_track : 23|8@0+ (1,0) [0|256] "" Vector__XXX
 SG_ CTA_Alert : 34|2@0+ (1,0) [0|3] "binary" Vector__XXX
 SG_ CTA_Active : 32|1@0+ (1,0) [0|0] "binary" Vector__XXX
 SG_ LCMA_cvw_cipv : 55|8@0+ (1,0) [0|0] "" Vector__XXX
 SG_ LCMA_cvw_alert_state : 60|2@0+ (1,0) [0|0] "" Vector__XXX
 SG_ LCMA_blis_alert_state : 58|2@0+ (1,0) [0|0] "" Vector__XXX
 SG_ LCMA_Active : 56|1@0+ (1,0) [0|0] "" Vector__XXX

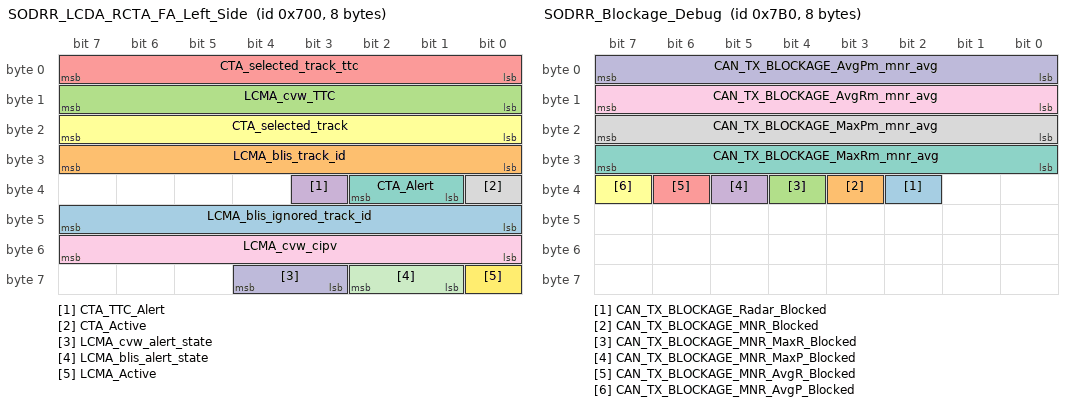
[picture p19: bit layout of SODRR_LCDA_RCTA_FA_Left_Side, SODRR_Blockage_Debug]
BO_ 1792 SODRR_LCDA_RCTA_FA_Left_Side: 8 SODRR
 SG_ LCMA_blis_ignored_track_id : 47|8@0+ (1,0) [0|0] "" Vector__XXX
 SG_ LCMA_blis_track_id : 31|8@0+ (1,0) [0|0] "" Vector__XXX
 SG_ LCMA_cvw_TTC : 15|8@0+ (0.1,0) [0|0] "seconds" Vector__XXX
 SG_ CTA_TTC_Alert : 35|1@0+ (1,0) [0|0] "" Vector__XXX
 SG_ CTA_selected_track_ttc : 7|8@0+ (0.1,0) [0|25.5] "seconds" Vector__XXX
 SG_ CTA_selected_track : 23|8@0+ (1,0) [0|256] "" Vector__XXX
 SG_ CTA_Alert : 34|2@0+ (1,0) [0|3] "binary" Vector__XXX
 SG_ CTA_Active : 32|1@0+ (1,0) [0|0] "binary" Vector__XXX
 SG_ LCMA_cvw_cipv : 55|8@0+ (1,0) [0|0] "" Vector__XXX
 SG_ LCMA_cvw_alert_state : 60|2@0+ (1,0) [0|0] "" Vector__XXX
 SG_ LCMA_blis_alert_state : 58|2@0+ (1,0) [0|0] "" Vector__XXX
 SG_ LCMA_Active : 56|1@0+ (1,0) [0|0] "" Vector__XXX

BO_ 1968 SODRR_Blockage_Debug: 8 SODRR
 SG_ CAN_TX_BLOCKAGE_Radar_Blocked : 34|1@0+ (1,0) [0|0] "" Vector__XXX
 SG_ CAN_TX_BLOCKAGE_MNR_Blocked : 35|1@0+ (1,0) [0|0] "" Vector__XXX
 SG_ CAN_TX_BLOCKAGE_MNR_MaxR_Blocked : 36|1@0+ (1,0) [0|0] "" Vector__XXX
 SG_ CAN_TX_BLOCKAGE_MNR_MaxP_Blocked : 37|1@0+ (1,0) [0|0] "" Vector__XXX
 SG_ CAN_TX_BLOCKAGE_MNR_AvgR_Blocked : 38|1@0+ (1,0) [0|0] "" Vector__XXX
 SG_ CAN_TX_BLOCKAGE_MNR_AvgP_Blocked : 39|1@0+ (1,0) [0|0] "" Vector__XXX
 SG_ CAN_TX_BLOCKAGE_MaxRm_mnr_avg : 31|8@0+ (1,0) [0|0] "m" Vector__XXX
 SG_ CAN_TX_BLOCKAGE_MaxPm_mnr_avg : 23|8@0+ (1,0) [0|0] "dB" Vector__XXX
 SG_ CAN_TX_BLOCKAGE_AvgRm_mnr_avg : 15|8@0+ (1,0) [0|0] "m" Vector__XXX
 SG_ CAN_TX_BLOCKAGE_AvgPm_mnr_avg : 7|8@0+ (1,0) [0|0] "dB" Vector__XXX
